VERSION ""

NS_ :

BS_:

BU_: BCM BSM2 CADM2 CVADAS EPS ORC PAM SGW TRSKM

BO_ 2564682031 DIAGNOSTIC_ROE_CADM2: 8 CADM2
 SG_ N_PDU : 7|64@0+ (1,0) [0|0] ""  SGW

BO_ 2564682032 DIAGNOSTIC_ROE_EPS: 8 EPS
 SG_ N_PDU : 7|64@0+ (1,0) [0|0] ""  SGW

BO_ 2564682275 DIAGNOSTIC_ROE_FD_BSM2: 64 BSM2
 SG_ N_PDU : 7|64@0+ (1,0) [0|0] ""  SGW

BO_ 2564682287 DIAGNOSTIC_ROE_FD_CADM2: 64 CADM2
 SG_ N_PDU : 7|64@0+ (1,0) [0|0] ""  SGW

BO_ 2564682288 DIAGNOSTIC_ROE_FD_EPS: 64 EPS
 SG_ N_PDU : 7|64@0+ (1,0) [0|0] ""  SGW

BO_ 2564682432 DIAGNOSTIC_ROE_FD_ORC: 64 ORC
 SG_ N_PDU : 7|64@0+ (1,0) [0|0] ""  SGW

BO_ 2564682400 DIAGNOSTIC_ROE_FD_PAM: 64 PAM
 SG_ N_PDU : 7|64@0+ (1,0) [0|0] ""  SGW

BO_ 2564682476 DIAGNOSTIC_ROE_FD_TRLR_REV: 64 TRSKM
 SG_ N_PDU : 7|64@0+ (1,0) [0|0] ""  SGW

BO_ 2564682176 DIAGNOSTIC_ROE_ORC: 8 ORC
 SG_ N_PDU : 7|64@0+ (1,0) [0|0] ""  SGW

BO_ 2564682144 DIAGNOSTIC_ROE_PAM: 8 PAM
 SG_ N_PDU : 7|64@0+ (1,0) [0|0] ""  SGW

BO_ 2564682220 DIAGNOSTIC_ROE_TRLR_REV: 8 TRSKM
 SG_ N_PDU : 7|64@0+ (1,0) [0|0] ""  SGW

BO_ 517 DRIVETRAIN_FD_1: 32 BCM
 SG_ AWDSysStat : 87|3@0+ (1,0) [0|7] "-"  BSM2,ORC
 SG_ CCMFailSts : 83|1@0+ (1,0) [0|1] "-"  BSM2,ORC
 SG_ CRC_DRIVETRAIN1 : 191|8@0+ (1,0) [0|255] "-"  BSM2
 SG_ Ft_RrCouplingTrq_Actual : 103|8@0+ (12,0) [1|3000] "Nm"  BSM2
 SG_ MessageCounter_DRIVETRAIN1 : 179|4@0+ (1,0) [0|15] "-"  BSM2

BO_ 1068 DRIVETRAIN_FD_3: 32 BCM
 SG_ CRC__DRIVETRAIN3 : 191|8@0+ (1,0) [0|255] "-"  BSM2,CVADAS,EPS
 SG_ MessageCounter_DRIVETRAIN3 : 179|4@0+ (1,0) [0|15] "-"  BSM2,CVADAS,EPS
 SG_ TCASERANGESTATUS : 89|2@0+ (1,0) [0|2] ""  CVADAS,EPS,PAM

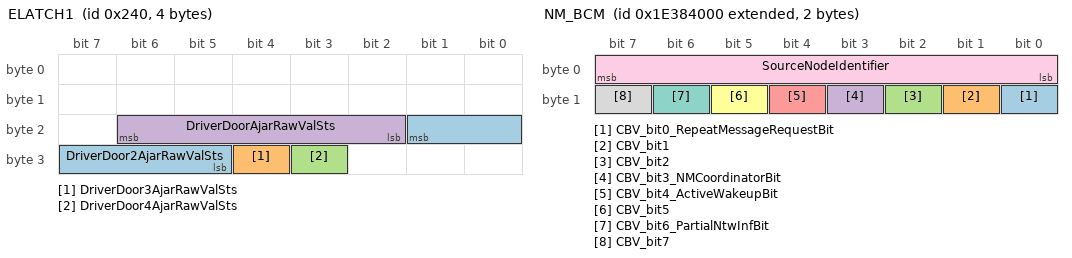
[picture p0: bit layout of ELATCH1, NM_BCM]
BO_ 576 ELATCH1: 4 BCM
 SG_ DriverDoor2AjarRawValSts : 17|5@0+ (1,0) [0|31] ""  ORC
 SG_ DriverDoor3AjarRawValSts : 28|1@0+ (1,0) [0|1] ""  ORC
 SG_ DriverDoor4AjarRawValSts : 27|1@0+ (1,0) [0|1] ""  ORC
 SG_ DriverDoorAjarRawValSts : 22|5@0+ (1,0) [0|31] ""  ORC

BO_ 1054 ENGINE_FD_1: 32 BCM
 SG_ BrkSw1Stat : 4|1@0+ (1,0) [0|1] "-"  ORC
 SG_ BrkSw2Stat : 5|1@0+ (1,0) [0|1] "-"  ORC
 SG_ ESP_TrqRqEnabl : 6|1@0+ (1,0) [0|1] "-"  ORC
 SG_ Lv1CrsCtrlOff : 7|1@0+ (1,0) [0|1] "-"  ORC
 SG_ RawPVS1 : 167|8@0+ (0.019607843,0) [0|4.98] "V"  ORC
 SG_ RawPVS2 : 175|8@0+ (0.019607843,0) [0|4.98] "V"  ORC
 SG_ RawTPS1 : 63|8@0+ (0.019607843,0) [0|4.98] "V"  ORC
 SG_ RawTPS2 : 55|8@0+ (0.019607843,0) [0|4.98] "V"  ORC
 SG_ ThrottlePosition : 87|8@0+ (0.392,0) [0|99.96] "%"  ORC

BO_ 262 ENGINE_FD_2: 64 BCM
 SG_ CRC_ENGINE2 : 447|8@0+ (1,0) [0|255] "-"  CADM2,CVADAS,EPS,PAM
 SG_ EngineSpeed_W : 21|14@0+ (1,0) [0|16382] "1/min"  CADM2,EPS,ORC
 SG_ EngineSpeedFailSts_W : 168|1@0+ (1,0) [0|1] "-"  ORC
 SG_ EngineSts_W : 87|2@0+ (1,0) [0|3] "-"  CVADAS,EPS
 SG_ EngTrq_Enbl_Rq_TCM_W : 178|1@0+ (1,0) [0|1] "-"  ORC
 SG_ ESS_ENG_ST_W : 175|4@0+ (1,0) [0|15] "-"  CADM2,CVADAS,EPS,ORC,PAM
 SG_ ESS_RqShftPark_W : 115|1@0+ (1,0) [0|0] "-"  ORC
 SG_ GasPedalPositionFailSts_W : 169|1@0+ (1,0) [0|1] "-"  ORC
 SG_ MessageCounter_ENGINE2 : 435|4@0+ (1,0) [0|15] "-"  CADM2,CVADAS,EPS,PAM
 SG_ PowertrainPrplsnActv : 181|1@0+ (1,0) [0|1] ""  CADM2,EPS,ORC

BO_ 518 ENGINE_FD_5: 32 BCM
 SG_ CRC_ENGINE5 : 191|8@0+ (1,0) [0|255] "-"  CVADAS,BSM2,CADM2
 SG_ MessageCounter_ENGINE5 : 179|4@0+ (1,0) [0|15] "-"  CVADAS,BSM2,CADM2
 SG_ PdlPosActual : 87|8@0+ (0.4,0) [0|100] "%"  BSM2,CADM2,CVADAS,ORC

BO_ 751 ENGINE_FD_6: 32 BCM
 SG_ TerrainModeStat_ECM : 61|5@0+ (1,0) [0|30] ""  ORC

BO_ 1448 ENGINE_FD_7: 32 BCM
 SG_ CRC_ENGINE7 : 191|8@0+ (1,0) [0|255] "-"  CVADAS
 SG_ ECM_THA_Resp : 73|2@0+ (1,0) [0|2] "-"  CVADAS
 SG_ ECM_TRSC_Resp : 7|2@0+ (1,0) [0|2] "-"  CVADAS
 SG_ EMSFailSts : 82|2@0+ (1,0) [0|3] "-"  ORC
 SG_ ETCFailSts : 115|2@0+ (1,0) [0|3] "-"  ORC
 SG_ MessageCounter_ENGINE7 : 179|4@0+ (1,0) [0|15] "-"  CVADAS
 SG_ SpStDispstat : 53|6@0+ (1,0) [0|63] "-"  ORC
 SG_ SpStSwStat : 55|2@0+ (1,0) [0|3] "-"  ORC

BO_ 1055 ENGINE_FD_8: 32 BCM
 SG_ GF_Charge : 127|16@0+ (0.2,0) [0|13106.8] "mg/cycle/cyl"  ORC
 SG_ MAP_4_BAR : 96|9@0+ (0.8,0) [0|408] "kPa"  ORC

BO_ 264 EPS_FD_1: 32 EPS
 SG_ CRC_EPS1 : 191|8@0+ (1,0) [0|255] "-"  BCM,BSM2,CADM2,CVADAS,ORC,PAM
 SG_ ElectricSteeringFailSts : 37|1@0+ (1,0) [0|1] "-"  BCM,SGW
 SG_ EngineFanRequestActivation : 38|1@0+ (1,0) [0|1] "-"  BCM
 SG_ EPS_AsstStat : 55|3@0+ (1,0) [0|6] "-"  CADM2
 SG_ EPS_Curr : 87|8@0+ (1,-50) [-50|204] "Amp" Vector__XXX
 SG_ EPS_Hands_On_Sts : 67|1@0+ (1,0) [0|1] "-"  CADM2
 SG_ EPS_IMC_Fault : 68|1@0+ (1,0) [0|1] ""  CADM2
 SG_ EPSMotorTorque : 66|11@0+ (0.004882815,-5) [-5|4.99023949] "Nm"  CADM2
 SG_ HAS_LAT_CTRL_ResponseSts_2 : 98|3@0+ (1,0) [0|7] "-"  CADM2
 SG_ LwsAngle : 7|16@0+ (0.1,-720) [-720|720] "°"  BCM,BSM2,CADM2,CVADAS,ORC,PAM,SGW
 SG_ LwsAngleType : 52|2@0+ (1,0) [0|2] "-"  BCM,BSM2,CADM2,CVADAS,ORC,SGW
 SG_ LwsCalibration : 36|1@0+ (1,0) [0|1] "-"  BCM,BSM2,SGW
 SG_ LwsSpeed : 19|12@0+ (1,-2000) [-2000|2094] "°/s"  BCM,CADM2,CVADAS,PAM,SGW
 SG_ MessageCounter_EPS1 : 179|4@0+ (1,0) [0|15] "-"  BCM,BSM2,CADM2,CVADAS,ORC,PAM
 SG_ Steering_Column_Torque : 50|11@0+ (0.0078125,-8) [-8|7.984375] "NM"  CADM2,ORC
 SG_ Steering_OpStat_Sec : 108|3@0+ (1,0) [0|5] ""  CADM2,ORC

BO_ 1056 EPS_FD_2: 32 EPS
 SG_ CRC_EPS2 : 191|8@0+ (1,0) [0|255] "0"  CVADAS
 SG_ EPS_MODE_STAT : 7|3@0+ (1,0) [0|3] ""  ORC,SGW
 SG_ EPS_SteeringTouchStat : 4|1@0+ (1,0) [0|1] ""  CVADAS
 SG_ EPS_SteeringTouq_Resp : 3|2@0+ (1,0) [0|1] ""  CVADAS
 SG_ EPS_THA_DriverTorqueOverride : 1|2@0+ (1,0) [0|1] ""  CVADAS
 SG_ EPS_THA_SteeringTorqueResp : 13|3@0+ (1,0) [0|6] ""  CVADAS
 SG_ EPS_Warn_Disp_Rq : 87|3@0+ (1,0) [0|3] ""  BCM,ORC,SGW
 SG_ MessageCounter_EPS2 : 179|4@0+ (1,0) [0|15] "0"  CVADAS
 SG_ THA_SteeringTouchStat : 15|2@0+ (1,0) [0|1] ""  CVADAS

BO_ 1460 FOTA_MASTER: 32 SGW
 SG_ CADM2_Big_ECU_Package : 2|1@0+ (1,0) [0|1] ""  CADM2
 SG_ FOTA_Purge : 13|1@0+ (1,0) [0|1] ""  CADM2
 SG_ FOTA_Status : 7|4@0+ (1,0) [0|15] ""  CADM2,EPS,ORC
 SG_ Safe_State : 0|1@0+ (1,0) [0|1] ""  CADM2

BO_ 1847 FOTA_RSP_CADM2: 32 CADM2
 SG_ Big_ECU_Ready_CADM2 : 3|2@0+ (1,0) [0|3] ""  SGW
 SG_ Download_Status_CADM2 : 7|2@0+ (1,0) [0|3] ""  SGW
 SG_ Update_Status_CADM2 : 5|2@0+ (1,0) [0|3] ""  SGW

BO_ 525 GLOB_NAV_FD: 64 BCM
 SG_ CRC_GLOB_NAV : 447|8@0+ (1,0) [0|255] "-"  CADM2
 SG_ GNMM_Health : 7|4@0+ (1,0) [0|6] ""  CADM2
 SG_ MessageCounter_GLOB_NAV : 435|4@0+ (1,0) [0|15] "-"  CADM2

BO_ 526 GLOB_NAV_FD_C2: 32 CADM2
 SG_ Altitude_RMSE_C2 : 143|8@0+ (2,0) [0|506] "cm"  CVADAS
 SG_ CRC_GLOB_NAV_C2 : 191|8@0+ (1,0) [0|255] "-"  CVADAS
 SG_ DeltaTimestamp_IMUdata : 175|8@0+ (1,0) [0|253] "ms"  CVADAS
 SG_ Heading_Angle_C2 : 127|16@0+ (0.01,0) [0|360] "deg"  CVADAS
 SG_ LatAcceleration_C2 : 19|12@0+ (0.02,-40.96) [-40.96|40.92] "m/s2"  CVADAS
 SG_ Latitude_RMSE_C2 : 103|8@0+ (2,0) [0|506] "cm"  CVADAS
 SG_ LongAcceleration_C2 : 3|12@0+ (0.02,-40.96) [-40.96|40.92] "m/s2"  CVADAS
 SG_ Longitude_RMSE_C2 : 111|8@0+ (2,0) [0|506] "cm"  CVADAS
 SG_ MessageCounter_GLOB_NAV_C2 : 179|4@0+ (1,0) [0|15] "-"  CVADAS
 SG_ Pitch_RMSE_C2 : 159|8@0+ (2,0) [0|506] "deg"  CVADAS
 SG_ PitchRate_C2 : 83|12@0+ (0.08,-163.84) [-163.84|163.68] "deg/s"  CVADAS
 SG_ Roll_RMSE_C2 : 151|8@0+ (2,0) [0|506] "deg"  CVADAS
 SG_ RollRate_C2 : 67|12@0+ (0.08,-163.84) [-163.84|163.68] "deg/s"  CVADAS
 SG_ VerticalAcceleration_C2 : 35|12@0+ (0.02,-40.96) [-40.96|40.92] "m/s2"  CVADAS
 SG_ YawRate_C2 : 51|12@0+ (0.08,-163.84) [-163.84|163.68] "deg/s"  CVADAS
 SG_ YawRate_RMSE_C2 : 119|8@0+ (2,0) [0|506] "deg"  CVADAS

BO_ 266 HVBATTERY1: 32 BCM
 SG_ HVBatContactorSts : 23|3@0+ (1,0) [0|0] "-"  ORC

BO_ 1049 HYBRID_DISPLAY: 32 BCM
 SG_ HVBatterySOC_Display : 119|8@0+ (0.3922,0) [0|100] "%"  ORC

BO_ 276 HYBRID_POWERTRAIN1: 64 BCM
 SG_ PropulsionSystemActive : 408|1@0+ (1,0) [0|1] "-"  EPS

BO_ 269 HYBRID_POWERTRAIN2: 64 BCM
 SG_ BSGActualTorque : 257|10@0+ (0.32,-163.52) [-163.52|163.2] "Nm"  ORC
 SG_ ReqTorqueOverLayActive : 297|1@0+ (1,0) [0|1] "-"  ORC

BO_ 752 IBS3_DATA_1: 32 BCM
 SG_ CurrBattFailStatus : 103|1@0+ (1,0) [0|1] "" Vector__XXX
 SG_ IBS3_Error_Internal : 101|1@0+ (1,0) [0|1] "" Vector__XXX
 SG_ IBS3_Vbatt : 96|9@0+ (0.025,5) [5|17.75] "V"  ORC
 SG_ RsErrIBS3 : 100|1@0+ (1,0) [0|1] "" Vector__XXX
 SG_ VoltBattFailStatus : 102|1@0+ (1,0) [0|1] "" Vector__XXX

BO_ 754 IBS3_DATA_1_2: 32 BCM
 SG_ CurrBattFailStatus_2 : 103|1@0+ (1,0) [0|1] "" Vector__XXX
 SG_ IBS3_Error_Internal_2 : 101|1@0+ (1,0) [0|1] "" Vector__XXX
 SG_ IBS3_Ibatt_2 : 87|16@0+ (0.02,-1000) [-1000|310.68] "A" Vector__XXX
 SG_ IBS3_Vbatt_2 : 96|9@0+ (0.025,5) [5|17.75] "V" Vector__XXX
 SG_ RsErrIBS3_2 : 100|1@0+ (1,0) [0|1] "" Vector__XXX
 SG_ VoltBattFailStatus_2 : 102|1@0+ (1,0) [0|1] "" Vector__XXX

BO_ 1955 IBS3_DATA_2: 32 BCM
 SG_ IBS3_CRC_IBS_1 : 15|8@0+ (1,0) [0|254] ""  CADM2
 SG_ IBS3_CRC_IBS_2 : 71|8@0+ (1,0) [0|254] ""  CADM2
 SG_ IBS3_FLAG_DISCONNECT_ADAS : 1|2@0+ (1,0) [0|2] "" Vector__XXX
 SG_ IBS3_FLAG_DISCONNECT_ADAS_2 : 17|2@0+ (1,0) [0|2] "" Vector__XXX
 SG_ IBS3_IBS_ADAS_OK : 3|2@0+ (1,0) [0|2] ""  CADM2
 SG_ IBS3_IBS_ADAS_OK_2 : 19|2@0+ (1,0) [0|2] ""  CADM2
 SG_ IBS3_MC_IBS_1 : 7|4@0+ (1,0) [0|15] ""  CADM2
 SG_ IBS3_MC_IBS_2 : 23|4@0+ (1,0) [0|15] ""  CADM2
 SG_ IBS3_SOC : 86|7@0+ (1,0) [0|100] "%"  ORC
 SG_ IBS3_SOC_Accuracy : 87|1@0+ (1,0) [0|1] "" Vector__XXX

BO_ 1957 IBS3_DATA_2_2: 32 BCM
 SG_ IBS3_FLAG_DISCONNECT_2 : 117|1@0+ (1,0) [0|0] "" Vector__XXX
 SG_ IBS3_Q_Received_2 : 159|16@0+ (0.125,0) [0|8191.75] "Ah" Vector__XXX
 SG_ IBS3_Q_Released_2 : 31|16@0+ (0.125,0) [0|8191.75] "Ah" Vector__XXX
 SG_ IBS3_R_Batt_2 : 63|8@0+ (0.1,0) [0|25.4] "mOhm" Vector__XXX
 SG_ IBS3_R_Batt_25_2 : 79|8@0+ (0.1,0) [0|25.4] "mOhm" Vector__XXX
 SG_ IBS3_SOC_2 : 86|7@0+ (1,0) [0|100] "%"  SGW
 SG_ IBS3_SOC_Accuracy_2 : 87|1@0+ (1,0) [0|0] ""  SGW
 SG_ IBS3_SOF_Q_2 : 103|8@0+ (1,0) [0|254] "Ah" Vector__XXX
 SG_ IBS3_SOF_Q_Accuracy_2 : 118|1@0+ (1,0) [0|0] "" Vector__XXX
 SG_ IBS3_SOH_COR_2 : 46|7@0+ (1,0) [0|100] "%" Vector__XXX
 SG_ IBS3_SOH_COR_Accuracy_2 : 47|1@0+ (1,0) [0|0] "" Vector__XXX
 SG_ IBS3_SOH_Q_2 : 110|7@0+ (2,0) [0|252] "Ah" Vector__XXX
 SG_ IBS3_SOH_Q_Accuracy_2 : 119|1@0+ (1,0) [0|0] "" Vector__XXX
 SG_ IBS3_SOH_SUL_2 : 54|7@0+ (1,0) [0|100] "%" Vector__XXX
 SG_ IBS3_SOH_SUL_Accuracy_2 : 55|1@0+ (1,0) [0|0] "" Vector__XXX
 SG_ IBS3_T_BATT_2 : 95|8@0+ (1,-40) [-40|105] "°C"  SGW
 SG_ IBS3_TempFailStatus_2 : 111|1@0+ (1,0) [0|0] ""  SGW
 SG_ IBS3_TmLstResetDays_2 : 139|12@0+ (1,0) [0|4094] "Days" Vector__XXX
 SG_ IBS3_TmLstResetSec_2 : 127|16@0+ (2,0) [0|86398] "sec" Vector__XXX

BO_ 1626 IMPACT_INFO: 32 ORC
 SG_ CRC_IMPACTINFO : 191|8@0+ (1,0) [0|255] "-"  BCM,SGW
 SG_ IMPACT_B : 84|1@0+ (1,0) [0|1] "-"  CADM2,SGW
 SG_ IMPACT_C : 85|1@0+ (1,0) [0|1] "-"  CADM2,SGW
 SG_ IMPACT_F : 88|1@0+ (1,0) [0|1] "-"  CADM2,SGW
 SG_ IMPACT_I : 91|1@0+ (1,0) [0|1] "-"  CADM2,SGW
 SG_ IMPACT_K : 92|1@0+ (1,0) [0|1] "-"  CADM2,SGW
 SG_ IMPACT_M : 94|1@0+ (1,0) [0|1] "-"  CADM2,SGW
 SG_ IMPACTCommand : 80|1@0+ (1,0) [0|1] "-"  BCM,CADM2,SGW
 SG_ IMPACTConfirm : 81|1@0+ (1,0) [0|1] "-"  BCM,CADM2,SGW
 SG_ IMPACTFailSts : 82|1@0+ (1,0) [0|1] "-"  SGW
 SG_ IMPACTThreshold : 103|1@0+ (1,0) [0|1] "-"  BCM
 SG_ MessageCounter_IMPACTINFO : 179|4@0+ (1,0) [0|15] "-"  BCM,SGW

BO_ 1829 IPC_FD_1: 32 BCM
 SG_ CRC_IPC1 : 191|8@0+ (1,0) [0|255] "-"  BSM2,CADM2
 SG_ MessageCounter_IPC1 : 179|4@0+ (1,0) [0|15] "-"  BSM2,CADM2
 SG_ TotalOdometer : 75|20@0+ (1,0) [0|1048575] "km"  BSM2,CADM2,CVADAS,EPS,ORC,PAM,TRSKM

BO_ 600 IPC_FD_4: 32 BCM
 SG_ AirBagLamp_FailSts : 143|2@0+ (1,0) [0|3] "-"  ORC

BO_ 1432 IPC_FD_6: 32 BCM
 SG_ CRC_IPC6 : 191|8@0+ (1,0) [0|255] "-"  CADM2
 SG_ HAS_SoH_IPC : 76|1@0+ (1,0) [0|1] ""  CADM2
 SG_ MessageCounter_IPC6 : 179|4@0+ (1,0) [0|15] "-"  CADM2

BO_ 1443 IPC_VEHICLE_SETUP: 48 BCM
 SG_ Act_Lane_Mgt : 91|2@0+ (1,0) [0|3] "-"  ORC
 SG_ Act_Lane_Mgt_Strength : 123|2@0+ (1,0) [0|3] "-"  ORC
 SG_ Active_Park_Mode : 219|1@0+ (1,0) [0|1] ""  CVADAS
 SG_ Backup_Cam_Delay : 173|1@0+ (1,0) [0|1] "-"  CVADAS
 SG_ DynamicGrid : 100|1@0+ (1,0) [0|1] ""  CVADAS
 SG_ Fwrd_Cam_Guidelines : 189|1@0+ (1,0) [0|1] "-"  CVADAS
 SG_ LanguageSelection : 135|8@0+ (1,0) [0|255] "-"  CVADAS
 SG_ LDW_Intensity : 154|2@0+ (1,0) [0|3] "-"  ORC
 SG_ LDW_Sensibility : 147|2@0+ (1,0) [0|3] "-"  ORC
 SG_ PamChimeVolumeFront : 107|2@0+ (1,0) [0|3] ""  CVADAS,PAM
 SG_ PamChimeVolumeRear : 111|2@0+ (1,0) [0|3] ""  CVADAS,PAM
 SG_ Rear_Brk_Asst : 190|1@0+ (1,0) [0|1] ""  CVADAS,PAM
 SG_ SVC_Guidelines : 193|1@0+ (1,0) [0|1] ""  CVADAS

BO_ 2654486528 NM_BCM: 2 BCM
 SG_ CBV_bit0_RepeatMessageRequestBit : 8|1@0+ (1,0) [0|1] ""  BSM2,CADM2,CVADAS,EPS,ORC,SGW,TRSKM
 SG_ CBV_bit1 : 9|1@0+ (1,0) [0|1] ""  BSM2,CADM2,CVADAS,EPS,ORC,SGW,TRSKM
 SG_ CBV_bit2 : 10|1@0+ (1,0) [0|1] ""  BSM2,CADM2,CVADAS,EPS,ORC,SGW,TRSKM
 SG_ CBV_bit3_NMCoordinatorBit : 11|1@0+ (1,0) [0|1] ""  BSM2,CADM2,CVADAS,EPS,ORC,SGW,TRSKM
 SG_ CBV_bit4_ActiveWakeupBit : 12|1@0+ (1,0) [0|1] ""  BSM2,CADM2,CVADAS,EPS,ORC,SGW,TRSKM
 SG_ CBV_bit5 : 13|1@0+ (1,0) [0|1] ""  BSM2,CADM2,CVADAS,EPS,ORC,SGW,TRSKM
 SG_ CBV_bit6_PartialNtwInfBit : 14|1@0+ (1,0) [0|1] ""  BSM2,CADM2,CVADAS,EPS,ORC,SGW,TRSKM
 SG_ CBV_bit7 : 15|1@0+ (1,0) [0|1] ""  BSM2,CADM2,CVADAS,EPS,ORC,SGW,TRSKM
 SG_ SourceNodeIdentifier : 7|8@0+ (1,0) [0|255] "-"  BSM2,CADM2,CVADAS,EPS,ORC,SGW,TRSKM

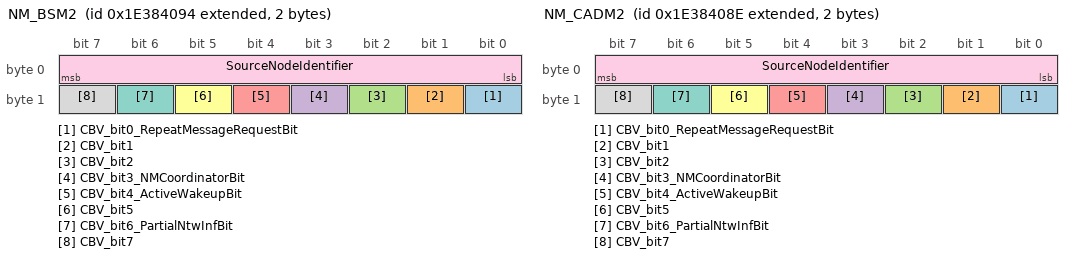
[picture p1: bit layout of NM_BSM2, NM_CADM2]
BO_ 2654486676 NM_BSM2: 2 BSM2
 SG_ CBV_bit0_RepeatMessageRequestBit : 8|1@0+ (1,0) [0|1] ""  BCM,CADM2,CVADAS,EPS,ORC,SGW,TRSKM
 SG_ CBV_bit1 : 9|1@0+ (1,0) [0|1] ""  BCM,CADM2,CVADAS,EPS,ORC,SGW,TRSKM
 SG_ CBV_bit2 : 10|1@0+ (1,0) [0|1] ""  BCM,CADM2,CVADAS,EPS,ORC,SGW,TRSKM
 SG_ CBV_bit3_NMCoordinatorBit : 11|1@0+ (1,0) [0|1] ""  BCM,CADM2,CVADAS,EPS,ORC,SGW,TRSKM
 SG_ CBV_bit4_ActiveWakeupBit : 12|1@0+ (1,0) [0|1] ""  BCM,CADM2,CVADAS,EPS,ORC,SGW,TRSKM
 SG_ CBV_bit5 : 13|1@0+ (1,0) [0|1] ""  BCM,CADM2,CVADAS,EPS,ORC,SGW,TRSKM
 SG_ CBV_bit6_PartialNtwInfBit : 14|1@0+ (1,0) [0|1] ""  BCM,CADM2,CVADAS,EPS,ORC,SGW,TRSKM
 SG_ CBV_bit7 : 15|1@0+ (1,0) [0|1] ""  BCM,CADM2,CVADAS,EPS,ORC,SGW,TRSKM
 SG_ SourceNodeIdentifier : 7|8@0+ (1,0) [0|255] "-"  BCM,CADM2,CVADAS,EPS,ORC,SGW,TRSKM

BO_ 2654486670 NM_CADM2: 2 CADM2
 SG_ CBV_bit0_RepeatMessageRequestBit : 8|1@0+ (1,0) [0|1] ""  BCM,BSM2,CVADAS,EPS,ORC,SGW,TRSKM
 SG_ CBV_bit1 : 9|1@0+ (1,0) [0|1] ""  BCM,BSM2,CVADAS,EPS,ORC,SGW,TRSKM
 SG_ CBV_bit2 : 10|1@0+ (1,0) [0|1] ""  BCM,BSM2,CVADAS,EPS,ORC,SGW,TRSKM
 SG_ CBV_bit3_NMCoordinatorBit : 11|1@0+ (1,0) [0|1] ""  BCM,BSM2,CVADAS,EPS,ORC,SGW,TRSKM
 SG_ CBV_bit4_ActiveWakeupBit : 12|1@0+ (1,0) [0|1] ""  BCM,BSM2,CVADAS,EPS,ORC,SGW,TRSKM
 SG_ CBV_bit5 : 13|1@0+ (1,0) [0|1] ""  BCM,BSM2,CVADAS,EPS,ORC,SGW,TRSKM
 SG_ CBV_bit6_PartialNtwInfBit : 14|1@0+ (1,0) [0|1] ""  BCM,BSM2,CVADAS,EPS,ORC,SGW,TRSKM
 SG_ CBV_bit7 : 15|1@0+ (1,0) [0|1] ""  BCM,BSM2,CVADAS,EPS,ORC,SGW,TRSKM
 SG_ SourceNodeIdentifier : 7|8@0+ (1,0) [0|255] "-"  BCM,BSM2,CVADAS,EPS,ORC,SGW,TRSKM

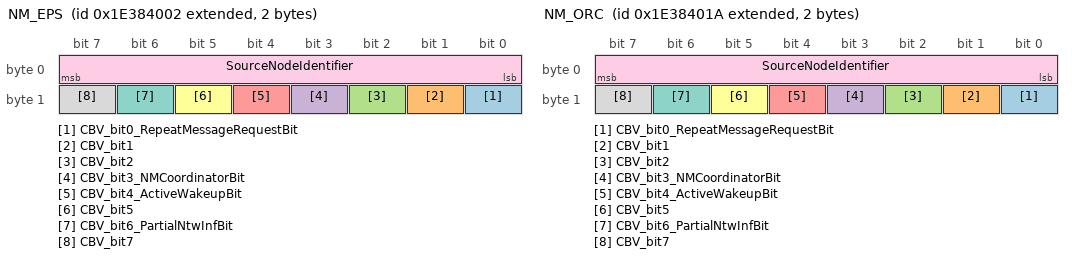
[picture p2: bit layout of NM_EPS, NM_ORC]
BO_ 2654486530 NM_EPS: 2 EPS
 SG_ CBV_bit0_RepeatMessageRequestBit : 8|1@0+ (1,0) [0|1] ""  BCM,BSM2,CADM2,CVADAS,ORC,SGW,TRSKM
 SG_ CBV_bit1 : 9|1@0+ (1,0) [0|1] ""  BCM,BSM2,CADM2,CVADAS,ORC,SGW,TRSKM
 SG_ CBV_bit2 : 10|1@0+ (1,0) [0|1] ""  BCM,BSM2,CADM2,CVADAS,ORC,SGW,TRSKM
 SG_ CBV_bit3_NMCoordinatorBit : 11|1@0+ (1,0) [0|1] ""  BCM,BSM2,CADM2,CVADAS,ORC,SGW,TRSKM
 SG_ CBV_bit4_ActiveWakeupBit : 12|1@0+ (1,0) [0|1] ""  BCM,BSM2,CADM2,CVADAS,ORC,SGW,TRSKM
 SG_ CBV_bit5 : 13|1@0+ (1,0) [0|1] ""  BCM,BSM2,CADM2,CVADAS,ORC,SGW,TRSKM
 SG_ CBV_bit6_PartialNtwInfBit : 14|1@0+ (1,0) [0|1] ""  BCM,BSM2,CADM2,CVADAS,ORC,SGW,TRSKM
 SG_ CBV_bit7 : 15|1@0+ (1,0) [0|1] ""  BCM,BSM2,CADM2,CVADAS,ORC,SGW,TRSKM
 SG_ SourceNodeIdentifier : 7|8@0+ (1,0) [0|255] "-"  BCM,BSM2,CADM2,CVADAS,ORC,SGW,TRSKM

BO_ 2654486554 NM_ORC: 2 ORC
 SG_ CBV_bit0_RepeatMessageRequestBit : 8|1@0+ (1,0) [0|1] ""  BCM,BSM2,CADM2,CVADAS,EPS,SGW,TRSKM
 SG_ CBV_bit1 : 9|1@0+ (1,0) [0|1] ""  BCM,BSM2,CADM2,CVADAS,EPS,SGW,TRSKM
 SG_ CBV_bit2 : 10|1@0+ (1,0) [0|1] ""  BCM,BSM2,CADM2,CVADAS,EPS,SGW,TRSKM
 SG_ CBV_bit3_NMCoordinatorBit : 11|1@0+ (1,0) [0|1] ""  BCM,BSM2,CADM2,CVADAS,EPS,SGW,TRSKM
 SG_ CBV_bit4_ActiveWakeupBit : 12|1@0+ (1,0) [0|1] ""  BCM,BSM2,CADM2,CVADAS,EPS,SGW,TRSKM
 SG_ CBV_bit5 : 13|1@0+ (1,0) [0|1] ""  BCM,BSM2,CADM2,CVADAS,EPS,SGW,TRSKM
 SG_ CBV_bit6_PartialNtwInfBit : 14|1@0+ (1,0) [0|1] ""  BCM,BSM2,CADM2,CVADAS,EPS,SGW,TRSKM
 SG_ CBV_bit7 : 15|1@0+ (1,0) [0|1] ""  BCM,BSM2,CADM2,CVADAS,EPS,SGW,TRSKM
 SG_ SourceNodeIdentifier : 7|8@0+ (1,0) [0|255] "-"  BCM,BSM2,CADM2,CVADAS,EPS,SGW,TRSKM

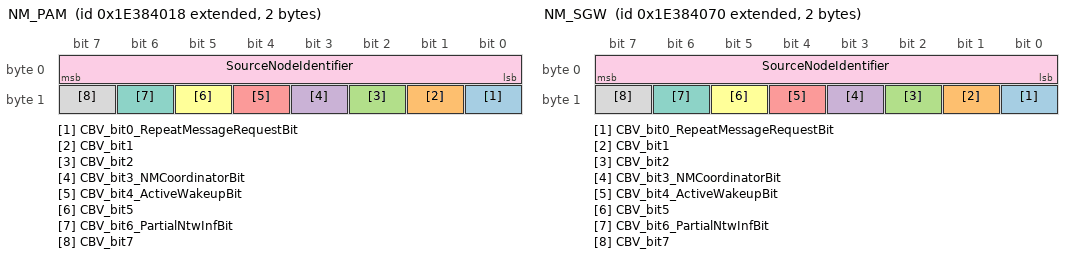
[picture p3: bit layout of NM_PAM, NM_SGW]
BO_ 2654486552 NM_PAM: 2 CVADAS
 SG_ CBV_bit0_RepeatMessageRequestBit : 8|1@0+ (1,0) [0|1] ""  BCM,BSM2,CADM2,EPS,ORC,SGW,TRSKM
 SG_ CBV_bit1 : 9|1@0+ (1,0) [0|1] ""  BCM,BSM2,CADM2,EPS,ORC,SGW,TRSKM
 SG_ CBV_bit2 : 10|1@0+ (1,0) [0|1] ""  BCM,BSM2,CADM2,EPS,ORC,SGW,TRSKM
 SG_ CBV_bit3_NMCoordinatorBit : 11|1@0+ (1,0) [0|1] ""  BCM,BSM2,CADM2,EPS,ORC,SGW,TRSKM
 SG_ CBV_bit4_ActiveWakeupBit : 12|1@0+ (1,0) [0|1] ""  BCM,BSM2,CADM2,EPS,ORC,SGW,TRSKM
 SG_ CBV_bit5 : 13|1@0+ (1,0) [0|1] ""  BCM,BSM2,CADM2,EPS,ORC,SGW,TRSKM
 SG_ CBV_bit6_PartialNtwInfBit : 14|1@0+ (1,0) [0|1] ""  BCM,BSM2,CADM2,EPS,ORC,SGW,TRSKM
 SG_ CBV_bit7 : 15|1@0+ (1,0) [0|1] ""  BCM,BSM2,CADM2,EPS,ORC,SGW,TRSKM
 SG_ SourceNodeIdentifier : 7|8@0+ (1,0) [0|255] "-"  BCM,BSM2,CADM2,EPS,ORC,SGW,TRSKM

BO_ 2654486640 NM_SGW: 2 SGW
 SG_ CBV_bit0_RepeatMessageRequestBit : 8|1@0+ (1,0) [0|1] ""  BCM,BSM2,CADM2,CVADAS,EPS,ORC,TRSKM
 SG_ CBV_bit1 : 9|1@0+ (1,0) [0|1] ""  BCM,BSM2,CADM2,CVADAS,EPS,ORC,TRSKM
 SG_ CBV_bit2 : 10|1@0+ (1,0) [0|1] ""  BCM,BSM2,CADM2,CVADAS,EPS,ORC,TRSKM
 SG_ CBV_bit3_NMCoordinatorBit : 11|1@0+ (1,0) [0|1] ""  BCM,BSM2,CADM2,CVADAS,EPS,ORC,TRSKM
 SG_ CBV_bit4_ActiveWakeupBit : 12|1@0+ (1,0) [0|1] ""  BCM,BSM2,CADM2,CVADAS,EPS,ORC,TRSKM
 SG_ CBV_bit5 : 13|1@0+ (1,0) [0|1] ""  BCM,BSM2,CADM2,CVADAS,EPS,ORC,TRSKM
 SG_ CBV_bit6_PartialNtwInfBit : 14|1@0+ (1,0) [0|1] ""  BCM,BSM2,CADM2,CVADAS,EPS,ORC,TRSKM
 SG_ CBV_bit7 : 15|1@0+ (1,0) [0|1] ""  BCM,BSM2,CADM2,CVADAS,EPS,ORC,TRSKM
 SG_ SourceNodeIdentifier : 7|8@0+ (1,0) [0|255] "-"  BCM,BSM2,CADM2,CVADAS,EPS,ORC,TRSKM

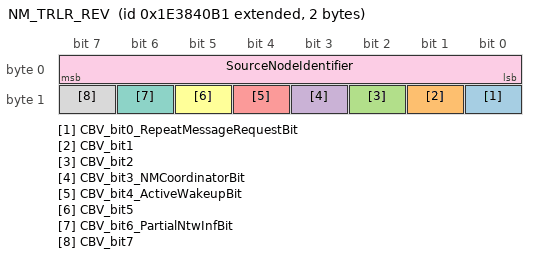
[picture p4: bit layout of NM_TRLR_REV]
BO_ 2654486705 NM_TRLR_REV: 2 TRSKM
 SG_ CBV_bit0_RepeatMessageRequestBit : 8|1@0+ (1,0) [0|1] ""  BCM,BSM2,CADM2,CVADAS,EPS,ORC,SGW
 SG_ CBV_bit1 : 9|1@0+ (1,0) [0|1] ""  BCM,BSM2,CADM2,CVADAS,EPS,ORC,SGW
 SG_ CBV_bit2 : 10|1@0+ (1,0) [0|1] ""  BCM,BSM2,CADM2,CVADAS,EPS,ORC,SGW
 SG_ CBV_bit3_NMCoordinatorBit : 11|1@0+ (1,0) [0|1] ""  BCM,BSM2,CADM2,CVADAS,EPS,ORC,SGW
 SG_ CBV_bit4_ActiveWakeupBit : 12|1@0+ (1,0) [0|1] ""  BCM,BSM2,CADM2,CVADAS,EPS,ORC,SGW
 SG_ CBV_bit5 : 13|1@0+ (1,0) [0|1] ""  BCM,BSM2,CADM2,CVADAS,EPS,ORC,SGW
 SG_ CBV_bit6_PartialNtwInfBit : 14|1@0+ (1,0) [0|1] ""  BCM,BSM2,CADM2,CVADAS,EPS,ORC,SGW
 SG_ CBV_bit7 : 15|1@0+ (1,0) [0|1] ""  BCM,BSM2,CADM2,CVADAS,EPS,ORC,SGW
 SG_ SourceNodeIdentifier : 7|8@0+ (1,0) [0|255] "-"  BCM,BSM2,CADM2,CVADAS,EPS,ORC,SGW

BO_ 611 ORC_FD_1: 32 ORC
 SG_ AirBagFailSts : 137|2@0+ (1,0) [0|3] "-"  BCM,SGW
 SG_ CRC_ORC1 : 191|8@0+ (1,0) [0|255] "-"  CVADAS,BCM
 SG_ MessageCounter_ORC1 : 179|4@0+ (1,0) [0|15] "-"  CVADAS,BCM
 SG_ SBR1RowDriverSeatConfigSts : 92|1@0+ (1,0) [0|1] "-"  BCM
 SG_ SBR1RowDriverSeatSts : 94|2@0+ (1,0) [0|2] "-"  BCM,CVADAS,SGW
 SG_ SBR1RowPsngrSeatConfigSts : 95|1@0+ (1,0) [0|1] "-"  BCM,SGW
 SG_ SBR1RowPsngrSeatSts : 98|3@0+ (1,0) [0|6] "-"  BCM,SGW

BO_TX_BU_ 2564682400 : CVADAS,PAM;
BO_TX_BU_ 2564682144 : CVADAS,PAM;
CM_ SG_ 2564682031 N_PDU "This signal is used for diagnostic purposes";
CM_ SG_ 2564682032 N_PDU "This signal is used for diagnostic purposes";
CM_ SG_ 2564682275 N_PDU "This signal is used for diagnostic purposes";
CM_ SG_ 2564682287 N_PDU "This signal is used for diagnostic purposes";
CM_ SG_ 2564682288 N_PDU "This signal is used for diagnostic purposes";
CM_ SG_ 2564682432 N_PDU "This signal is used for diagnostic purposes";
CM_ SG_ 2564682400 N_PDU "This signal is used for diagnostic purposes";
CM_ SG_ 2564682476 N_PDU "This signal is used for diagnostic purposes";
CM_ SG_ 2564682176 N_PDU "This signal is used for diagnostic purposes";
CM_ SG_ 2564682144 N_PDU "This signal is used for diagnostic purposes";
CM_ SG_ 2564682220 N_PDU "This signal is used for diagnostic purposes";
CM_ SG_ 517 AWDSysStat "-";
CM_ SG_ 517 CCMFailSts "-";
CM_ SG_ 517 CRC_DRIVETRAIN1 "CRC according to SAE J1850 standard at each frame transmission.";
CM_ SG_ 517 Ft_RrCouplingTrq_Actual "-";
CM_ SG_ 517 MessageCounter_DRIVETRAIN1 "This signal is a counter used for safety checks strategies. This counter is incremented of 1 (one) unit at each frame transmission.";
CM_ SG_ 1068 CRC__DRIVETRAIN3 "CRC according to SAE J1850 standard at each frame transmission.";
CM_ SG_ 1068 MessageCounter_DRIVETRAIN3 "This signal is a counter used for safety checks strategies. This counter is incremented of 1 (one) unit at each frame transmission.";
CM_ SG_ 1068 TCASERANGESTATUS "This signal is used for update the Transfer case Range status";
CM_ SG_ 576 DriverDoor2AjarRawValSts "This signal is used to give information about the Driver Door Aux Pawl RAW current data.";
CM_ SG_ 576 DriverDoor3AjarRawValSts "This signal is used to give information about the Driver Door digital Pawl RAW current data.";
CM_ SG_ 576 DriverDoor4AjarRawValSts "This signal is used to give information about the Driver Door digital Open sensor RAW current data.";
CM_ SG_ 576 DriverDoorAjarRawValSts "This signal is used to give information about the Driver Door Ajar RAW current data.";
CM_ SG_ 1054 BrkSw1Stat "EDR ONLY - Brake switch1 status, off = [0]";
CM_ SG_ 1054 BrkSw2Stat "EDR ONLY - Brake switch2 status, off = [0]";
CM_ SG_ 1054 ESP_TrqRqEnabl "EDR ONLY - ESP torque requests are allowed = [1]";
CM_ SG_ 1054 Lv1CrsCtrlOff "EDR ONLY - Level is requested cruise off";
CM_ SG_ 1054 RawPVS1 "EDR ONLY - Raw pedal value sensor #1";
CM_ SG_ 1054 RawPVS2 "EDR ONLY - Raw pedal value sensor #2";
CM_ SG_ 1054 RawTPS1 "EDR ONLY - Raw throttle position sensor #1";
CM_ SG_ 1054 RawTPS2 "EDR ONLY - Raw throttle position sensor #2";
CM_ SG_ 1054 ThrottlePosition "GASOLINE APPLICATION ONLY This signal represents throttle position evaluated on the basis of throttle position sensor.";
CM_ SG_ 262 CRC_ENGINE2 "CRC according to SAE J1850 standard at each frame transmission.";
CM_ SG_ 262 EngineSpeed_W "It gives information on C-CAN network about  engine speed";
CM_ SG_ 262 EngineSpeedFailSts_W "Used to indicate if a Fail is present for the engine speed";
CM_ SG_ 262 EngineSts_W "-";
CM_ SG_ 262 EngTrq_Enbl_Rq_TCM_W "Allow TRANS torque request";
CM_ SG_ 262 ESS_ENG_ST_W "ESS Engine State";
CM_ SG_ 262 ESS_RqShftPark_W "ESS Request shift to Park.  1 = True, 0 = False";
CM_ SG_ 262 GasPedalPositionFailSts_W "-";
CM_ SG_ 262 MessageCounter_ENGINE2 "This signal is a counter used for safety checks strategies. This counter is incremented of 1 (one) unit at each frame transmission.";
CM_ SG_ 262 PowertrainPrplsnActv "Powertrain Propulsion Status.";
CM_ SG_ 518 CRC_ENGINE5 "CRC according to SAE J1850 standard at each frame transmission.";
CM_ SG_ 518 MessageCounter_ENGINE5 "This signal is a counter used for safety checks strategies. This counter is incremented of 1 (one) unit at each frame transmission.";
CM_ SG_ 518 PdlPosActual "Actual pedal position.";
CM_ SG_ 751 TerrainModeStat_ECM "Used to require a vehicle modality";
CM_ SG_ 1448 CRC_ENGINE7 "CRC according to SAE J1850 standard at each frame transmission.";
CM_ SG_ 1448 ECM_THA_Resp "ECM speed limiting availability response for trailer hitch assist";
CM_ SG_ 1448 ECM_TRSC_Resp "Engine break activation response";
CM_ SG_ 1448 EMSFailSts "This signal is used  to switch on and off the engine control system warning lamp (called MI for EOBD applications)";
CM_ SG_ 1448 ETCFailSts "This signal is used  to switch on and off  ETC lamp to give informations about faults not EOBD relevant.";
CM_ SG_ 1448 MessageCounter_ENGINE7 "This signal is a counter used for safety checks strategies. This counter is incremented of 1 (one) unit at each frame transmission.";
CM_ SG_ 1448 SpStDispstat "Stop start display status";
CM_ SG_ 1448 SpStSwStat "Stop start switch status";
CM_ SG_ 1055 GF_Charge "EDR ONLY - Port flow per cylinder per stroke";
CM_ SG_ 1055 MAP_4_BAR "Engine manifold pressure (4 bar range)";
CM_ SG_ 264 CRC_EPS1 "CRC according to SAE J1850 standard at each frame transmission.";
CM_ SG_ 264 ElectricSteeringFailSts "It indicates if system EPS has an internal fault.";
CM_ SG_ 264 EngineFanRequestActivation "This signal is used to activate the cooling fun by the electric power steering.";
CM_ SG_ 264 EPS_AsstStat "Electric Power Steering Assistance Status";
CM_ SG_ 264 EPS_Curr "Electric power steering current";
CM_ SG_ 264 EPS_Hands_On_Sts "EPS Hands on steering wheel status; Hands on steering wheel detected = [1]";
CM_ SG_ 264 EPS_IMC_Fault "Status of the EPS Intra-Module Communciation channel as reported by the secondary EPS unit";
CM_ SG_ 264 EPSMotorTorque "It represents the torque on the EPS motor output shaft at all times";
CM_ SG_ 264 HAS_LAT_CTRL_ResponseSts_2 "HAS LAT CTRL Response Sts on secondary EPS";
CM_ SG_ 264 LwsAngle "This signal indicates the steering angle value, counterclockwise positive.";
CM_ SG_ 264 LwsAngleType "This signal indicates whether the angle sensor is absolute (all the possible turns/degrees) or not absolute (relative, torque only, etc.).";
CM_ SG_ 264 LwsCalibration "This signal indicates if the sensor has been calibrated and therefore the steering angle value is exported over Can.";
CM_ SG_ 264 LwsSpeed "This signal indicates the steering speed value, counterclockwise positive.";
CM_ SG_ 264 MessageCounter_EPS1 "This signal is a counter used for safety checks strategies. This counter is incremented of 1 (one) unit at each frame transmission.";
CM_ SG_ 264 Steering_Column_Torque "Steering Column Torque";
CM_ SG_ 264 Steering_OpStat_Sec "Capability of the Steering system to steer the vehicle as reported by secondary actuator";
CM_ SG_ 1056 CRC_EPS2 "CRC according to SAE J1850 standard at each frame transmission.";
CM_ SG_ 1056 EPS_MODE_STAT "EPS mode personalization status";
CM_ SG_ 1056 EPS_SteeringTouchStat "EPS Driver interference during the TRSC event; True = [1] , False= [0]";
CM_ SG_ 1056 EPS_SteeringTouq_Resp "EPS steering torque overlay activation response";
CM_ SG_ 1056 EPS_THA_DriverTorqueOverride "Determines if EPS driver torque on hand wheel is large enough to  override THA";
CM_ SG_ 1056 EPS_THA_SteeringTorqueResp "EPS steering torque overlay availability response for trailer hitch assist";
CM_ SG_ 1056 EPS_Warn_Disp_Rq "Electric Power Steering Warning Display Request";
CM_ SG_ 1056 MessageCounter_EPS2 "This signal is a counter used for safety checks strategies. This counter is incremented of 1 (one) unit at each frame transmission.";
CM_ SG_ 1056 THA_SteeringTouchStat "EPS hands on status for trailer hitch assist";
CM_ SG_ 1460 CADM2_Big_ECU_Package "CADM2_Big_ECU_Package";
CM_ SG_ 1460 FOTA_Purge "Target ECUs to Purge Downloaded FOTA Images";
CM_ SG_ 1460 FOTA_Status "FOTA_Status";
CM_ SG_ 1460 Safe_State "Safe_State";
CM_ SG_ 1847 Big_ECU_Ready_CADM2 "Big_ECU_Ready_CADM2";
CM_ SG_ 1847 Download_Status_CADM2 "Download_Status_CADM2";
CM_ SG_ 1847 Update_Status_CADM2 "Update_Status_CADM2";
CM_ SG_ 525 CRC_GLOB_NAV "CRC according to SAE J1850 standard at each frame transmission.";
CM_ SG_ 525 GNMM_Health "Reported capability of GNMM to provide positioning and acceleration data";
CM_ SG_ 525 MessageCounter_GLOB_NAV "This signal is a counter used for safety checks strategies. This counter is incremented of 1 (one) unit at each frame transmission.";
CM_ SG_ 526 Altitude_RMSE_C2 "Altitude_RMSE";
CM_ SG_ 526 CRC_GLOB_NAV_C2 "CRC according to SAE J1850 standard at each frame transmission.";
CM_ SG_ 526 DeltaTimestamp_IMUdata "DeltaTimestamp_IMUdata";
CM_ SG_ 526 Heading_Angle_C2 "Heading Angle";
CM_ SG_ 526 LatAcceleration_C2 "Lateral Acceleration Value from the GNMM";
CM_ SG_ 526 Latitude_RMSE_C2 "RMS error for Latitude";
CM_ SG_ 526 LongAcceleration_C2 "Longitudinal Acceleration Value from the GNMM";
CM_ SG_ 526 Longitude_RMSE_C2 "RMS error for Longitude";
CM_ SG_ 526 MessageCounter_GLOB_NAV_C2 "This signal is a counter used for safety checks strategies. This counter is incremented of 1 (one) unit at each frame transmission.";
CM_ SG_ 526 Pitch_RMSE_C2 "Pitch_RMSE";
CM_ SG_ 526 PitchRate_C2 "Pitch Rate Value from the GNMM";
CM_ SG_ 526 Roll_RMSE_C2 "Roll_RMSE";
CM_ SG_ 526 RollRate_C2 "Roll Rate Value from the GNMM";
CM_ SG_ 526 VerticalAcceleration_C2 "Vertical Acceleration Value from the GNMM";
CM_ SG_ 526 YawRate_C2 "Yaw Rate Value from the GNMM";
CM_ SG_ 526 YawRate_RMSE_C2 "RMS error for YawRate";
CM_ SG_ 266 HVBatContactorSts "HV Battery pack contactor state";
CM_ SG_ 1049 HVBatterySOC_Display "High voltage battery state of charge";
CM_ SG_ 276 PropulsionSystemActive "Propulsion system active, [1] = active";
CM_ SG_ 269 BSGActualTorque "BSG Actual Torque";
CM_ SG_ 269 ReqTorqueOverLayActive "Regeneration Shift Schedule Request (1 = Active)";
CM_ SG_ 752 CurrBattFailStatus "Failure Status of Current meas. (internal defect)";
CM_ SG_ 752 IBS3_Error_Internal "Error in IBS calibration data; No Error = [0], Error = [1]";
CM_ SG_ 752 IBS3_Vbatt "Battery voltage measured at the terminals";
CM_ SG_ 752 RsErrIBS3 "Response Error IBS; Error=[1]";
CM_ SG_ 752 VoltBattFailStatus "Failure Status of Voltage meas. (internal defect)";
CM_ SG_ 754 CurrBattFailStatus_2 "Failure Status of Current meas. (internal defect)";
CM_ SG_ 754 IBS3_Error_Internal_2 "Error in IBS calibration data; No Error = [0], Error = [1]";
CM_ SG_ 754 IBS3_Ibatt_2 "Battery current";
CM_ SG_ 754 IBS3_Vbatt_2 "Battery voltage measured at the terminals";
CM_ SG_ 754 RsErrIBS3_2 "Response Error IBS; Error=[1]";
CM_ SG_ 754 VoltBattFailStatus_2 "Failure Status of Voltage meas. (internal defect)";
CM_ SG_ 1955 IBS3_CRC_IBS_1 "CRC";
CM_ SG_ 1955 IBS3_CRC_IBS_2 "CRC";
CM_ SG_ 1955 IBS3_FLAG_DISCONNECT_ADAS "IBS indicates that the reason for unknown values is a recent battery disconnection";
CM_ SG_ 1955 IBS3_FLAG_DISCONNECT_ADAS_2 "IBS indicates that the reason for unknown values is a recent battery disconnection";
CM_ SG_ 1955 IBS3_IBS_ADAS_OK "IBS indicates that battery is able to support ADAS operation";
CM_ SG_ 1955 IBS3_IBS_ADAS_OK_2 "IBS indicates that battery is able to support ADAS operation";
CM_ SG_ 1955 IBS3_MC_IBS_1 "Message Counter";
CM_ SG_ 1955 IBS3_MC_IBS_2 "Message Counter";
CM_ SG_ 1955 IBS3_SOC "State of charge";
CM_ SG_ 1955 IBS3_SOC_Accuracy "SOC accuracy status";
CM_ SG_ 1957 IBS3_FLAG_DISCONNECT_2 "Battery disconnection flag";
CM_ SG_ 1957 IBS3_Q_Received_2 "LifeTime charge received";
CM_ SG_ 1957 IBS3_Q_Released_2 "Lifetime charge released";
CM_ SG_ 1957 IBS3_R_Batt_2 "Calculated battery resistance";
CM_ SG_ 1957 IBS3_R_Batt_25_2 "Batt resistance at 100% SOC and 25 degC";
CM_ SG_ 1957 IBS3_SOC_2 "State of charge";
CM_ SG_ 1957 IBS3_SOC_Accuracy_2 "SOC accuracy status";
CM_ SG_ 1957 IBS3_SOF_Q_2 "Residual battery charge in Ah";
CM_ SG_ 1957 IBS3_SOF_Q_Accuracy_2 "SOF_Q accuracy status";
CM_ SG_ 1957 IBS3_SOH_COR_2 "Ageing related to voltage drop predicted for -18°C cold crank due to corrosion";
CM_ SG_ 1957 IBS3_SOH_COR_Accuracy_2 "SOH_COR accuracy status ( Inaccurate = 0 / Accurate = 1)";
CM_ SG_ 1957 IBS3_SOH_Q_2 "State of health related to capacity (energy)";
CM_ SG_ 1957 IBS3_SOH_Q_Accuracy_2 "SOH_Q accuracy status";
CM_ SG_ 1957 IBS3_SOH_SUL_2 "Maximum SOC available due to the fact that the battery could be sulphated";
CM_ SG_ 1957 IBS3_SOH_SUL_Accuracy_2 "SOH_SUL accuracy status ( Inaccurate = 0 / Accurate = 1)";
CM_ SG_ 1957 IBS3_T_BATT_2 "Battery temperature";
CM_ SG_ 1957 IBS3_TempFailStatus_2 "Failure of ASIC Temperature meas. (internal defect)";
CM_ SG_ 1957 IBS3_TmLstResetDays_2 "Accumulated time since last reset in days";
CM_ SG_ 1957 IBS3_TmLstResetSec_2 "Accumulated time since last reset in seconds";
CM_ SG_ 1626 CRC_IMPACTINFO "CRC according to SAE J1850 standard at each frame transmission.";
CM_ SG_ 1626 IMPACT_B "EARS Rear Event";
CM_ SG_ 1626 IMPACT_C "EARS Higher Severity Front Event";
CM_ SG_ 1626 IMPACT_F "EARS Lower Severity Front Event";
CM_ SG_ 1626 IMPACT_I "EARS RolloverEvent";
CM_ SG_ 1626 IMPACT_K "EARS Driver/Left Side Event";
CM_ SG_ 1626 IMPACT_M "EARS Passenger/Right Side Event";
CM_ SG_ 1626 IMPACTCommand "This signal is used to indicate that a crash happened";
CM_ SG_ 1626 IMPACTConfirm "This signal is used to confirm that a crash happened";
CM_ SG_ 1626 IMPACTFailSts "This signal is used to inform that an internal fault is present in the ORC";
CM_ SG_ 1626 IMPACTThreshold "Upon a crash, the ORC Calibration Threshold was either \"Met\" or \"Not_Met\".";
CM_ SG_ 1626 MessageCounter_IMPACTINFO "This signal is a counter used for safety checks strategies. This counter is incremented of 1 (one) unit at each frame transmission.";
CM_ SG_ 1829 CRC_IPC1 "CRC according to SAE J1850 standard at each frame transmission.";
CM_ SG_ 1829 MessageCounter_IPC1 "This signal is a counter used for safety checks strategies. This counter is incremented of 1 (one) unit at each frame transmission.";
CM_ SG_ 1829 TotalOdometer "Used to give information about the total odometer value in km.";
CM_ SG_ 600 AirBagLamp_FailSts "This signal is used to inform about the airbag warning light status";
CM_ SG_ 1432 CRC_IPC6 "CRC according to SAE J1850 standard at each frame transmission.";
CM_ SG_ 1432 HAS_SoH_IPC "HAS SoH IPC";
CM_ SG_ 1432 MessageCounter_IPC6 "This signal is a counter used for safety checks strategies. This counter is incremented of 1 (one) unit at each frame transmission.";
CM_ SG_ 1443 Act_Lane_Mgt "Act Lane Mgt setting";
CM_ SG_ 1443 Act_Lane_Mgt_Strength "Act Lane Mgt Strength setting";
CM_ SG_ 1443 Active_Park_Mode "Active Parksense Mode setting";
CM_ SG_ 1443 Backup_Cam_Delay "Backup Camera Delay setting";
CM_ SG_ 1443 DynamicGrid "Rear View Camera Dynamic Gridlines request";
CM_ SG_ 1443 Fwrd_Cam_Guidelines "Forward Facing Camera Guidelines setting";
CM_ SG_ 1443 LanguageSelection "This signal is used to give information about the Language selected";
CM_ SG_ 1443 LDW_Intensity "This signal is used to give information about the LDW Intensity selected";
CM_ SG_ 1443 LDW_Sensibility "This signal is used to give information about the LDW Sensibility selected";
CM_ SG_ 1443 PamChimeVolumeFront "This signal is used to give information about the PAM  Chime Volume selected";
CM_ SG_ 1443 PamChimeVolumeRear "This signal is used to give information about the PAM 8Ch Chime Volume selected";
CM_ SG_ 1443 Rear_Brk_Asst "Rear Braking Assist setting";
CM_ SG_ 1443 SVC_Guidelines "Surround View Camera Guidelines setting";
CM_ SG_ 2654486528 CBV_bit0_RepeatMessageRequestBit "Repeat Message Request Bit";
CM_ SG_ 2654486528 CBV_bit3_NMCoordinatorBit "NM Coordinator Sleep Bit";
CM_ SG_ 2654486528 CBV_bit4_ActiveWakeupBit "Active Wakeup Bit";
CM_ SG_ 2654486528 CBV_bit6_PartialNtwInfBit "Partial Network Information Bit (PNI)";
CM_ SG_ 2654486528 SourceNodeIdentifier "Source Node Identifier";
CM_ SG_ 2654486676 CBV_bit0_RepeatMessageRequestBit "Repeat Message Request Bit";
CM_ SG_ 2654486676 CBV_bit3_NMCoordinatorBit "NM Coordinator Sleep Bit";
CM_ SG_ 2654486676 CBV_bit4_ActiveWakeupBit "Active Wakeup Bit";
CM_ SG_ 2654486676 CBV_bit6_PartialNtwInfBit "Partial Network Information Bit (PNI)";
CM_ SG_ 2654486676 SourceNodeIdentifier "Source Node Identifier";
CM_ SG_ 2654486670 CBV_bit0_RepeatMessageRequestBit "Repeat Message Request Bit";
CM_ SG_ 2654486670 CBV_bit3_NMCoordinatorBit "NM Coordinator Sleep Bit";
CM_ SG_ 2654486670 CBV_bit4_ActiveWakeupBit "Active Wakeup Bit";
CM_ SG_ 2654486670 CBV_bit6_PartialNtwInfBit "Partial Network Information Bit (PNI)";
CM_ SG_ 2654486670 SourceNodeIdentifier "Source Node Identifier";
CM_ SG_ 2654486530 CBV_bit0_RepeatMessageRequestBit "Repeat Message Request Bit";
CM_ SG_ 2654486530 CBV_bit3_NMCoordinatorBit "NM Coordinator Sleep Bit";
CM_ SG_ 2654486530 CBV_bit4_ActiveWakeupBit "Active Wakeup Bit";
CM_ SG_ 2654486530 CBV_bit6_PartialNtwInfBit "Partial Network Information Bit (PNI)";
CM_ SG_ 2654486530 SourceNodeIdentifier "Source Node Identifier";
CM_ SG_ 2654486554 CBV_bit0_RepeatMessageRequestBit "Repeat Message Request Bit";
CM_ SG_ 2654486554 CBV_bit3_NMCoordinatorBit "NM Coordinator Sleep Bit";
CM_ SG_ 2654486554 CBV_bit4_ActiveWakeupBit "Active Wakeup Bit";
CM_ SG_ 2654486554 CBV_bit6_PartialNtwInfBit "Partial Network Information Bit (PNI)";
CM_ SG_ 2654486554 SourceNodeIdentifier "Source Node Identifier";
CM_ SG_ 2654486552 CBV_bit0_RepeatMessageRequestBit "Repeat Message Request Bit";
CM_ SG_ 2654486552 CBV_bit3_NMCoordinatorBit "NM Coordinator Sleep Bit";
CM_ SG_ 2654486552 CBV_bit4_ActiveWakeupBit "Active Wakeup Bit";
CM_ SG_ 2654486552 CBV_bit6_PartialNtwInfBit "Partial Network Information Bit (PNI)";
CM_ SG_ 2654486552 SourceNodeIdentifier "Source Node Identifier";
CM_ SG_ 2654486640 CBV_bit0_RepeatMessageRequestBit "Repeat Message Request Bit";
CM_ SG_ 2654486640 CBV_bit3_NMCoordinatorBit "NM Coordinator Sleep Bit";
CM_ SG_ 2654486640 CBV_bit4_ActiveWakeupBit "Active Wakeup Bit";
CM_ SG_ 2654486640 CBV_bit6_PartialNtwInfBit "Partial Network Information Bit (PNI)";
CM_ SG_ 2654486640 SourceNodeIdentifier "Source Node Identifier";
CM_ SG_ 2654486705 CBV_bit0_RepeatMessageRequestBit "Repeat Message Request Bit";
CM_ SG_ 2654486705 CBV_bit3_NMCoordinatorBit "NM Coordinator Sleep Bit";
CM_ SG_ 2654486705 CBV_bit4_ActiveWakeupBit "Active Wakeup Bit";
CM_ SG_ 2654486705 CBV_bit6_PartialNtwInfBit "Partial Network Information Bit (PNI)";
CM_ SG_ 2654486705 SourceNodeIdentifier "Source Node Identifier";
CM_ SG_ 611 AirBagFailSts "This signal is used to require the activation/deactivation of airbag warning light";
CM_ SG_ 611 CRC_ORC1 "CRC according to SAE J1850 standard at each frame transmission.";
CM_ SG_ 611 MessageCounter_ORC1 "This signal is a counter used for safety checks strategies. This counter is incremented of 1 (one) unit at each frame transmission.";
CM_ SG_ 611 SBR1RowDriverSeatConfigSts "Signal used to show if the first row driver seatbelt is under check";
CM_ SG_ 611 SBR1RowDriverSeatSts "First row driver seatbelt switch status";
CM_ SG_ 611 SBR1RowPsngrSeatConfigSts "Signal used to show if the first row passenger seatbelt is under check";
CM_ SG_ 611 SBR1RowPsngrSeatSts "First row passenger seat status";
BA_DEF_ SG_  "GenSigStartValue" INT 0 2147483647;
BA_DEF_ SG_  "GenSigInactiveValue" INT 0 2147483647;
BA_DEF_ SG_  "GenSigSendType" ENUM  "NotUsed","OnWrite","OnWriteWithRepetition","OnChange","OnChangeWithRepetition","IfActive","IfActiveWithRepetition","NoSigSendType";
BA_DEF_ SG_  "GenSigTimeoutTime_BCM" INT 0 65535;
BA_DEF_ SG_  "GenSigTimeoutTime_BSM2" INT 0 65535;
BA_DEF_ SG_  "GenSigTimeoutTime_CADM2" INT 0 65535;
BA_DEF_ SG_  "GenSigTimeoutTime_CVADAS" INT 0 65535;
BA_DEF_ SG_  "GenSigTimeoutTime_EPS" INT 0 65535;
BA_DEF_ SG_  "GenSigTimeoutTime_ORC" INT 0 65535;
BA_DEF_ SG_  "GenSigTimeoutTime_PAM" INT 0 65535;
BA_DEF_ SG_  "GenSigTimeoutTime_SGW" INT 0 65535;
BA_DEF_ SG_  "GenSigTimeoutTime_TRSKM" INT 0 65535;
BA_DEF_ BO_  "DiagRequest" ENUM  "No","Yes";
BA_DEF_ BO_  "Type" ENUM  "P","C","PE","COC","PE_Cntrl","E","E_Cntrl","OC","S","BAF","DC","EM","MM","ISO-TP","-";
BA_DEF_ BO_  "DiagResponse" ENUM  "No","Yes";
BA_DEF_ BO_  "NmMessage" ENUM  "No","Yes";
BA_DEF_ BO_  "GenMsgSendType" ENUM  "Cyclic","NotUsed","NotUsed","NotUsed","NotUsed","NotUsed","NotUsed","NotUsed","NoMsgSendType";
BA_DEF_ BO_  "GenMsgNrOfRepetition" INT 0 255;
BA_DEF_ BO_  "GenMsgILSupport" ENUM  "No","Yes";
BA_DEF_ BO_  "GenMsgStartDelayTime" INT 0 65535;
BA_DEF_ BO_  "GenMsgCycleTimeFast" INT 0 65535;
BA_DEF_ BO_  "GenMsgCycleTime" INT 0 65535;
BA_DEF_ BO_  "GenMsgDelayTime" INT 0 65535;
BA_DEF_ BO_  "NmAsrMessage" ENUM  "No","Yes";
BA_DEF_ BO_  "DiagState" ENUM  "No","Yes";
BA_DEF_ BO_  "DiagConnection" HEX 0 65535;
BA_DEF_ BO_  "VFrameFormat" ENUM  "StandardCAN","ExtendedCAN","reserved","reserved","reserved","reserved","reserved","reserved","reserved","reserved","reserved","reserved","reserved","reserved","StandardCAN_FD","ExtendedCAN_FD";
BA_DEF_ BO_  "CANFD_BRS" INT 0 1;
BA_DEF_DEF_  "GenSigStartValue" 0;
BA_DEF_DEF_  "GenSigInactiveValue" 0;
BA_DEF_DEF_  "GenSigSendType" "NoSigSendType";
BA_DEF_DEF_  "GenSigTimeoutTime_BCM" 2500;
BA_DEF_DEF_  "GenSigTimeoutTime_BSM2" 2500;
BA_DEF_DEF_  "GenSigTimeoutTime_CADM2" 2500;
BA_DEF_DEF_  "GenSigTimeoutTime_CVADAS" 2500;
BA_DEF_DEF_  "GenSigTimeoutTime_EPS" 2500;
BA_DEF_DEF_  "GenSigTimeoutTime_ORC" 2500;
BA_DEF_DEF_  "GenSigTimeoutTime_PAM" 2500;
BA_DEF_DEF_  "GenSigTimeoutTime_SGW" 2500;
BA_DEF_DEF_  "GenSigTimeoutTime_TRSKM" 2500;
BA_DEF_DEF_  "DiagRequest" "No";
BA_DEF_DEF_  "Type" "-";
BA_DEF_DEF_  "DiagResponse" "No";
BA_DEF_DEF_  "NmMessage" "No";
BA_DEF_DEF_  "GenMsgSendType" "NoMsgSendType";
BA_DEF_DEF_  "GenMsgNrOfRepetition" 0;
BA_DEF_DEF_  "GenMsgILSupport" "No";
BA_DEF_DEF_  "GenMsgStartDelayTime" 0;
BA_DEF_DEF_  "GenMsgCycleTimeFast" 0;
BA_DEF_DEF_  "GenMsgCycleTime" 0;
BA_DEF_DEF_  "GenMsgDelayTime" 0;
BA_DEF_DEF_  "NmAsrMessage" "No";
BA_DEF_DEF_  "DiagState" "No";
BA_DEF_DEF_  "DiagConnection" 0;
BA_DEF_DEF_  "VFrameFormat" "StandardCAN_FD";
BA_DEF_DEF_  "CANFD_BRS" 0;
BA_ "Type" BO_ 2564682031 8;
BA_ "DiagResponse" BO_ 2564682031 1;
BA_ "DiagConnection" BO_ 2564682031 61743;
BA_ "VFrameFormat" BO_ 2564682031 1;
BA_ "Type" BO_ 2564682032 8;
BA_ "DiagResponse" BO_ 2564682032 1;
BA_ "DiagConnection" BO_ 2564682032 61744;
BA_ "VFrameFormat" BO_ 2564682032 1;
BA_ "Type" BO_ 2564682275 8;
BA_ "DiagResponse" BO_ 2564682275 1;
BA_ "DiagConnection" BO_ 2564682275 61987;
BA_ "CANFD_BRS" BO_ 2564682275 1;
BA_ "VFrameFormat" BO_ 2564682275 15;
BA_ "Type" BO_ 2564682287 8;
BA_ "DiagResponse" BO_ 2564682287 1;
BA_ "DiagConnection" BO_ 2564682287 61999;
BA_ "CANFD_BRS" BO_ 2564682287 1;
BA_ "VFrameFormat" BO_ 2564682287 15;
BA_ "Type" BO_ 2564682288 8;
BA_ "DiagResponse" BO_ 2564682288 1;
BA_ "DiagConnection" BO_ 2564682288 62000;
BA_ "CANFD_BRS" BO_ 2564682288 1;
BA_ "VFrameFormat" BO_ 2564682288 15;
BA_ "Type" BO_ 2564682432 8;
BA_ "DiagResponse" BO_ 2564682432 1;
BA_ "DiagConnection" BO_ 2564682432 62144;
BA_ "CANFD_BRS" BO_ 2564682432 1;
BA_ "VFrameFormat" BO_ 2564682432 15;
BA_ "Type" BO_ 2564682400 8;
BA_ "GenMsgILSupport" BO_ 2564682400 1;
BA_ "DiagConnection" BO_ 2564682400 62112;
BA_ "CANFD_BRS" BO_ 2564682400 1;
BA_ "VFrameFormat" BO_ 2564682400 15;
BA_ "Type" BO_ 2564682476 8;
BA_ "DiagResponse" BO_ 2564682476 1;
BA_ "DiagConnection" BO_ 2564682476 62188;
BA_ "CANFD_BRS" BO_ 2564682476 1;
BA_ "VFrameFormat" BO_ 2564682476 15;
BA_ "Type" BO_ 2564682176 8;
BA_ "DiagResponse" BO_ 2564682176 1;
BA_ "DiagConnection" BO_ 2564682176 61888;
BA_ "VFrameFormat" BO_ 2564682176 1;
BA_ "Type" BO_ 2564682144 8;
BA_ "GenMsgILSupport" BO_ 2564682144 1;
BA_ "DiagConnection" BO_ 2564682144 61856;
BA_ "VFrameFormat" BO_ 2564682144 1;
BA_ "Type" BO_ 2564682220 8;
BA_ "DiagResponse" BO_ 2564682220 1;
BA_ "DiagConnection" BO_ 2564682220 61932;
BA_ "VFrameFormat" BO_ 2564682220 1;
BA_ "Type" BO_ 517 1;
BA_ "GenMsgSendType" BO_ 517 0;
BA_ "GenMsgILSupport" BO_ 517 1;
BA_ "GenMsgStartDelayTime" BO_ 517 10;
BA_ "GenMsgCycleTime" BO_ 517 20;
BA_ "CANFD_BRS" BO_ 517 1;
BA_ "Type" BO_ 1068 3;
BA_ "GenMsgSendType" BO_ 1068 0;
BA_ "GenMsgNrOfRepetition" BO_ 1068 2;
BA_ "GenMsgILSupport" BO_ 1068 1;
BA_ "GenMsgStartDelayTime" BO_ 1068 10;
BA_ "GenMsgCycleTimeFast" BO_ 1068 20;
BA_ "GenMsgCycleTime" BO_ 1068 100;
BA_ "GenMsgDelayTime" BO_ 1068 20;
BA_ "CANFD_BRS" BO_ 1068 1;
BA_ "Type" BO_ 576 3;
BA_ "GenMsgSendType" BO_ 576 0;
BA_ "GenMsgNrOfRepetition" BO_ 576 3;
BA_ "GenMsgILSupport" BO_ 576 1;
BA_ "GenMsgCycleTimeFast" BO_ 576 20;
BA_ "GenMsgCycleTime" BO_ 576 500;
BA_ "GenMsgDelayTime" BO_ 576 20;
BA_ "CANFD_BRS" BO_ 576 1;
BA_ "Type" BO_ 1054 1;
BA_ "GenMsgSendType" BO_ 1054 0;
BA_ "GenMsgILSupport" BO_ 1054 1;
BA_ "GenMsgStartDelayTime" BO_ 1054 15;
BA_ "GenMsgCycleTime" BO_ 1054 100;
BA_ "CANFD_BRS" BO_ 1054 1;
BA_ "Type" BO_ 262 1;
BA_ "GenMsgSendType" BO_ 262 0;
BA_ "GenMsgILSupport" BO_ 262 1;
BA_ "GenMsgCycleTime" BO_ 262 10;
BA_ "CANFD_BRS" BO_ 262 1;
BA_ "Type" BO_ 518 1;
BA_ "GenMsgSendType" BO_ 518 0;
BA_ "GenMsgILSupport" BO_ 518 1;
BA_ "GenMsgStartDelayTime" BO_ 518 10;
BA_ "GenMsgCycleTime" BO_ 518 20;
BA_ "CANFD_BRS" BO_ 518 1;
BA_ "Type" BO_ 751 1;
BA_ "GenMsgSendType" BO_ 751 0;
BA_ "GenMsgILSupport" BO_ 751 1;
BA_ "GenMsgStartDelayTime" BO_ 751 20;
BA_ "GenMsgCycleTime" BO_ 751 50;
BA_ "CANFD_BRS" BO_ 751 1;
BA_ "Type" BO_ 1448 3;
BA_ "GenMsgSendType" BO_ 1448 0;
BA_ "GenMsgNrOfRepetition" BO_ 1448 2;
BA_ "GenMsgILSupport" BO_ 1448 1;
BA_ "GenMsgStartDelayTime" BO_ 1448 205;
BA_ "GenMsgCycleTimeFast" BO_ 1448 20;
BA_ "GenMsgCycleTime" BO_ 1448 1000;
BA_ "GenMsgDelayTime" BO_ 1448 20;
BA_ "CANFD_BRS" BO_ 1448 1;
BA_ "Type" BO_ 1055 1;
BA_ "GenMsgSendType" BO_ 1055 0;
BA_ "GenMsgILSupport" BO_ 1055 1;
BA_ "GenMsgStartDelayTime" BO_ 1055 25;
BA_ "GenMsgCycleTime" BO_ 1055 100;
BA_ "CANFD_BRS" BO_ 1055 1;
BA_ "Type" BO_ 264 1;
BA_ "GenMsgSendType" BO_ 264 0;
BA_ "GenMsgILSupport" BO_ 264 1;
BA_ "GenMsgCycleTime" BO_ 264 10;
BA_ "CANFD_BRS" BO_ 264 1;
BA_ "Type" BO_ 1056 1;
BA_ "GenMsgSendType" BO_ 1056 0;
BA_ "GenMsgILSupport" BO_ 1056 1;
BA_ "GenMsgCycleTime" BO_ 1056 100;
BA_ "CANFD_BRS" BO_ 1056 1;
BA_ "Type" BO_ 1460 3;
BA_ "GenMsgSendType" BO_ 1460 0;
BA_ "GenMsgILSupport" BO_ 1460 1;
BA_ "GenMsgCycleTime" BO_ 1460 1000;
BA_ "GenMsgDelayTime" BO_ 1460 20;
BA_ "CANFD_BRS" BO_ 1460 1;
BA_ "Type" BO_ 1847 1;
BA_ "GenMsgSendType" BO_ 1847 0;
BA_ "GenMsgNrOfRepetition" BO_ 1847 2;
BA_ "GenMsgILSupport" BO_ 1847 1;
BA_ "GenMsgCycleTimeFast" BO_ 1847 20;
BA_ "GenMsgCycleTime" BO_ 1847 1000;
BA_ "GenMsgDelayTime" BO_ 1847 20;
BA_ "CANFD_BRS" BO_ 1847 1;
BA_ "Type" BO_ 525 1;
BA_ "GenMsgSendType" BO_ 525 0;
BA_ "GenMsgNrOfRepetition" BO_ 525 2;
BA_ "GenMsgILSupport" BO_ 525 1;
BA_ "GenMsgStartDelayTime" BO_ 525 15;
BA_ "GenMsgCycleTimeFast" BO_ 525 20;
BA_ "GenMsgCycleTime" BO_ 525 20;
BA_ "GenMsgDelayTime" BO_ 525 20;
BA_ "CANFD_BRS" BO_ 525 1;
BA_ "Type" BO_ 526 1;
BA_ "GenMsgSendType" BO_ 526 0;
BA_ "GenMsgNrOfRepetition" BO_ 526 2;
BA_ "GenMsgILSupport" BO_ 526 1;
BA_ "GenMsgCycleTimeFast" BO_ 526 20;
BA_ "GenMsgCycleTime" BO_ 526 20;
BA_ "CANFD_BRS" BO_ 526 1;
BA_ "Type" BO_ 266 1;
BA_ "GenMsgSendType" BO_ 266 0;
BA_ "GenMsgILSupport" BO_ 266 1;
BA_ "GenMsgStartDelayTime" BO_ 266 5;
BA_ "GenMsgCycleTime" BO_ 266 10;
BA_ "CANFD_BRS" BO_ 266 1;
BA_ "Type" BO_ 1049 1;
BA_ "GenMsgSendType" BO_ 1049 0;
BA_ "GenMsgILSupport" BO_ 1049 1;
BA_ "GenMsgCycleTime" BO_ 1049 100;
BA_ "CANFD_BRS" BO_ 1049 1;
BA_ "Type" BO_ 276 1;
BA_ "GenMsgSendType" BO_ 276 0;
BA_ "GenMsgILSupport" BO_ 276 1;
BA_ "GenMsgCycleTime" BO_ 276 10;
BA_ "CANFD_BRS" BO_ 276 1;
BA_ "Type" BO_ 269 1;
BA_ "GenMsgSendType" BO_ 269 0;
BA_ "GenMsgILSupport" BO_ 269 1;
BA_ "GenMsgStartDelayTime" BO_ 269 5;
BA_ "GenMsgCycleTime" BO_ 269 10;
BA_ "CANFD_BRS" BO_ 269 1;
BA_ "Type" BO_ 752 1;
BA_ "GenMsgSendType" BO_ 752 0;
BA_ "GenMsgILSupport" BO_ 752 1;
BA_ "GenMsgStartDelayTime" BO_ 752 25;
BA_ "GenMsgCycleTime" BO_ 752 50;
BA_ "CANFD_BRS" BO_ 752 1;
BA_ "Type" BO_ 754 1;
BA_ "GenMsgSendType" BO_ 754 0;
BA_ "GenMsgILSupport" BO_ 754 1;
BA_ "GenMsgStartDelayTime" BO_ 754 30;
BA_ "GenMsgCycleTime" BO_ 754 50;
BA_ "CANFD_BRS" BO_ 754 1;
BA_ "Type" BO_ 1955 1;
BA_ "GenMsgSendType" BO_ 1955 0;
BA_ "GenMsgILSupport" BO_ 1955 1;
BA_ "GenMsgStartDelayTime" BO_ 1955 210;
BA_ "GenMsgCycleTime" BO_ 1955 1000;
BA_ "CANFD_BRS" BO_ 1955 1;
BA_ "Type" BO_ 1957 1;
BA_ "GenMsgSendType" BO_ 1957 0;
BA_ "GenMsgILSupport" BO_ 1957 1;
BA_ "GenMsgStartDelayTime" BO_ 1957 215;
BA_ "GenMsgCycleTime" BO_ 1957 1000;
BA_ "CANFD_BRS" BO_ 1957 1;
BA_ "Type" BO_ 1626 10;
BA_ "GenMsgSendType" BO_ 1626 0;
BA_ "GenMsgILSupport" BO_ 1626 1;
BA_ "GenMsgCycleTimeFast" BO_ 1626 10;
BA_ "GenMsgCycleTime" BO_ 1626 500;
BA_ "CANFD_BRS" BO_ 1626 1;
BA_ "Type" BO_ 1829 1;
BA_ "GenMsgSendType" BO_ 1829 0;
BA_ "GenMsgILSupport" BO_ 1829 1;
BA_ "GenMsgStartDelayTime" BO_ 1829 220;
BA_ "GenMsgCycleTime" BO_ 1829 1000;
BA_ "CANFD_BRS" BO_ 1829 1;
BA_ "Type" BO_ 600 3;
BA_ "GenMsgSendType" BO_ 600 0;
BA_ "GenMsgNrOfRepetition" BO_ 600 2;
BA_ "GenMsgILSupport" BO_ 600 1;
BA_ "GenMsgStartDelayTime" BO_ 600 35;
BA_ "GenMsgCycleTimeFast" BO_ 600 20;
BA_ "GenMsgCycleTime" BO_ 600 100;
BA_ "GenMsgDelayTime" BO_ 600 20;
BA_ "CANFD_BRS" BO_ 600 1;
BA_ "Type" BO_ 1432 3;
BA_ "GenMsgSendType" BO_ 1432 0;
BA_ "GenMsgNrOfRepetition" BO_ 1432 2;
BA_ "GenMsgILSupport" BO_ 1432 1;
BA_ "GenMsgStartDelayTime" BO_ 1432 225;
BA_ "GenMsgCycleTimeFast" BO_ 1432 20;
BA_ "GenMsgCycleTime" BO_ 1432 1000;
BA_ "GenMsgDelayTime" BO_ 1432 20;
BA_ "CANFD_BRS" BO_ 1432 1;
BA_ "Type" BO_ 1443 3;
BA_ "GenMsgSendType" BO_ 1443 0;
BA_ "GenMsgNrOfRepetition" BO_ 1443 2;
BA_ "GenMsgILSupport" BO_ 1443 1;
BA_ "GenMsgStartDelayTime" BO_ 1443 230;
BA_ "GenMsgCycleTimeFast" BO_ 1443 20;
BA_ "GenMsgCycleTime" BO_ 1443 1000;
BA_ "GenMsgDelayTime" BO_ 1443 20;
BA_ "CANFD_BRS" BO_ 1443 1;
BA_ "Type" BO_ 2654486528 8;
BA_ "NmMessage" BO_ 2654486528 1;
BA_ "NmAsrMessage" BO_ 2654486528 1;
BA_ "CANFD_BRS" BO_ 2654486528 1;
BA_ "VFrameFormat" BO_ 2654486528 15;
BA_ "Type" BO_ 2654486676 8;
BA_ "NmMessage" BO_ 2654486676 1;
BA_ "NmAsrMessage" BO_ 2654486676 1;
BA_ "CANFD_BRS" BO_ 2654486676 1;
BA_ "VFrameFormat" BO_ 2654486676 15;
BA_ "Type" BO_ 2654486670 8;
BA_ "NmMessage" BO_ 2654486670 1;
BA_ "NmAsrMessage" BO_ 2654486670 1;
BA_ "CANFD_BRS" BO_ 2654486670 1;
BA_ "VFrameFormat" BO_ 2654486670 15;
BA_ "Type" BO_ 2654486530 8;
BA_ "NmMessage" BO_ 2654486530 1;
BA_ "NmAsrMessage" BO_ 2654486530 1;
BA_ "CANFD_BRS" BO_ 2654486530 1;
BA_ "VFrameFormat" BO_ 2654486530 15;
BA_ "Type" BO_ 2654486554 8;
BA_ "NmMessage" BO_ 2654486554 1;
BA_ "NmAsrMessage" BO_ 2654486554 1;
BA_ "CANFD_BRS" BO_ 2654486554 1;
BA_ "VFrameFormat" BO_ 2654486554 15;
BA_ "Type" BO_ 2654486552 8;
BA_ "NmMessage" BO_ 2654486552 1;
BA_ "NmAsrMessage" BO_ 2654486552 1;
BA_ "CANFD_BRS" BO_ 2654486552 1;
BA_ "VFrameFormat" BO_ 2654486552 15;
BA_ "Type" BO_ 2654486640 8;
BA_ "NmMessage" BO_ 2654486640 1;
BA_ "NmAsrMessage" BO_ 2654486640 1;
BA_ "CANFD_BRS" BO_ 2654486640 1;
BA_ "VFrameFormat" BO_ 2654486640 15;
BA_ "Type" BO_ 2654486705 8;
BA_ "NmMessage" BO_ 2654486705 1;
BA_ "NmAsrMessage" BO_ 2654486705 1;
BA_ "CANFD_BRS" BO_ 2654486705 1;
BA_ "VFrameFormat" BO_ 2654486705 15;
BA_ "Type" BO_ 611 3;
BA_ "GenMsgSendType" BO_ 611 0;
BA_ "GenMsgILSupport" BO_ 611 1;
BA_ "GenMsgCycleTime" BO_ 611 100;
BA_ "GenMsgDelayTime" BO_ 611 20;
BA_ "CANFD_BRS" BO_ 611 1;
BA_ "GenSigTimeoutTime_BCM" SG_ 2564682031 N_PDU 0;
BA_ "GenSigTimeoutTime_BSM2" SG_ 2564682031 N_PDU 0;
BA_ "GenSigTimeoutTime_CADM2" SG_ 2564682031 N_PDU 0;
BA_ "GenSigTimeoutTime_CVADAS" SG_ 2564682031 N_PDU 0;
BA_ "GenSigTimeoutTime_EPS" SG_ 2564682031 N_PDU 0;
BA_ "GenSigTimeoutTime_ORC" SG_ 2564682031 N_PDU 0;
BA_ "GenSigTimeoutTime_PAM" SG_ 2564682031 N_PDU 0;
BA_ "GenSigTimeoutTime_SGW" SG_ 2564682031 N_PDU 0;
BA_ "GenSigTimeoutTime_TRSKM" SG_ 2564682031 N_PDU 0;
BA_ "GenSigTimeoutTime_BCM" SG_ 2564682032 N_PDU 0;
BA_ "GenSigTimeoutTime_BSM2" SG_ 2564682032 N_PDU 0;
BA_ "GenSigTimeoutTime_CADM2" SG_ 2564682032 N_PDU 0;
BA_ "GenSigTimeoutTime_CVADAS" SG_ 2564682032 N_PDU 0;
BA_ "GenSigTimeoutTime_EPS" SG_ 2564682032 N_PDU 0;
BA_ "GenSigTimeoutTime_ORC" SG_ 2564682032 N_PDU 0;
BA_ "GenSigTimeoutTime_PAM" SG_ 2564682032 N_PDU 0;
BA_ "GenSigTimeoutTime_SGW" SG_ 2564682032 N_PDU 0;
BA_ "GenSigTimeoutTime_TRSKM" SG_ 2564682032 N_PDU 0;
BA_ "GenSigTimeoutTime_BCM" SG_ 2564682275 N_PDU 0;
BA_ "GenSigTimeoutTime_BSM2" SG_ 2564682275 N_PDU 0;
BA_ "GenSigTimeoutTime_CADM2" SG_ 2564682275 N_PDU 0;
BA_ "GenSigTimeoutTime_CVADAS" SG_ 2564682275 N_PDU 0;
BA_ "GenSigTimeoutTime_EPS" SG_ 2564682275 N_PDU 0;
BA_ "GenSigTimeoutTime_ORC" SG_ 2564682275 N_PDU 0;
BA_ "GenSigTimeoutTime_PAM" SG_ 2564682275 N_PDU 0;
BA_ "GenSigTimeoutTime_SGW" SG_ 2564682275 N_PDU 0;
BA_ "GenSigTimeoutTime_TRSKM" SG_ 2564682275 N_PDU 0;
BA_ "GenSigTimeoutTime_BCM" SG_ 2564682287 N_PDU 0;
BA_ "GenSigTimeoutTime_BSM2" SG_ 2564682287 N_PDU 0;
BA_ "GenSigTimeoutTime_CADM2" SG_ 2564682287 N_PDU 0;
BA_ "GenSigTimeoutTime_CVADAS" SG_ 2564682287 N_PDU 0;
BA_ "GenSigTimeoutTime_EPS" SG_ 2564682287 N_PDU 0;
BA_ "GenSigTimeoutTime_ORC" SG_ 2564682287 N_PDU 0;
BA_ "GenSigTimeoutTime_PAM" SG_ 2564682287 N_PDU 0;
BA_ "GenSigTimeoutTime_SGW" SG_ 2564682287 N_PDU 0;
BA_ "GenSigTimeoutTime_TRSKM" SG_ 2564682287 N_PDU 0;
BA_ "GenSigTimeoutTime_BCM" SG_ 2564682288 N_PDU 0;
BA_ "GenSigTimeoutTime_BSM2" SG_ 2564682288 N_PDU 0;
BA_ "GenSigTimeoutTime_CADM2" SG_ 2564682288 N_PDU 0;
BA_ "GenSigTimeoutTime_CVADAS" SG_ 2564682288 N_PDU 0;
BA_ "GenSigTimeoutTime_EPS" SG_ 2564682288 N_PDU 0;
BA_ "GenSigTimeoutTime_ORC" SG_ 2564682288 N_PDU 0;
BA_ "GenSigTimeoutTime_PAM" SG_ 2564682288 N_PDU 0;
BA_ "GenSigTimeoutTime_SGW" SG_ 2564682288 N_PDU 0;
BA_ "GenSigTimeoutTime_TRSKM" SG_ 2564682288 N_PDU 0;
BA_ "GenSigTimeoutTime_BCM" SG_ 2564682432 N_PDU 0;
BA_ "GenSigTimeoutTime_BSM2" SG_ 2564682432 N_PDU 0;
BA_ "GenSigTimeoutTime_CADM2" SG_ 2564682432 N_PDU 0;
BA_ "GenSigTimeoutTime_CVADAS" SG_ 2564682432 N_PDU 0;
BA_ "GenSigTimeoutTime_EPS" SG_ 2564682432 N_PDU 0;
BA_ "GenSigTimeoutTime_ORC" SG_ 2564682432 N_PDU 0;
BA_ "GenSigTimeoutTime_PAM" SG_ 2564682432 N_PDU 0;
BA_ "GenSigTimeoutTime_SGW" SG_ 2564682432 N_PDU 0;
BA_ "GenSigTimeoutTime_TRSKM" SG_ 2564682432 N_PDU 0;
BA_ "GenSigTimeoutTime_BCM" SG_ 2564682400 N_PDU 0;
BA_ "GenSigTimeoutTime_BSM2" SG_ 2564682400 N_PDU 0;
BA_ "GenSigTimeoutTime_CADM2" SG_ 2564682400 N_PDU 0;
BA_ "GenSigTimeoutTime_CVADAS" SG_ 2564682400 N_PDU 0;
BA_ "GenSigTimeoutTime_EPS" SG_ 2564682400 N_PDU 0;
BA_ "GenSigTimeoutTime_ORC" SG_ 2564682400 N_PDU 0;
BA_ "GenSigTimeoutTime_PAM" SG_ 2564682400 N_PDU 0;
BA_ "GenSigTimeoutTime_SGW" SG_ 2564682400 N_PDU 0;
BA_ "GenSigTimeoutTime_TRSKM" SG_ 2564682400 N_PDU 0;
BA_ "GenSigTimeoutTime_BCM" SG_ 2564682476 N_PDU 0;
BA_ "GenSigTimeoutTime_BSM2" SG_ 2564682476 N_PDU 0;
BA_ "GenSigTimeoutTime_CADM2" SG_ 2564682476 N_PDU 0;
BA_ "GenSigTimeoutTime_CVADAS" SG_ 2564682476 N_PDU 0;
BA_ "GenSigTimeoutTime_EPS" SG_ 2564682476 N_PDU 0;
BA_ "GenSigTimeoutTime_ORC" SG_ 2564682476 N_PDU 0;
BA_ "GenSigTimeoutTime_PAM" SG_ 2564682476 N_PDU 0;
BA_ "GenSigTimeoutTime_SGW" SG_ 2564682476 N_PDU 0;
BA_ "GenSigTimeoutTime_TRSKM" SG_ 2564682476 N_PDU 0;
BA_ "GenSigTimeoutTime_BCM" SG_ 2564682176 N_PDU 0;
BA_ "GenSigTimeoutTime_BSM2" SG_ 2564682176 N_PDU 0;
BA_ "GenSigTimeoutTime_CADM2" SG_ 2564682176 N_PDU 0;
BA_ "GenSigTimeoutTime_CVADAS" SG_ 2564682176 N_PDU 0;
BA_ "GenSigTimeoutTime_EPS" SG_ 2564682176 N_PDU 0;
BA_ "GenSigTimeoutTime_ORC" SG_ 2564682176 N_PDU 0;
BA_ "GenSigTimeoutTime_PAM" SG_ 2564682176 N_PDU 0;
BA_ "GenSigTimeoutTime_SGW" SG_ 2564682176 N_PDU 0;
BA_ "GenSigTimeoutTime_TRSKM" SG_ 2564682176 N_PDU 0;
BA_ "GenSigTimeoutTime_BCM" SG_ 2564682144 N_PDU 0;
BA_ "GenSigTimeoutTime_BSM2" SG_ 2564682144 N_PDU 0;
BA_ "GenSigTimeoutTime_CADM2" SG_ 2564682144 N_PDU 0;
BA_ "GenSigTimeoutTime_CVADAS" SG_ 2564682144 N_PDU 0;
BA_ "GenSigTimeoutTime_EPS" SG_ 2564682144 N_PDU 0;
BA_ "GenSigTimeoutTime_ORC" SG_ 2564682144 N_PDU 0;
BA_ "GenSigTimeoutTime_PAM" SG_ 2564682144 N_PDU 0;
BA_ "GenSigTimeoutTime_SGW" SG_ 2564682144 N_PDU 0;
BA_ "GenSigTimeoutTime_TRSKM" SG_ 2564682144 N_PDU 0;
BA_ "GenSigTimeoutTime_BCM" SG_ 2564682220 N_PDU 0;
BA_ "GenSigTimeoutTime_BSM2" SG_ 2564682220 N_PDU 0;
BA_ "GenSigTimeoutTime_CADM2" SG_ 2564682220 N_PDU 0;
BA_ "GenSigTimeoutTime_CVADAS" SG_ 2564682220 N_PDU 0;
BA_ "GenSigTimeoutTime_EPS" SG_ 2564682220 N_PDU 0;
BA_ "GenSigTimeoutTime_ORC" SG_ 2564682220 N_PDU 0;
BA_ "GenSigTimeoutTime_PAM" SG_ 2564682220 N_PDU 0;
BA_ "GenSigTimeoutTime_SGW" SG_ 2564682220 N_PDU 0;
BA_ "GenSigTimeoutTime_TRSKM" SG_ 2564682220 N_PDU 0;
BA_ "GenSigStartValue" SG_ 517 AWDSysStat 7;
BA_ "GenSigTimeoutTime_BCM" SG_ 517 AWDSysStat 0;
BA_ "GenSigTimeoutTime_CADM2" SG_ 517 AWDSysStat 0;
BA_ "GenSigTimeoutTime_CVADAS" SG_ 517 AWDSysStat 0;
BA_ "GenSigTimeoutTime_EPS" SG_ 517 AWDSysStat 0;
BA_ "GenSigTimeoutTime_PAM" SG_ 517 AWDSysStat 0;
BA_ "GenSigTimeoutTime_SGW" SG_ 517 AWDSysStat 0;
BA_ "GenSigTimeoutTime_TRSKM" SG_ 517 AWDSysStat 0;
BA_ "GenSigTimeoutTime_BCM" SG_ 517 CCMFailSts 0;
BA_ "GenSigTimeoutTime_CADM2" SG_ 517 CCMFailSts 0;
BA_ "GenSigTimeoutTime_CVADAS" SG_ 517 CCMFailSts 0;
BA_ "GenSigTimeoutTime_EPS" SG_ 517 CCMFailSts 0;
BA_ "GenSigTimeoutTime_PAM" SG_ 517 CCMFailSts 0;
BA_ "GenSigTimeoutTime_SGW" SG_ 517 CCMFailSts 0;
BA_ "GenSigTimeoutTime_TRSKM" SG_ 517 CCMFailSts 0;
BA_ "GenSigTimeoutTime_BCM" SG_ 517 CRC_DRIVETRAIN1 0;
BA_ "GenSigTimeoutTime_CADM2" SG_ 517 CRC_DRIVETRAIN1 0;
BA_ "GenSigTimeoutTime_CVADAS" SG_ 517 CRC_DRIVETRAIN1 0;
BA_ "GenSigTimeoutTime_EPS" SG_ 517 CRC_DRIVETRAIN1 0;
BA_ "GenSigTimeoutTime_ORC" SG_ 517 CRC_DRIVETRAIN1 0;
BA_ "GenSigTimeoutTime_PAM" SG_ 517 CRC_DRIVETRAIN1 0;
BA_ "GenSigTimeoutTime_SGW" SG_ 517 CRC_DRIVETRAIN1 0;
BA_ "GenSigTimeoutTime_TRSKM" SG_ 517 CRC_DRIVETRAIN1 0;
BA_ "GenSigStartValue" SG_ 517 Ft_RrCouplingTrq_Actual 255;
BA_ "GenSigTimeoutTime_BCM" SG_ 517 Ft_RrCouplingTrq_Actual 0;
BA_ "GenSigTimeoutTime_CADM2" SG_ 517 Ft_RrCouplingTrq_Actual 0;
BA_ "GenSigTimeoutTime_CVADAS" SG_ 517 Ft_RrCouplingTrq_Actual 0;
BA_ "GenSigTimeoutTime_EPS" SG_ 517 Ft_RrCouplingTrq_Actual 0;
BA_ "GenSigTimeoutTime_ORC" SG_ 517 Ft_RrCouplingTrq_Actual 0;
BA_ "GenSigTimeoutTime_PAM" SG_ 517 Ft_RrCouplingTrq_Actual 0;
BA_ "GenSigTimeoutTime_SGW" SG_ 517 Ft_RrCouplingTrq_Actual 0;
BA_ "GenSigTimeoutTime_TRSKM" SG_ 517 Ft_RrCouplingTrq_Actual 0;
BA_ "GenSigTimeoutTime_BCM" SG_ 517 MessageCounter_DRIVETRAIN1 0;
BA_ "GenSigTimeoutTime_CADM2" SG_ 517 MessageCounter_DRIVETRAIN1 0;
BA_ "GenSigTimeoutTime_CVADAS" SG_ 517 MessageCounter_DRIVETRAIN1 0;
BA_ "GenSigTimeoutTime_EPS" SG_ 517 MessageCounter_DRIVETRAIN1 0;
BA_ "GenSigTimeoutTime_ORC" SG_ 517 MessageCounter_DRIVETRAIN1 0;
BA_ "GenSigTimeoutTime_PAM" SG_ 517 MessageCounter_DRIVETRAIN1 0;
BA_ "GenSigTimeoutTime_SGW" SG_ 517 MessageCounter_DRIVETRAIN1 0;
BA_ "GenSigTimeoutTime_TRSKM" SG_ 517 MessageCounter_DRIVETRAIN1 0;
BA_ "GenSigTimeoutTime_BCM" SG_ 1068 CRC__DRIVETRAIN3 0;
BA_ "GenSigTimeoutTime_CADM2" SG_ 1068 CRC__DRIVETRAIN3 0;
BA_ "GenSigTimeoutTime_ORC" SG_ 1068 CRC__DRIVETRAIN3 0;
BA_ "GenSigTimeoutTime_PAM" SG_ 1068 CRC__DRIVETRAIN3 0;
BA_ "GenSigTimeoutTime_SGW" SG_ 1068 CRC__DRIVETRAIN3 0;
BA_ "GenSigTimeoutTime_TRSKM" SG_ 1068 CRC__DRIVETRAIN3 0;
BA_ "GenSigTimeoutTime_BCM" SG_ 1068 MessageCounter_DRIVETRAIN3 0;
BA_ "GenSigTimeoutTime_CADM2" SG_ 1068 MessageCounter_DRIVETRAIN3 0;
BA_ "GenSigTimeoutTime_ORC" SG_ 1068 MessageCounter_DRIVETRAIN3 0;
BA_ "GenSigTimeoutTime_PAM" SG_ 1068 MessageCounter_DRIVETRAIN3 0;
BA_ "GenSigTimeoutTime_SGW" SG_ 1068 MessageCounter_DRIVETRAIN3 0;
BA_ "GenSigTimeoutTime_TRSKM" SG_ 1068 MessageCounter_DRIVETRAIN3 0;
BA_ "GenSigSendType" SG_ 1068 TCASERANGESTATUS 3;
BA_ "GenSigTimeoutTime_BCM" SG_ 1068 TCASERANGESTATUS 0;
BA_ "GenSigTimeoutTime_BSM2" SG_ 1068 TCASERANGESTATUS 0;
BA_ "GenSigTimeoutTime_CADM2" SG_ 1068 TCASERANGESTATUS 0;
BA_ "GenSigTimeoutTime_ORC" SG_ 1068 TCASERANGESTATUS 0;
BA_ "GenSigTimeoutTime_SGW" SG_ 1068 TCASERANGESTATUS 0;
BA_ "GenSigTimeoutTime_TRSKM" SG_ 1068 TCASERANGESTATUS 0;
BA_ "GenSigTimeoutTime_BCM" SG_ 576 DriverDoor2AjarRawValSts 0;
BA_ "GenSigTimeoutTime_BSM2" SG_ 576 DriverDoor2AjarRawValSts 0;
BA_ "GenSigTimeoutTime_CADM2" SG_ 576 DriverDoor2AjarRawValSts 0;
BA_ "GenSigTimeoutTime_CVADAS" SG_ 576 DriverDoor2AjarRawValSts 0;
BA_ "GenSigTimeoutTime_EPS" SG_ 576 DriverDoor2AjarRawValSts 0;
BA_ "GenSigTimeoutTime_PAM" SG_ 576 DriverDoor2AjarRawValSts 0;
BA_ "GenSigTimeoutTime_SGW" SG_ 576 DriverDoor2AjarRawValSts 0;
BA_ "GenSigTimeoutTime_TRSKM" SG_ 576 DriverDoor2AjarRawValSts 0;
BA_ "GenSigSendType" SG_ 576 DriverDoor3AjarRawValSts 3;
BA_ "GenSigTimeoutTime_BCM" SG_ 576 DriverDoor3AjarRawValSts 0;
BA_ "GenSigTimeoutTime_BSM2" SG_ 576 DriverDoor3AjarRawValSts 0;
BA_ "GenSigTimeoutTime_CADM2" SG_ 576 DriverDoor3AjarRawValSts 0;
BA_ "GenSigTimeoutTime_CVADAS" SG_ 576 DriverDoor3AjarRawValSts 0;
BA_ "GenSigTimeoutTime_EPS" SG_ 576 DriverDoor3AjarRawValSts 0;
BA_ "GenSigTimeoutTime_PAM" SG_ 576 DriverDoor3AjarRawValSts 0;
BA_ "GenSigTimeoutTime_SGW" SG_ 576 DriverDoor3AjarRawValSts 0;
BA_ "GenSigTimeoutTime_TRSKM" SG_ 576 DriverDoor3AjarRawValSts 0;
BA_ "GenSigSendType" SG_ 576 DriverDoor4AjarRawValSts 3;
BA_ "GenSigTimeoutTime_BCM" SG_ 576 DriverDoor4AjarRawValSts 0;
BA_ "GenSigTimeoutTime_BSM2" SG_ 576 DriverDoor4AjarRawValSts 0;
BA_ "GenSigTimeoutTime_CADM2" SG_ 576 DriverDoor4AjarRawValSts 0;
BA_ "GenSigTimeoutTime_CVADAS" SG_ 576 DriverDoor4AjarRawValSts 0;
BA_ "GenSigTimeoutTime_EPS" SG_ 576 DriverDoor4AjarRawValSts 0;
BA_ "GenSigTimeoutTime_PAM" SG_ 576 DriverDoor4AjarRawValSts 0;
BA_ "GenSigTimeoutTime_SGW" SG_ 576 DriverDoor4AjarRawValSts 0;
BA_ "GenSigTimeoutTime_TRSKM" SG_ 576 DriverDoor4AjarRawValSts 0;
BA_ "GenSigTimeoutTime_BCM" SG_ 576 DriverDoorAjarRawValSts 0;
BA_ "GenSigTimeoutTime_BSM2" SG_ 576 DriverDoorAjarRawValSts 0;
BA_ "GenSigTimeoutTime_CADM2" SG_ 576 DriverDoorAjarRawValSts 0;
BA_ "GenSigTimeoutTime_CVADAS" SG_ 576 DriverDoorAjarRawValSts 0;
BA_ "GenSigTimeoutTime_EPS" SG_ 576 DriverDoorAjarRawValSts 0;
BA_ "GenSigTimeoutTime_PAM" SG_ 576 DriverDoorAjarRawValSts 0;
BA_ "GenSigTimeoutTime_SGW" SG_ 576 DriverDoorAjarRawValSts 0;
BA_ "GenSigTimeoutTime_TRSKM" SG_ 576 DriverDoorAjarRawValSts 0;
BA_ "GenSigTimeoutTime_BCM" SG_ 1054 BrkSw1Stat 0;
BA_ "GenSigTimeoutTime_BSM2" SG_ 1054 BrkSw1Stat 0;
BA_ "GenSigTimeoutTime_CADM2" SG_ 1054 BrkSw1Stat 0;
BA_ "GenSigTimeoutTime_CVADAS" SG_ 1054 BrkSw1Stat 0;
BA_ "GenSigTimeoutTime_EPS" SG_ 1054 BrkSw1Stat 0;
BA_ "GenSigTimeoutTime_PAM" SG_ 1054 BrkSw1Stat 0;
BA_ "GenSigTimeoutTime_SGW" SG_ 1054 BrkSw1Stat 0;
BA_ "GenSigTimeoutTime_TRSKM" SG_ 1054 BrkSw1Stat 0;
BA_ "GenSigTimeoutTime_BCM" SG_ 1054 BrkSw2Stat 0;
BA_ "GenSigTimeoutTime_BSM2" SG_ 1054 BrkSw2Stat 0;
BA_ "GenSigTimeoutTime_CADM2" SG_ 1054 BrkSw2Stat 0;
BA_ "GenSigTimeoutTime_CVADAS" SG_ 1054 BrkSw2Stat 0;
BA_ "GenSigTimeoutTime_EPS" SG_ 1054 BrkSw2Stat 0;
BA_ "GenSigTimeoutTime_PAM" SG_ 1054 BrkSw2Stat 0;
BA_ "GenSigTimeoutTime_SGW" SG_ 1054 BrkSw2Stat 0;
BA_ "GenSigTimeoutTime_TRSKM" SG_ 1054 BrkSw2Stat 0;
BA_ "GenSigTimeoutTime_BCM" SG_ 1054 ESP_TrqRqEnabl 0;
BA_ "GenSigTimeoutTime_BSM2" SG_ 1054 ESP_TrqRqEnabl 0;
BA_ "GenSigTimeoutTime_CADM2" SG_ 1054 ESP_TrqRqEnabl 0;
BA_ "GenSigTimeoutTime_CVADAS" SG_ 1054 ESP_TrqRqEnabl 0;
BA_ "GenSigTimeoutTime_EPS" SG_ 1054 ESP_TrqRqEnabl 0;
BA_ "GenSigTimeoutTime_PAM" SG_ 1054 ESP_TrqRqEnabl 0;
BA_ "GenSigTimeoutTime_SGW" SG_ 1054 ESP_TrqRqEnabl 0;
BA_ "GenSigTimeoutTime_TRSKM" SG_ 1054 ESP_TrqRqEnabl 0;
BA_ "GenSigTimeoutTime_BCM" SG_ 1054 Lv1CrsCtrlOff 0;
BA_ "GenSigTimeoutTime_BSM2" SG_ 1054 Lv1CrsCtrlOff 0;
BA_ "GenSigTimeoutTime_CADM2" SG_ 1054 Lv1CrsCtrlOff 0;
BA_ "GenSigTimeoutTime_CVADAS" SG_ 1054 Lv1CrsCtrlOff 0;
BA_ "GenSigTimeoutTime_EPS" SG_ 1054 Lv1CrsCtrlOff 0;
BA_ "GenSigTimeoutTime_PAM" SG_ 1054 Lv1CrsCtrlOff 0;
BA_ "GenSigTimeoutTime_SGW" SG_ 1054 Lv1CrsCtrlOff 0;
BA_ "GenSigTimeoutTime_TRSKM" SG_ 1054 Lv1CrsCtrlOff 0;
BA_ "GenSigStartValue" SG_ 1054 RawPVS1 255;
BA_ "GenSigTimeoutTime_BCM" SG_ 1054 RawPVS1 0;
BA_ "GenSigTimeoutTime_BSM2" SG_ 1054 RawPVS1 0;
BA_ "GenSigTimeoutTime_CADM2" SG_ 1054 RawPVS1 0;
BA_ "GenSigTimeoutTime_CVADAS" SG_ 1054 RawPVS1 0;
BA_ "GenSigTimeoutTime_EPS" SG_ 1054 RawPVS1 0;
BA_ "GenSigTimeoutTime_PAM" SG_ 1054 RawPVS1 0;
BA_ "GenSigTimeoutTime_SGW" SG_ 1054 RawPVS1 0;
BA_ "GenSigTimeoutTime_TRSKM" SG_ 1054 RawPVS1 0;
BA_ "GenSigStartValue" SG_ 1054 RawPVS2 255;
BA_ "GenSigTimeoutTime_BCM" SG_ 1054 RawPVS2 0;
BA_ "GenSigTimeoutTime_BSM2" SG_ 1054 RawPVS2 0;
BA_ "GenSigTimeoutTime_CADM2" SG_ 1054 RawPVS2 0;
BA_ "GenSigTimeoutTime_CVADAS" SG_ 1054 RawPVS2 0;
BA_ "GenSigTimeoutTime_EPS" SG_ 1054 RawPVS2 0;
BA_ "GenSigTimeoutTime_PAM" SG_ 1054 RawPVS2 0;
BA_ "GenSigTimeoutTime_SGW" SG_ 1054 RawPVS2 0;
BA_ "GenSigTimeoutTime_TRSKM" SG_ 1054 RawPVS2 0;
BA_ "GenSigStartValue" SG_ 1054 RawTPS1 255;
BA_ "GenSigTimeoutTime_BCM" SG_ 1054 RawTPS1 0;
BA_ "GenSigTimeoutTime_BSM2" SG_ 1054 RawTPS1 0;
BA_ "GenSigTimeoutTime_CADM2" SG_ 1054 RawTPS1 0;
BA_ "GenSigTimeoutTime_CVADAS" SG_ 1054 RawTPS1 0;
BA_ "GenSigTimeoutTime_EPS" SG_ 1054 RawTPS1 0;
BA_ "GenSigTimeoutTime_PAM" SG_ 1054 RawTPS1 0;
BA_ "GenSigTimeoutTime_SGW" SG_ 1054 RawTPS1 0;
BA_ "GenSigTimeoutTime_TRSKM" SG_ 1054 RawTPS1 0;
BA_ "GenSigStartValue" SG_ 1054 RawTPS2 255;
BA_ "GenSigTimeoutTime_BCM" SG_ 1054 RawTPS2 0;
BA_ "GenSigTimeoutTime_BSM2" SG_ 1054 RawTPS2 0;
BA_ "GenSigTimeoutTime_CADM2" SG_ 1054 RawTPS2 0;
BA_ "GenSigTimeoutTime_CVADAS" SG_ 1054 RawTPS2 0;
BA_ "GenSigTimeoutTime_EPS" SG_ 1054 RawTPS2 0;
BA_ "GenSigTimeoutTime_PAM" SG_ 1054 RawTPS2 0;
BA_ "GenSigTimeoutTime_SGW" SG_ 1054 RawTPS2 0;
BA_ "GenSigTimeoutTime_TRSKM" SG_ 1054 RawTPS2 0;
BA_ "GenSigTimeoutTime_BCM" SG_ 1054 ThrottlePosition 0;
BA_ "GenSigTimeoutTime_BSM2" SG_ 1054 ThrottlePosition 0;
BA_ "GenSigTimeoutTime_CADM2" SG_ 1054 ThrottlePosition 0;
BA_ "GenSigTimeoutTime_CVADAS" SG_ 1054 ThrottlePosition 0;
BA_ "GenSigTimeoutTime_EPS" SG_ 1054 ThrottlePosition 0;
BA_ "GenSigTimeoutTime_PAM" SG_ 1054 ThrottlePosition 0;
BA_ "GenSigTimeoutTime_SGW" SG_ 1054 ThrottlePosition 0;
BA_ "GenSigTimeoutTime_TRSKM" SG_ 1054 ThrottlePosition 0;
BA_ "GenSigTimeoutTime_BCM" SG_ 262 CRC_ENGINE2 0;
BA_ "GenSigTimeoutTime_BSM2" SG_ 262 CRC_ENGINE2 0;
BA_ "GenSigTimeoutTime_ORC" SG_ 262 CRC_ENGINE2 0;
BA_ "GenSigTimeoutTime_SGW" SG_ 262 CRC_ENGINE2 0;
BA_ "GenSigTimeoutTime_TRSKM" SG_ 262 CRC_ENGINE2 0;
BA_ "GenSigTimeoutTime_BCM" SG_ 262 EngineSpeed_W 0;
BA_ "GenSigTimeoutTime_BSM2" SG_ 262 EngineSpeed_W 0;
BA_ "GenSigTimeoutTime_CVADAS" SG_ 262 EngineSpeed_W 0;
BA_ "GenSigTimeoutTime_PAM" SG_ 262 EngineSpeed_W 0;
BA_ "GenSigTimeoutTime_SGW" SG_ 262 EngineSpeed_W 0;
BA_ "GenSigTimeoutTime_TRSKM" SG_ 262 EngineSpeed_W 0;
BA_ "GenSigTimeoutTime_BCM" SG_ 262 EngineSpeedFailSts_W 0;
BA_ "GenSigTimeoutTime_BSM2" SG_ 262 EngineSpeedFailSts_W 0;
BA_ "GenSigTimeoutTime_CADM2" SG_ 262 EngineSpeedFailSts_W 0;
BA_ "GenSigTimeoutTime_CVADAS" SG_ 262 EngineSpeedFailSts_W 0;
BA_ "GenSigTimeoutTime_EPS" SG_ 262 EngineSpeedFailSts_W 0;
BA_ "GenSigTimeoutTime_PAM" SG_ 262 EngineSpeedFailSts_W 0;
BA_ "GenSigTimeoutTime_SGW" SG_ 262 EngineSpeedFailSts_W 0;
BA_ "GenSigTimeoutTime_TRSKM" SG_ 262 EngineSpeedFailSts_W 0;
BA_ "GenSigStartValue" SG_ 262 EngineSts_W 3;
BA_ "GenSigTimeoutTime_BCM" SG_ 262 EngineSts_W 0;
BA_ "GenSigTimeoutTime_BSM2" SG_ 262 EngineSts_W 0;
BA_ "GenSigTimeoutTime_CADM2" SG_ 262 EngineSts_W 0;
BA_ "GenSigTimeoutTime_ORC" SG_ 262 EngineSts_W 0;
BA_ "GenSigTimeoutTime_PAM" SG_ 262 EngineSts_W 0;
BA_ "GenSigTimeoutTime_SGW" SG_ 262 EngineSts_W 0;
BA_ "GenSigTimeoutTime_TRSKM" SG_ 262 EngineSts_W 0;
BA_ "GenSigTimeoutTime_BCM" SG_ 262 EngTrq_Enbl_Rq_TCM_W 0;
BA_ "GenSigTimeoutTime_BSM2" SG_ 262 EngTrq_Enbl_Rq_TCM_W 0;
BA_ "GenSigTimeoutTime_CADM2" SG_ 262 EngTrq_Enbl_Rq_TCM_W 0;
BA_ "GenSigTimeoutTime_CVADAS" SG_ 262 EngTrq_Enbl_Rq_TCM_W 0;
BA_ "GenSigTimeoutTime_EPS" SG_ 262 EngTrq_Enbl_Rq_TCM_W 0;
BA_ "GenSigTimeoutTime_PAM" SG_ 262 EngTrq_Enbl_Rq_TCM_W 0;
BA_ "GenSigTimeoutTime_SGW" SG_ 262 EngTrq_Enbl_Rq_TCM_W 0;
BA_ "GenSigTimeoutTime_TRSKM" SG_ 262 EngTrq_Enbl_Rq_TCM_W 0;
BA_ "GenSigStartValue" SG_ 262 ESS_ENG_ST_W 15;
BA_ "GenSigSendType" SG_ 262 ESS_ENG_ST_W 3;
BA_ "GenSigTimeoutTime_BCM" SG_ 262 ESS_ENG_ST_W 0;
BA_ "GenSigTimeoutTime_BSM2" SG_ 262 ESS_ENG_ST_W 0;
BA_ "GenSigTimeoutTime_SGW" SG_ 262 ESS_ENG_ST_W 0;
BA_ "GenSigTimeoutTime_TRSKM" SG_ 262 ESS_ENG_ST_W 0;
BA_ "GenSigTimeoutTime_BCM" SG_ 262 ESS_RqShftPark_W 0;
BA_ "GenSigTimeoutTime_BSM2" SG_ 262 ESS_RqShftPark_W 0;
BA_ "GenSigTimeoutTime_CADM2" SG_ 262 ESS_RqShftPark_W 0;
BA_ "GenSigTimeoutTime_CVADAS" SG_ 262 ESS_RqShftPark_W 0;
BA_ "GenSigTimeoutTime_EPS" SG_ 262 ESS_RqShftPark_W 0;
BA_ "GenSigTimeoutTime_PAM" SG_ 262 ESS_RqShftPark_W 0;
BA_ "GenSigTimeoutTime_SGW" SG_ 262 ESS_RqShftPark_W 0;
BA_ "GenSigTimeoutTime_TRSKM" SG_ 262 ESS_RqShftPark_W 0;
BA_ "GenSigTimeoutTime_BCM" SG_ 262 GasPedalPositionFailSts_W 0;
BA_ "GenSigTimeoutTime_BSM2" SG_ 262 GasPedalPositionFailSts_W 0;
BA_ "GenSigTimeoutTime_CADM2" SG_ 262 GasPedalPositionFailSts_W 0;
BA_ "GenSigTimeoutTime_CVADAS" SG_ 262 GasPedalPositionFailSts_W 0;
BA_ "GenSigTimeoutTime_EPS" SG_ 262 GasPedalPositionFailSts_W 0;
BA_ "GenSigTimeoutTime_PAM" SG_ 262 GasPedalPositionFailSts_W 0;
BA_ "GenSigTimeoutTime_SGW" SG_ 262 GasPedalPositionFailSts_W 0;
BA_ "GenSigTimeoutTime_TRSKM" SG_ 262 GasPedalPositionFailSts_W 0;
BA_ "GenSigTimeoutTime_BCM" SG_ 262 MessageCounter_ENGINE2 0;
BA_ "GenSigTimeoutTime_BSM2" SG_ 262 MessageCounter_ENGINE2 0;
BA_ "GenSigTimeoutTime_ORC" SG_ 262 MessageCounter_ENGINE2 0;
BA_ "GenSigTimeoutTime_SGW" SG_ 262 MessageCounter_ENGINE2 0;
BA_ "GenSigTimeoutTime_TRSKM" SG_ 262 MessageCounter_ENGINE2 0;
BA_ "GenSigTimeoutTime_BCM" SG_ 262 PowertrainPrplsnActv 0;
BA_ "GenSigTimeoutTime_BSM2" SG_ 262 PowertrainPrplsnActv 0;
BA_ "GenSigTimeoutTime_CVADAS" SG_ 262 PowertrainPrplsnActv 0;
BA_ "GenSigTimeoutTime_PAM" SG_ 262 PowertrainPrplsnActv 0;
BA_ "GenSigTimeoutTime_SGW" SG_ 262 PowertrainPrplsnActv 0;
BA_ "GenSigTimeoutTime_TRSKM" SG_ 262 PowertrainPrplsnActv 0;
BA_ "GenSigTimeoutTime_BCM" SG_ 518 CRC_ENGINE5 0;
BA_ "GenSigTimeoutTime_CVADAS" SG_ 518 CRC_ENGINE5 0;
BA_ "GenSigTimeoutTime_EPS" SG_ 518 CRC_ENGINE5 0;
BA_ "GenSigTimeoutTime_ORC" SG_ 518 CRC_ENGINE5 0;
BA_ "GenSigTimeoutTime_PAM" SG_ 518 CRC_ENGINE5 0;
BA_ "GenSigTimeoutTime_SGW" SG_ 518 CRC_ENGINE5 0;
BA_ "GenSigTimeoutTime_TRSKM" SG_ 518 CRC_ENGINE5 0;
BA_ "GenSigTimeoutTime_BCM" SG_ 518 MessageCounter_ENGINE5 0;
BA_ "GenSigTimeoutTime_CVADAS" SG_ 518 MessageCounter_ENGINE5 0;
BA_ "GenSigTimeoutTime_EPS" SG_ 518 MessageCounter_ENGINE5 0;
BA_ "GenSigTimeoutTime_ORC" SG_ 518 MessageCounter_ENGINE5 0;
BA_ "GenSigTimeoutTime_PAM" SG_ 518 MessageCounter_ENGINE5 0;
BA_ "GenSigTimeoutTime_SGW" SG_ 518 MessageCounter_ENGINE5 0;
BA_ "GenSigTimeoutTime_TRSKM" SG_ 518 MessageCounter_ENGINE5 0;
BA_ "GenSigStartValue" SG_ 518 PdlPosActual 1;
BA_ "GenSigTimeoutTime_BCM" SG_ 518 PdlPosActual 0;
BA_ "GenSigTimeoutTime_EPS" SG_ 518 PdlPosActual 0;
BA_ "GenSigTimeoutTime_PAM" SG_ 518 PdlPosActual 0;
BA_ "GenSigTimeoutTime_SGW" SG_ 518 PdlPosActual 0;
BA_ "GenSigTimeoutTime_TRSKM" SG_ 518 PdlPosActual 0;
BA_ "GenSigStartValue" SG_ 751 TerrainModeStat_ECM 31;
BA_ "GenSigTimeoutTime_BCM" SG_ 751 TerrainModeStat_ECM 0;
BA_ "GenSigTimeoutTime_BSM2" SG_ 751 TerrainModeStat_ECM 0;
BA_ "GenSigTimeoutTime_CADM2" SG_ 751 TerrainModeStat_ECM 0;
BA_ "GenSigTimeoutTime_CVADAS" SG_ 751 TerrainModeStat_ECM 0;
BA_ "GenSigTimeoutTime_EPS" SG_ 751 TerrainModeStat_ECM 0;
BA_ "GenSigTimeoutTime_PAM" SG_ 751 TerrainModeStat_ECM 0;
BA_ "GenSigTimeoutTime_SGW" SG_ 751 TerrainModeStat_ECM 0;
BA_ "GenSigTimeoutTime_TRSKM" SG_ 751 TerrainModeStat_ECM 0;
BA_ "GenSigTimeoutTime_BCM" SG_ 1448 CRC_ENGINE7 0;
BA_ "GenSigTimeoutTime_BSM2" SG_ 1448 CRC_ENGINE7 0;
BA_ "GenSigTimeoutTime_CADM2" SG_ 1448 CRC_ENGINE7 0;
BA_ "GenSigTimeoutTime_EPS" SG_ 1448 CRC_ENGINE7 0;
BA_ "GenSigTimeoutTime_ORC" SG_ 1448 CRC_ENGINE7 0;
BA_ "GenSigTimeoutTime_PAM" SG_ 1448 CRC_ENGINE7 0;
BA_ "GenSigTimeoutTime_SGW" SG_ 1448 CRC_ENGINE7 0;
BA_ "GenSigTimeoutTime_TRSKM" SG_ 1448 CRC_ENGINE7 0;
BA_ "GenSigSendType" SG_ 1448 ECM_THA_Resp 4;
BA_ "GenSigTimeoutTime_BCM" SG_ 1448 ECM_THA_Resp 0;
BA_ "GenSigTimeoutTime_BSM2" SG_ 1448 ECM_THA_Resp 0;
BA_ "GenSigTimeoutTime_CADM2" SG_ 1448 ECM_THA_Resp 0;
BA_ "GenSigTimeoutTime_EPS" SG_ 1448 ECM_THA_Resp 0;
BA_ "GenSigTimeoutTime_ORC" SG_ 1448 ECM_THA_Resp 0;
BA_ "GenSigTimeoutTime_PAM" SG_ 1448 ECM_THA_Resp 0;
BA_ "GenSigTimeoutTime_SGW" SG_ 1448 ECM_THA_Resp 0;
BA_ "GenSigTimeoutTime_TRSKM" SG_ 1448 ECM_THA_Resp 0;
BA_ "GenSigSendType" SG_ 1448 ECM_TRSC_Resp 3;
BA_ "GenSigTimeoutTime_BCM" SG_ 1448 ECM_TRSC_Resp 0;
BA_ "GenSigTimeoutTime_BSM2" SG_ 1448 ECM_TRSC_Resp 0;
BA_ "GenSigTimeoutTime_CADM2" SG_ 1448 ECM_TRSC_Resp 0;
BA_ "GenSigTimeoutTime_EPS" SG_ 1448 ECM_TRSC_Resp 0;
BA_ "GenSigTimeoutTime_ORC" SG_ 1448 ECM_TRSC_Resp 0;
BA_ "GenSigTimeoutTime_PAM" SG_ 1448 ECM_TRSC_Resp 0;
BA_ "GenSigTimeoutTime_SGW" SG_ 1448 ECM_TRSC_Resp 0;
BA_ "GenSigTimeoutTime_TRSKM" SG_ 1448 ECM_TRSC_Resp 0;
BA_ "GenSigStartValue" SG_ 1448 EMSFailSts 2;
BA_ "GenSigSendType" SG_ 1448 EMSFailSts 3;
BA_ "GenSigTimeoutTime_BCM" SG_ 1448 EMSFailSts 0;
BA_ "GenSigTimeoutTime_BSM2" SG_ 1448 EMSFailSts 0;
BA_ "GenSigTimeoutTime_CADM2" SG_ 1448 EMSFailSts 0;
BA_ "GenSigTimeoutTime_CVADAS" SG_ 1448 EMSFailSts 0;
BA_ "GenSigTimeoutTime_EPS" SG_ 1448 EMSFailSts 0;
BA_ "GenSigTimeoutTime_PAM" SG_ 1448 EMSFailSts 0;
BA_ "GenSigTimeoutTime_SGW" SG_ 1448 EMSFailSts 0;
BA_ "GenSigTimeoutTime_TRSKM" SG_ 1448 EMSFailSts 0;
BA_ "GenSigSendType" SG_ 1448 ETCFailSts 3;
BA_ "GenSigTimeoutTime_BCM" SG_ 1448 ETCFailSts 0;
BA_ "GenSigTimeoutTime_BSM2" SG_ 1448 ETCFailSts 0;
BA_ "GenSigTimeoutTime_CADM2" SG_ 1448 ETCFailSts 0;
BA_ "GenSigTimeoutTime_CVADAS" SG_ 1448 ETCFailSts 0;
BA_ "GenSigTimeoutTime_EPS" SG_ 1448 ETCFailSts 0;
BA_ "GenSigTimeoutTime_PAM" SG_ 1448 ETCFailSts 0;
BA_ "GenSigTimeoutTime_SGW" SG_ 1448 ETCFailSts 0;
BA_ "GenSigTimeoutTime_TRSKM" SG_ 1448 ETCFailSts 0;
BA_ "GenSigTimeoutTime_BCM" SG_ 1448 MessageCounter_ENGINE7 0;
BA_ "GenSigTimeoutTime_BSM2" SG_ 1448 MessageCounter_ENGINE7 0;
BA_ "GenSigTimeoutTime_CADM2" SG_ 1448 MessageCounter_ENGINE7 0;
BA_ "GenSigTimeoutTime_EPS" SG_ 1448 MessageCounter_ENGINE7 0;
BA_ "GenSigTimeoutTime_ORC" SG_ 1448 MessageCounter_ENGINE7 0;
BA_ "GenSigTimeoutTime_PAM" SG_ 1448 MessageCounter_ENGINE7 0;
BA_ "GenSigTimeoutTime_SGW" SG_ 1448 MessageCounter_ENGINE7 0;
BA_ "GenSigTimeoutTime_TRSKM" SG_ 1448 MessageCounter_ENGINE7 0;
BA_ "GenSigSendType" SG_ 1448 SpStDispstat 3;
BA_ "GenSigTimeoutTime_BCM" SG_ 1448 SpStDispstat 0;
BA_ "GenSigTimeoutTime_BSM2" SG_ 1448 SpStDispstat 0;
BA_ "GenSigTimeoutTime_CADM2" SG_ 1448 SpStDispstat 0;
BA_ "GenSigTimeoutTime_CVADAS" SG_ 1448 SpStDispstat 0;
BA_ "GenSigTimeoutTime_EPS" SG_ 1448 SpStDispstat 0;
BA_ "GenSigTimeoutTime_PAM" SG_ 1448 SpStDispstat 0;
BA_ "GenSigTimeoutTime_SGW" SG_ 1448 SpStDispstat 0;
BA_ "GenSigTimeoutTime_TRSKM" SG_ 1448 SpStDispstat 0;
BA_ "GenSigSendType" SG_ 1448 SpStSwStat 3;
BA_ "GenSigTimeoutTime_BCM" SG_ 1448 SpStSwStat 0;
BA_ "GenSigTimeoutTime_BSM2" SG_ 1448 SpStSwStat 0;
BA_ "GenSigTimeoutTime_CADM2" SG_ 1448 SpStSwStat 0;
BA_ "GenSigTimeoutTime_CVADAS" SG_ 1448 SpStSwStat 0;
BA_ "GenSigTimeoutTime_EPS" SG_ 1448 SpStSwStat 0;
BA_ "GenSigTimeoutTime_PAM" SG_ 1448 SpStSwStat 0;
BA_ "GenSigTimeoutTime_SGW" SG_ 1448 SpStSwStat 0;
BA_ "GenSigTimeoutTime_TRSKM" SG_ 1448 SpStSwStat 0;
BA_ "GenSigTimeoutTime_BCM" SG_ 1055 GF_Charge 0;
BA_ "GenSigTimeoutTime_BSM2" SG_ 1055 GF_Charge 0;
BA_ "GenSigTimeoutTime_CADM2" SG_ 1055 GF_Charge 0;
BA_ "GenSigTimeoutTime_CVADAS" SG_ 1055 GF_Charge 0;
BA_ "GenSigTimeoutTime_EPS" SG_ 1055 GF_Charge 0;
BA_ "GenSigTimeoutTime_PAM" SG_ 1055 GF_Charge 0;
BA_ "GenSigTimeoutTime_SGW" SG_ 1055 GF_Charge 0;
BA_ "GenSigTimeoutTime_TRSKM" SG_ 1055 GF_Charge 0;
BA_ "GenSigStartValue" SG_ 1055 MAP_4_BAR 511;
BA_ "GenSigTimeoutTime_BCM" SG_ 1055 MAP_4_BAR 0;
BA_ "GenSigTimeoutTime_BSM2" SG_ 1055 MAP_4_BAR 0;
BA_ "GenSigTimeoutTime_CADM2" SG_ 1055 MAP_4_BAR 0;
BA_ "GenSigTimeoutTime_CVADAS" SG_ 1055 MAP_4_BAR 0;
BA_ "GenSigTimeoutTime_EPS" SG_ 1055 MAP_4_BAR 0;
BA_ "GenSigTimeoutTime_PAM" SG_ 1055 MAP_4_BAR 0;
BA_ "GenSigTimeoutTime_SGW" SG_ 1055 MAP_4_BAR 0;
BA_ "GenSigTimeoutTime_TRSKM" SG_ 1055 MAP_4_BAR 0;
BA_ "GenSigTimeoutTime_EPS" SG_ 264 CRC_EPS1 0;
BA_ "GenSigTimeoutTime_SGW" SG_ 264 CRC_EPS1 0;
BA_ "GenSigTimeoutTime_TRSKM" SG_ 264 CRC_EPS1 0;
BA_ "GenSigTimeoutTime_BSM2" SG_ 264 ElectricSteeringFailSts 0;
BA_ "GenSigTimeoutTime_CADM2" SG_ 264 ElectricSteeringFailSts 0;
BA_ "GenSigTimeoutTime_CVADAS" SG_ 264 ElectricSteeringFailSts 0;
BA_ "GenSigTimeoutTime_EPS" SG_ 264 ElectricSteeringFailSts 0;
BA_ "GenSigTimeoutTime_ORC" SG_ 264 ElectricSteeringFailSts 0;
BA_ "GenSigTimeoutTime_PAM" SG_ 264 ElectricSteeringFailSts 0;
BA_ "GenSigTimeoutTime_TRSKM" SG_ 264 ElectricSteeringFailSts 0;
BA_ "GenSigTimeoutTime_BSM2" SG_ 264 EngineFanRequestActivation 0;
BA_ "GenSigTimeoutTime_CADM2" SG_ 264 EngineFanRequestActivation 0;
BA_ "GenSigTimeoutTime_CVADAS" SG_ 264 EngineFanRequestActivation 0;
BA_ "GenSigTimeoutTime_EPS" SG_ 264 EngineFanRequestActivation 0;
BA_ "GenSigTimeoutTime_ORC" SG_ 264 EngineFanRequestActivation 0;
BA_ "GenSigTimeoutTime_PAM" SG_ 264 EngineFanRequestActivation 0;
BA_ "GenSigTimeoutTime_SGW" SG_ 264 EngineFanRequestActivation 0;
BA_ "GenSigTimeoutTime_TRSKM" SG_ 264 EngineFanRequestActivation 0;
BA_ "GenSigStartValue" SG_ 264 EPS_AsstStat 1;
BA_ "GenSigTimeoutTime_BCM" SG_ 264 EPS_AsstStat 0;
BA_ "GenSigTimeoutTime_BSM2" SG_ 264 EPS_AsstStat 0;
BA_ "GenSigTimeoutTime_CVADAS" SG_ 264 EPS_AsstStat 0;
BA_ "GenSigTimeoutTime_EPS" SG_ 264 EPS_AsstStat 0;
BA_ "GenSigTimeoutTime_ORC" SG_ 264 EPS_AsstStat 0;
BA_ "GenSigTimeoutTime_PAM" SG_ 264 EPS_AsstStat 0;
BA_ "GenSigTimeoutTime_SGW" SG_ 264 EPS_AsstStat 0;
BA_ "GenSigTimeoutTime_TRSKM" SG_ 264 EPS_AsstStat 0;
BA_ "GenSigStartValue" SG_ 264 EPS_Curr 255;
BA_ "GenSigTimeoutTime_BCM" SG_ 264 EPS_Curr 0;
BA_ "GenSigTimeoutTime_BSM2" SG_ 264 EPS_Curr 0;
BA_ "GenSigTimeoutTime_CADM2" SG_ 264 EPS_Curr 0;
BA_ "GenSigTimeoutTime_CVADAS" SG_ 264 EPS_Curr 0;
BA_ "GenSigTimeoutTime_EPS" SG_ 264 EPS_Curr 0;
BA_ "GenSigTimeoutTime_ORC" SG_ 264 EPS_Curr 0;
BA_ "GenSigTimeoutTime_PAM" SG_ 264 EPS_Curr 0;
BA_ "GenSigTimeoutTime_SGW" SG_ 264 EPS_Curr 0;
BA_ "GenSigTimeoutTime_TRSKM" SG_ 264 EPS_Curr 0;
BA_ "GenSigTimeoutTime_BCM" SG_ 264 EPS_Hands_On_Sts 0;
BA_ "GenSigTimeoutTime_BSM2" SG_ 264 EPS_Hands_On_Sts 0;
BA_ "GenSigTimeoutTime_CVADAS" SG_ 264 EPS_Hands_On_Sts 0;
BA_ "GenSigTimeoutTime_EPS" SG_ 264 EPS_Hands_On_Sts 0;
BA_ "GenSigTimeoutTime_ORC" SG_ 264 EPS_Hands_On_Sts 0;
BA_ "GenSigTimeoutTime_PAM" SG_ 264 EPS_Hands_On_Sts 0;
BA_ "GenSigTimeoutTime_SGW" SG_ 264 EPS_Hands_On_Sts 0;
BA_ "GenSigTimeoutTime_TRSKM" SG_ 264 EPS_Hands_On_Sts 0;
BA_ "GenSigTimeoutTime_BCM" SG_ 264 EPS_IMC_Fault 0;
BA_ "GenSigTimeoutTime_BSM2" SG_ 264 EPS_IMC_Fault 0;
BA_ "GenSigTimeoutTime_CVADAS" SG_ 264 EPS_IMC_Fault 0;
BA_ "GenSigTimeoutTime_EPS" SG_ 264 EPS_IMC_Fault 0;
BA_ "GenSigTimeoutTime_ORC" SG_ 264 EPS_IMC_Fault 0;
BA_ "GenSigTimeoutTime_PAM" SG_ 264 EPS_IMC_Fault 0;
BA_ "GenSigTimeoutTime_SGW" SG_ 264 EPS_IMC_Fault 0;
BA_ "GenSigTimeoutTime_TRSKM" SG_ 264 EPS_IMC_Fault 0;
BA_ "GenSigStartValue" SG_ 264 EPSMotorTorque 1024;
BA_ "GenSigTimeoutTime_BCM" SG_ 264 EPSMotorTorque 0;
BA_ "GenSigTimeoutTime_BSM2" SG_ 264 EPSMotorTorque 0;
BA_ "GenSigTimeoutTime_CVADAS" SG_ 264 EPSMotorTorque 0;
BA_ "GenSigTimeoutTime_EPS" SG_ 264 EPSMotorTorque 0;
BA_ "GenSigTimeoutTime_ORC" SG_ 264 EPSMotorTorque 0;
BA_ "GenSigTimeoutTime_PAM" SG_ 264 EPSMotorTorque 0;
BA_ "GenSigTimeoutTime_SGW" SG_ 264 EPSMotorTorque 0;
BA_ "GenSigTimeoutTime_TRSKM" SG_ 264 EPSMotorTorque 0;
BA_ "GenSigTimeoutTime_BCM" SG_ 264 HAS_LAT_CTRL_ResponseSts_2 0;
BA_ "GenSigTimeoutTime_BSM2" SG_ 264 HAS_LAT_CTRL_ResponseSts_2 0;
BA_ "GenSigTimeoutTime_CVADAS" SG_ 264 HAS_LAT_CTRL_ResponseSts_2 0;
BA_ "GenSigTimeoutTime_EPS" SG_ 264 HAS_LAT_CTRL_ResponseSts_2 0;
BA_ "GenSigTimeoutTime_ORC" SG_ 264 HAS_LAT_CTRL_ResponseSts_2 0;
BA_ "GenSigTimeoutTime_PAM" SG_ 264 HAS_LAT_CTRL_ResponseSts_2 0;
BA_ "GenSigTimeoutTime_SGW" SG_ 264 HAS_LAT_CTRL_ResponseSts_2 0;
BA_ "GenSigTimeoutTime_TRSKM" SG_ 264 HAS_LAT_CTRL_ResponseSts_2 0;
BA_ "GenSigTimeoutTime_EPS" SG_ 264 LwsAngle 0;
BA_ "GenSigTimeoutTime_TRSKM" SG_ 264 LwsAngle 0;
BA_ "GenSigTimeoutTime_EPS" SG_ 264 LwsAngleType 0;
BA_ "GenSigTimeoutTime_PAM" SG_ 264 LwsAngleType 0;
BA_ "GenSigTimeoutTime_TRSKM" SG_ 264 LwsAngleType 0;
BA_ "GenSigTimeoutTime_CADM2" SG_ 264 LwsCalibration 0;
BA_ "GenSigTimeoutTime_CVADAS" SG_ 264 LwsCalibration 0;
BA_ "GenSigTimeoutTime_EPS" SG_ 264 LwsCalibration 0;
BA_ "GenSigTimeoutTime_ORC" SG_ 264 LwsCalibration 0;
BA_ "GenSigTimeoutTime_PAM" SG_ 264 LwsCalibration 0;
BA_ "GenSigTimeoutTime_TRSKM" SG_ 264 LwsCalibration 0;
BA_ "GenSigTimeoutTime_BSM2" SG_ 264 LwsSpeed 0;
BA_ "GenSigTimeoutTime_EPS" SG_ 264 LwsSpeed 0;
BA_ "GenSigTimeoutTime_ORC" SG_ 264 LwsSpeed 0;
BA_ "GenSigTimeoutTime_TRSKM" SG_ 264 LwsSpeed 0;
BA_ "GenSigTimeoutTime_EPS" SG_ 264 MessageCounter_EPS1 0;
BA_ "GenSigTimeoutTime_SGW" SG_ 264 MessageCounter_EPS1 0;
BA_ "GenSigTimeoutTime_TRSKM" SG_ 264 MessageCounter_EPS1 0;
BA_ "GenSigTimeoutTime_BCM" SG_ 264 Steering_Column_Torque 0;
BA_ "GenSigTimeoutTime_BSM2" SG_ 264 Steering_Column_Torque 0;
BA_ "GenSigTimeoutTime_CVADAS" SG_ 264 Steering_Column_Torque 0;
BA_ "GenSigTimeoutTime_EPS" SG_ 264 Steering_Column_Torque 0;
BA_ "GenSigTimeoutTime_PAM" SG_ 264 Steering_Column_Torque 0;
BA_ "GenSigTimeoutTime_SGW" SG_ 264 Steering_Column_Torque 0;
BA_ "GenSigTimeoutTime_TRSKM" SG_ 264 Steering_Column_Torque 0;
BA_ "GenSigTimeoutTime_BCM" SG_ 264 Steering_OpStat_Sec 0;
BA_ "GenSigTimeoutTime_BSM2" SG_ 264 Steering_OpStat_Sec 0;
BA_ "GenSigTimeoutTime_CVADAS" SG_ 264 Steering_OpStat_Sec 0;
BA_ "GenSigTimeoutTime_EPS" SG_ 264 Steering_OpStat_Sec 0;
BA_ "GenSigTimeoutTime_PAM" SG_ 264 Steering_OpStat_Sec 0;
BA_ "GenSigTimeoutTime_SGW" SG_ 264 Steering_OpStat_Sec 0;
BA_ "GenSigTimeoutTime_TRSKM" SG_ 264 Steering_OpStat_Sec 0;
BA_ "GenSigTimeoutTime_BCM" SG_ 1056 CRC_EPS2 0;
BA_ "GenSigTimeoutTime_BSM2" SG_ 1056 CRC_EPS2 0;
BA_ "GenSigTimeoutTime_CADM2" SG_ 1056 CRC_EPS2 0;
BA_ "GenSigTimeoutTime_EPS" SG_ 1056 CRC_EPS2 0;
BA_ "GenSigTimeoutTime_ORC" SG_ 1056 CRC_EPS2 0;
BA_ "GenSigTimeoutTime_PAM" SG_ 1056 CRC_EPS2 0;
BA_ "GenSigTimeoutTime_SGW" SG_ 1056 CRC_EPS2 0;
BA_ "GenSigTimeoutTime_TRSKM" SG_ 1056 CRC_EPS2 0;
BA_ "GenSigTimeoutTime_BCM" SG_ 1056 EPS_MODE_STAT 0;
BA_ "GenSigTimeoutTime_BSM2" SG_ 1056 EPS_MODE_STAT 0;
BA_ "GenSigTimeoutTime_CADM2" SG_ 1056 EPS_MODE_STAT 0;
BA_ "GenSigTimeoutTime_CVADAS" SG_ 1056 EPS_MODE_STAT 0;
BA_ "GenSigTimeoutTime_EPS" SG_ 1056 EPS_MODE_STAT 0;
BA_ "GenSigTimeoutTime_PAM" SG_ 1056 EPS_MODE_STAT 0;
BA_ "GenSigTimeoutTime_TRSKM" SG_ 1056 EPS_MODE_STAT 0;
BA_ "GenSigTimeoutTime_BCM" SG_ 1056 EPS_SteeringTouchStat 0;
BA_ "GenSigTimeoutTime_BSM2" SG_ 1056 EPS_SteeringTouchStat 0;
BA_ "GenSigTimeoutTime_CADM2" SG_ 1056 EPS_SteeringTouchStat 0;
BA_ "GenSigTimeoutTime_EPS" SG_ 1056 EPS_SteeringTouchStat 0;
BA_ "GenSigTimeoutTime_ORC" SG_ 1056 EPS_SteeringTouchStat 0;
BA_ "GenSigTimeoutTime_PAM" SG_ 1056 EPS_SteeringTouchStat 0;
BA_ "GenSigTimeoutTime_SGW" SG_ 1056 EPS_SteeringTouchStat 0;
BA_ "GenSigTimeoutTime_TRSKM" SG_ 1056 EPS_SteeringTouchStat 0;
BA_ "GenSigTimeoutTime_BCM" SG_ 1056 EPS_SteeringTouq_Resp 0;
BA_ "GenSigTimeoutTime_BSM2" SG_ 1056 EPS_SteeringTouq_Resp 0;
BA_ "GenSigTimeoutTime_CADM2" SG_ 1056 EPS_SteeringTouq_Resp 0;
BA_ "GenSigTimeoutTime_EPS" SG_ 1056 EPS_SteeringTouq_Resp 0;
BA_ "GenSigTimeoutTime_ORC" SG_ 1056 EPS_SteeringTouq_Resp 0;
BA_ "GenSigTimeoutTime_PAM" SG_ 1056 EPS_SteeringTouq_Resp 0;
BA_ "GenSigTimeoutTime_SGW" SG_ 1056 EPS_SteeringTouq_Resp 0;
BA_ "GenSigTimeoutTime_TRSKM" SG_ 1056 EPS_SteeringTouq_Resp 0;
BA_ "GenSigTimeoutTime_BCM" SG_ 1056 EPS_THA_DriverTorqueOverride 0;
BA_ "GenSigTimeoutTime_BSM2" SG_ 1056 EPS_THA_DriverTorqueOverride 0;
BA_ "GenSigTimeoutTime_CADM2" SG_ 1056 EPS_THA_DriverTorqueOverride 0;
BA_ "GenSigTimeoutTime_EPS" SG_ 1056 EPS_THA_DriverTorqueOverride 0;
BA_ "GenSigTimeoutTime_ORC" SG_ 1056 EPS_THA_DriverTorqueOverride 0;
BA_ "GenSigTimeoutTime_PAM" SG_ 1056 EPS_THA_DriverTorqueOverride 0;
BA_ "GenSigTimeoutTime_SGW" SG_ 1056 EPS_THA_DriverTorqueOverride 0;
BA_ "GenSigTimeoutTime_TRSKM" SG_ 1056 EPS_THA_DriverTorqueOverride 0;
BA_ "GenSigTimeoutTime_BCM" SG_ 1056 EPS_THA_SteeringTorqueResp 0;
BA_ "GenSigTimeoutTime_BSM2" SG_ 1056 EPS_THA_SteeringTorqueResp 0;
BA_ "GenSigTimeoutTime_CADM2" SG_ 1056 EPS_THA_SteeringTorqueResp 0;
BA_ "GenSigTimeoutTime_EPS" SG_ 1056 EPS_THA_SteeringTorqueResp 0;
BA_ "GenSigTimeoutTime_ORC" SG_ 1056 EPS_THA_SteeringTorqueResp 0;
BA_ "GenSigTimeoutTime_PAM" SG_ 1056 EPS_THA_SteeringTorqueResp 0;
BA_ "GenSigTimeoutTime_SGW" SG_ 1056 EPS_THA_SteeringTorqueResp 0;
BA_ "GenSigTimeoutTime_TRSKM" SG_ 1056 EPS_THA_SteeringTorqueResp 0;
BA_ "GenSigTimeoutTime_BSM2" SG_ 1056 EPS_Warn_Disp_Rq 0;
BA_ "GenSigTimeoutTime_CADM2" SG_ 1056 EPS_Warn_Disp_Rq 0;
BA_ "GenSigTimeoutTime_CVADAS" SG_ 1056 EPS_Warn_Disp_Rq 0;
BA_ "GenSigTimeoutTime_EPS" SG_ 1056 EPS_Warn_Disp_Rq 0;
BA_ "GenSigTimeoutTime_PAM" SG_ 1056 EPS_Warn_Disp_Rq 0;
BA_ "GenSigTimeoutTime_TRSKM" SG_ 1056 EPS_Warn_Disp_Rq 0;
BA_ "GenSigTimeoutTime_BCM" SG_ 1056 MessageCounter_EPS2 0;
BA_ "GenSigTimeoutTime_BSM2" SG_ 1056 MessageCounter_EPS2 0;
BA_ "GenSigTimeoutTime_CADM2" SG_ 1056 MessageCounter_EPS2 0;
BA_ "GenSigTimeoutTime_EPS" SG_ 1056 MessageCounter_EPS2 0;
BA_ "GenSigTimeoutTime_ORC" SG_ 1056 MessageCounter_EPS2 0;
BA_ "GenSigTimeoutTime_PAM" SG_ 1056 MessageCounter_EPS2 0;
BA_ "GenSigTimeoutTime_SGW" SG_ 1056 MessageCounter_EPS2 0;
BA_ "GenSigTimeoutTime_TRSKM" SG_ 1056 MessageCounter_EPS2 0;
BA_ "GenSigTimeoutTime_BCM" SG_ 1056 THA_SteeringTouchStat 0;
BA_ "GenSigTimeoutTime_BSM2" SG_ 1056 THA_SteeringTouchStat 0;
BA_ "GenSigTimeoutTime_CADM2" SG_ 1056 THA_SteeringTouchStat 0;
BA_ "GenSigTimeoutTime_EPS" SG_ 1056 THA_SteeringTouchStat 0;
BA_ "GenSigTimeoutTime_ORC" SG_ 1056 THA_SteeringTouchStat 0;
BA_ "GenSigTimeoutTime_PAM" SG_ 1056 THA_SteeringTouchStat 0;
BA_ "GenSigTimeoutTime_SGW" SG_ 1056 THA_SteeringTouchStat 0;
BA_ "GenSigTimeoutTime_TRSKM" SG_ 1056 THA_SteeringTouchStat 0;
BA_ "GenSigSendType" SG_ 1460 CADM2_Big_ECU_Package 3;
BA_ "GenSigTimeoutTime_BCM" SG_ 1460 CADM2_Big_ECU_Package 0;
BA_ "GenSigTimeoutTime_BSM2" SG_ 1460 CADM2_Big_ECU_Package 0;
BA_ "GenSigTimeoutTime_CVADAS" SG_ 1460 CADM2_Big_ECU_Package 0;
BA_ "GenSigTimeoutTime_EPS" SG_ 1460 CADM2_Big_ECU_Package 0;
BA_ "GenSigTimeoutTime_ORC" SG_ 1460 CADM2_Big_ECU_Package 0;
BA_ "GenSigTimeoutTime_PAM" SG_ 1460 CADM2_Big_ECU_Package 0;
BA_ "GenSigTimeoutTime_SGW" SG_ 1460 CADM2_Big_ECU_Package 0;
BA_ "GenSigTimeoutTime_TRSKM" SG_ 1460 CADM2_Big_ECU_Package 0;
BA_ "GenSigStartValue" SG_ 1460 FOTA_Purge 1;
BA_ "GenSigSendType" SG_ 1460 FOTA_Purge 3;
BA_ "GenSigTimeoutTime_BCM" SG_ 1460 FOTA_Purge 0;
BA_ "GenSigTimeoutTime_BSM2" SG_ 1460 FOTA_Purge 0;
BA_ "GenSigTimeoutTime_CVADAS" SG_ 1460 FOTA_Purge 0;
BA_ "GenSigTimeoutTime_EPS" SG_ 1460 FOTA_Purge 0;
BA_ "GenSigTimeoutTime_ORC" SG_ 1460 FOTA_Purge 0;
BA_ "GenSigTimeoutTime_PAM" SG_ 1460 FOTA_Purge 0;
BA_ "GenSigTimeoutTime_SGW" SG_ 1460 FOTA_Purge 0;
BA_ "GenSigTimeoutTime_TRSKM" SG_ 1460 FOTA_Purge 0;
BA_ "GenSigSendType" SG_ 1460 FOTA_Status 3;
BA_ "GenSigTimeoutTime_BCM" SG_ 1460 FOTA_Status 0;
BA_ "GenSigTimeoutTime_BSM2" SG_ 1460 FOTA_Status 0;
BA_ "GenSigTimeoutTime_CVADAS" SG_ 1460 FOTA_Status 0;
BA_ "GenSigTimeoutTime_PAM" SG_ 1460 FOTA_Status 0;
BA_ "GenSigTimeoutTime_SGW" SG_ 1460 FOTA_Status 0;
BA_ "GenSigTimeoutTime_TRSKM" SG_ 1460 FOTA_Status 0;
BA_ "GenSigSendType" SG_ 1460 Safe_State 3;
BA_ "GenSigTimeoutTime_BCM" SG_ 1460 Safe_State 0;
BA_ "GenSigTimeoutTime_BSM2" SG_ 1460 Safe_State 0;
BA_ "GenSigTimeoutTime_CVADAS" SG_ 1460 Safe_State 0;
BA_ "GenSigTimeoutTime_EPS" SG_ 1460 Safe_State 0;
BA_ "GenSigTimeoutTime_ORC" SG_ 1460 Safe_State 0;
BA_ "GenSigTimeoutTime_PAM" SG_ 1460 Safe_State 0;
BA_ "GenSigTimeoutTime_SGW" SG_ 1460 Safe_State 0;
BA_ "GenSigTimeoutTime_TRSKM" SG_ 1460 Safe_State 0;
BA_ "GenSigTimeoutTime_BCM" SG_ 1847 Big_ECU_Ready_CADM2 0;
BA_ "GenSigTimeoutTime_BSM2" SG_ 1847 Big_ECU_Ready_CADM2 0;
BA_ "GenSigTimeoutTime_CADM2" SG_ 1847 Big_ECU_Ready_CADM2 0;
BA_ "GenSigTimeoutTime_CVADAS" SG_ 1847 Big_ECU_Ready_CADM2 0;
BA_ "GenSigTimeoutTime_EPS" SG_ 1847 Big_ECU_Ready_CADM2 0;
BA_ "GenSigTimeoutTime_ORC" SG_ 1847 Big_ECU_Ready_CADM2 0;
BA_ "GenSigTimeoutTime_PAM" SG_ 1847 Big_ECU_Ready_CADM2 0;
BA_ "GenSigTimeoutTime_TRSKM" SG_ 1847 Big_ECU_Ready_CADM2 0;
BA_ "GenSigTimeoutTime_BCM" SG_ 1847 Download_Status_CADM2 0;
BA_ "GenSigTimeoutTime_BSM2" SG_ 1847 Download_Status_CADM2 0;
BA_ "GenSigTimeoutTime_CADM2" SG_ 1847 Download_Status_CADM2 0;
BA_ "GenSigTimeoutTime_CVADAS" SG_ 1847 Download_Status_CADM2 0;
BA_ "GenSigTimeoutTime_EPS" SG_ 1847 Download_Status_CADM2 0;
BA_ "GenSigTimeoutTime_ORC" SG_ 1847 Download_Status_CADM2 0;
BA_ "GenSigTimeoutTime_PAM" SG_ 1847 Download_Status_CADM2 0;
BA_ "GenSigTimeoutTime_TRSKM" SG_ 1847 Download_Status_CADM2 0;
BA_ "GenSigTimeoutTime_BCM" SG_ 1847 Update_Status_CADM2 0;
BA_ "GenSigTimeoutTime_BSM2" SG_ 1847 Update_Status_CADM2 0;
BA_ "GenSigTimeoutTime_CADM2" SG_ 1847 Update_Status_CADM2 0;
BA_ "GenSigTimeoutTime_CVADAS" SG_ 1847 Update_Status_CADM2 0;
BA_ "GenSigTimeoutTime_EPS" SG_ 1847 Update_Status_CADM2 0;
BA_ "GenSigTimeoutTime_ORC" SG_ 1847 Update_Status_CADM2 0;
BA_ "GenSigTimeoutTime_PAM" SG_ 1847 Update_Status_CADM2 0;
BA_ "GenSigTimeoutTime_TRSKM" SG_ 1847 Update_Status_CADM2 0;
BA_ "GenSigTimeoutTime_BCM" SG_ 525 CRC_GLOB_NAV 0;
BA_ "GenSigTimeoutTime_BSM2" SG_ 525 CRC_GLOB_NAV 0;
BA_ "GenSigTimeoutTime_CVADAS" SG_ 525 CRC_GLOB_NAV 0;
BA_ "GenSigTimeoutTime_EPS" SG_ 525 CRC_GLOB_NAV 0;
BA_ "GenSigTimeoutTime_ORC" SG_ 525 CRC_GLOB_NAV 0;
BA_ "GenSigTimeoutTime_PAM" SG_ 525 CRC_GLOB_NAV 0;
BA_ "GenSigTimeoutTime_SGW" SG_ 525 CRC_GLOB_NAV 0;
BA_ "GenSigTimeoutTime_TRSKM" SG_ 525 CRC_GLOB_NAV 0;
BA_ "GenSigTimeoutTime_BCM" SG_ 525 GNMM_Health 0;
BA_ "GenSigTimeoutTime_BSM2" SG_ 525 GNMM_Health 0;
BA_ "GenSigTimeoutTime_CVADAS" SG_ 525 GNMM_Health 0;
BA_ "GenSigTimeoutTime_EPS" SG_ 525 GNMM_Health 0;
BA_ "GenSigTimeoutTime_ORC" SG_ 525 GNMM_Health 0;
BA_ "GenSigTimeoutTime_PAM" SG_ 525 GNMM_Health 0;
BA_ "GenSigTimeoutTime_SGW" SG_ 525 GNMM_Health 0;
BA_ "GenSigTimeoutTime_TRSKM" SG_ 525 GNMM_Health 0;
BA_ "GenSigTimeoutTime_BCM" SG_ 525 MessageCounter_GLOB_NAV 0;
BA_ "GenSigTimeoutTime_BSM2" SG_ 525 MessageCounter_GLOB_NAV 0;
BA_ "GenSigTimeoutTime_CVADAS" SG_ 525 MessageCounter_GLOB_NAV 0;
BA_ "GenSigTimeoutTime_EPS" SG_ 525 MessageCounter_GLOB_NAV 0;
BA_ "GenSigTimeoutTime_ORC" SG_ 525 MessageCounter_GLOB_NAV 0;
BA_ "GenSigTimeoutTime_PAM" SG_ 525 MessageCounter_GLOB_NAV 0;
BA_ "GenSigTimeoutTime_SGW" SG_ 525 MessageCounter_GLOB_NAV 0;
BA_ "GenSigTimeoutTime_TRSKM" SG_ 525 MessageCounter_GLOB_NAV 0;
BA_ "GenSigStartValue" SG_ 526 Altitude_RMSE_C2 255;
BA_ "GenSigTimeoutTime_BCM" SG_ 526 Altitude_RMSE_C2 0;
BA_ "GenSigTimeoutTime_BSM2" SG_ 526 Altitude_RMSE_C2 0;
BA_ "GenSigTimeoutTime_CADM2" SG_ 526 Altitude_RMSE_C2 0;
BA_ "GenSigTimeoutTime_EPS" SG_ 526 Altitude_RMSE_C2 0;
BA_ "GenSigTimeoutTime_ORC" SG_ 526 Altitude_RMSE_C2 0;
BA_ "GenSigTimeoutTime_PAM" SG_ 526 Altitude_RMSE_C2 0;
BA_ "GenSigTimeoutTime_SGW" SG_ 526 Altitude_RMSE_C2 0;
BA_ "GenSigTimeoutTime_TRSKM" SG_ 526 Altitude_RMSE_C2 0;
BA_ "GenSigTimeoutTime_BCM" SG_ 526 CRC_GLOB_NAV_C2 0;
BA_ "GenSigTimeoutTime_BSM2" SG_ 526 CRC_GLOB_NAV_C2 0;
BA_ "GenSigTimeoutTime_CADM2" SG_ 526 CRC_GLOB_NAV_C2 0;
BA_ "GenSigTimeoutTime_EPS" SG_ 526 CRC_GLOB_NAV_C2 0;
BA_ "GenSigTimeoutTime_ORC" SG_ 526 CRC_GLOB_NAV_C2 0;
BA_ "GenSigTimeoutTime_PAM" SG_ 526 CRC_GLOB_NAV_C2 0;
BA_ "GenSigTimeoutTime_SGW" SG_ 526 CRC_GLOB_NAV_C2 0;
BA_ "GenSigTimeoutTime_TRSKM" SG_ 526 CRC_GLOB_NAV_C2 0;
BA_ "GenSigStartValue" SG_ 526 DeltaTimestamp_IMUdata 255;
BA_ "GenSigTimeoutTime_BCM" SG_ 526 DeltaTimestamp_IMUdata 0;
BA_ "GenSigTimeoutTime_BSM2" SG_ 526 DeltaTimestamp_IMUdata 0;
BA_ "GenSigTimeoutTime_CADM2" SG_ 526 DeltaTimestamp_IMUdata 0;
BA_ "GenSigTimeoutTime_EPS" SG_ 526 DeltaTimestamp_IMUdata 0;
BA_ "GenSigTimeoutTime_ORC" SG_ 526 DeltaTimestamp_IMUdata 0;
BA_ "GenSigTimeoutTime_PAM" SG_ 526 DeltaTimestamp_IMUdata 0;
BA_ "GenSigTimeoutTime_SGW" SG_ 526 DeltaTimestamp_IMUdata 0;
BA_ "GenSigTimeoutTime_TRSKM" SG_ 526 DeltaTimestamp_IMUdata 0;
BA_ "GenSigStartValue" SG_ 526 Heading_Angle_C2 65535;
BA_ "GenSigTimeoutTime_BCM" SG_ 526 Heading_Angle_C2 0;
BA_ "GenSigTimeoutTime_BSM2" SG_ 526 Heading_Angle_C2 0;
BA_ "GenSigTimeoutTime_CADM2" SG_ 526 Heading_Angle_C2 0;
BA_ "GenSigTimeoutTime_EPS" SG_ 526 Heading_Angle_C2 0;
BA_ "GenSigTimeoutTime_ORC" SG_ 526 Heading_Angle_C2 0;
BA_ "GenSigTimeoutTime_PAM" SG_ 526 Heading_Angle_C2 0;
BA_ "GenSigTimeoutTime_SGW" SG_ 526 Heading_Angle_C2 0;
BA_ "GenSigTimeoutTime_TRSKM" SG_ 526 Heading_Angle_C2 0;
BA_ "GenSigStartValue" SG_ 526 LatAcceleration_C2 4095;
BA_ "GenSigTimeoutTime_BCM" SG_ 526 LatAcceleration_C2 0;
BA_ "GenSigTimeoutTime_BSM2" SG_ 526 LatAcceleration_C2 0;
BA_ "GenSigTimeoutTime_CADM2" SG_ 526 LatAcceleration_C2 0;
BA_ "GenSigTimeoutTime_EPS" SG_ 526 LatAcceleration_C2 0;
BA_ "GenSigTimeoutTime_ORC" SG_ 526 LatAcceleration_C2 0;
BA_ "GenSigTimeoutTime_PAM" SG_ 526 LatAcceleration_C2 0;
BA_ "GenSigTimeoutTime_SGW" SG_ 526 LatAcceleration_C2 0;
BA_ "GenSigTimeoutTime_TRSKM" SG_ 526 LatAcceleration_C2 0;
BA_ "GenSigStartValue" SG_ 526 Latitude_RMSE_C2 255;
BA_ "GenSigTimeoutTime_BCM" SG_ 526 Latitude_RMSE_C2 0;
BA_ "GenSigTimeoutTime_BSM2" SG_ 526 Latitude_RMSE_C2 0;
BA_ "GenSigTimeoutTime_CADM2" SG_ 526 Latitude_RMSE_C2 0;
BA_ "GenSigTimeoutTime_EPS" SG_ 526 Latitude_RMSE_C2 0;
BA_ "GenSigTimeoutTime_ORC" SG_ 526 Latitude_RMSE_C2 0;
BA_ "GenSigTimeoutTime_PAM" SG_ 526 Latitude_RMSE_C2 0;
BA_ "GenSigTimeoutTime_SGW" SG_ 526 Latitude_RMSE_C2 0;
BA_ "GenSigTimeoutTime_TRSKM" SG_ 526 Latitude_RMSE_C2 0;
BA_ "GenSigStartValue" SG_ 526 LongAcceleration_C2 4095;
BA_ "GenSigTimeoutTime_BCM" SG_ 526 LongAcceleration_C2 0;
BA_ "GenSigTimeoutTime_BSM2" SG_ 526 LongAcceleration_C2 0;
BA_ "GenSigTimeoutTime_CADM2" SG_ 526 LongAcceleration_C2 0;
BA_ "GenSigTimeoutTime_EPS" SG_ 526 LongAcceleration_C2 0;
BA_ "GenSigTimeoutTime_ORC" SG_ 526 LongAcceleration_C2 0;
BA_ "GenSigTimeoutTime_PAM" SG_ 526 LongAcceleration_C2 0;
BA_ "GenSigTimeoutTime_SGW" SG_ 526 LongAcceleration_C2 0;
BA_ "GenSigTimeoutTime_TRSKM" SG_ 526 LongAcceleration_C2 0;
BA_ "GenSigStartValue" SG_ 526 Longitude_RMSE_C2 255;
BA_ "GenSigTimeoutTime_BCM" SG_ 526 Longitude_RMSE_C2 0;
BA_ "GenSigTimeoutTime_BSM2" SG_ 526 Longitude_RMSE_C2 0;
BA_ "GenSigTimeoutTime_CADM2" SG_ 526 Longitude_RMSE_C2 0;
BA_ "GenSigTimeoutTime_EPS" SG_ 526 Longitude_RMSE_C2 0;
BA_ "GenSigTimeoutTime_ORC" SG_ 526 Longitude_RMSE_C2 0;
BA_ "GenSigTimeoutTime_PAM" SG_ 526 Longitude_RMSE_C2 0;
BA_ "GenSigTimeoutTime_SGW" SG_ 526 Longitude_RMSE_C2 0;
BA_ "GenSigTimeoutTime_TRSKM" SG_ 526 Longitude_RMSE_C2 0;
BA_ "GenSigTimeoutTime_BCM" SG_ 526 MessageCounter_GLOB_NAV_C2 0;
BA_ "GenSigTimeoutTime_BSM2" SG_ 526 MessageCounter_GLOB_NAV_C2 0;
BA_ "GenSigTimeoutTime_CADM2" SG_ 526 MessageCounter_GLOB_NAV_C2 0;
BA_ "GenSigTimeoutTime_EPS" SG_ 526 MessageCounter_GLOB_NAV_C2 0;
BA_ "GenSigTimeoutTime_ORC" SG_ 526 MessageCounter_GLOB_NAV_C2 0;
BA_ "GenSigTimeoutTime_PAM" SG_ 526 MessageCounter_GLOB_NAV_C2 0;
BA_ "GenSigTimeoutTime_SGW" SG_ 526 MessageCounter_GLOB_NAV_C2 0;
BA_ "GenSigTimeoutTime_TRSKM" SG_ 526 MessageCounter_GLOB_NAV_C2 0;
BA_ "GenSigStartValue" SG_ 526 Pitch_RMSE_C2 255;
BA_ "GenSigTimeoutTime_BCM" SG_ 526 Pitch_RMSE_C2 0;
BA_ "GenSigTimeoutTime_BSM2" SG_ 526 Pitch_RMSE_C2 0;
BA_ "GenSigTimeoutTime_CADM2" SG_ 526 Pitch_RMSE_C2 0;
BA_ "GenSigTimeoutTime_EPS" SG_ 526 Pitch_RMSE_C2 0;
BA_ "GenSigTimeoutTime_ORC" SG_ 526 Pitch_RMSE_C2 0;
BA_ "GenSigTimeoutTime_PAM" SG_ 526 Pitch_RMSE_C2 0;
BA_ "GenSigTimeoutTime_SGW" SG_ 526 Pitch_RMSE_C2 0;
BA_ "GenSigTimeoutTime_TRSKM" SG_ 526 Pitch_RMSE_C2 0;
BA_ "GenSigStartValue" SG_ 526 PitchRate_C2 4095;
BA_ "GenSigTimeoutTime_BCM" SG_ 526 PitchRate_C2 0;
BA_ "GenSigTimeoutTime_BSM2" SG_ 526 PitchRate_C2 0;
BA_ "GenSigTimeoutTime_CADM2" SG_ 526 PitchRate_C2 0;
BA_ "GenSigTimeoutTime_EPS" SG_ 526 PitchRate_C2 0;
BA_ "GenSigTimeoutTime_ORC" SG_ 526 PitchRate_C2 0;
BA_ "GenSigTimeoutTime_PAM" SG_ 526 PitchRate_C2 0;
BA_ "GenSigTimeoutTime_SGW" SG_ 526 PitchRate_C2 0;
BA_ "GenSigTimeoutTime_TRSKM" SG_ 526 PitchRate_C2 0;
BA_ "GenSigStartValue" SG_ 526 Roll_RMSE_C2 255;
BA_ "GenSigTimeoutTime_BCM" SG_ 526 Roll_RMSE_C2 0;
BA_ "GenSigTimeoutTime_BSM2" SG_ 526 Roll_RMSE_C2 0;
BA_ "GenSigTimeoutTime_CADM2" SG_ 526 Roll_RMSE_C2 0;
BA_ "GenSigTimeoutTime_EPS" SG_ 526 Roll_RMSE_C2 0;
BA_ "GenSigTimeoutTime_ORC" SG_ 526 Roll_RMSE_C2 0;
BA_ "GenSigTimeoutTime_PAM" SG_ 526 Roll_RMSE_C2 0;
BA_ "GenSigTimeoutTime_SGW" SG_ 526 Roll_RMSE_C2 0;
BA_ "GenSigTimeoutTime_TRSKM" SG_ 526 Roll_RMSE_C2 0;
BA_ "GenSigStartValue" SG_ 526 RollRate_C2 4095;
BA_ "GenSigTimeoutTime_BCM" SG_ 526 RollRate_C2 0;
BA_ "GenSigTimeoutTime_BSM2" SG_ 526 RollRate_C2 0;
BA_ "GenSigTimeoutTime_CADM2" SG_ 526 RollRate_C2 0;
BA_ "GenSigTimeoutTime_EPS" SG_ 526 RollRate_C2 0;
BA_ "GenSigTimeoutTime_ORC" SG_ 526 RollRate_C2 0;
BA_ "GenSigTimeoutTime_PAM" SG_ 526 RollRate_C2 0;
BA_ "GenSigTimeoutTime_SGW" SG_ 526 RollRate_C2 0;
BA_ "GenSigTimeoutTime_TRSKM" SG_ 526 RollRate_C2 0;
BA_ "GenSigStartValue" SG_ 526 VerticalAcceleration_C2 4095;
BA_ "GenSigTimeoutTime_BCM" SG_ 526 VerticalAcceleration_C2 0;
BA_ "GenSigTimeoutTime_BSM2" SG_ 526 VerticalAcceleration_C2 0;
BA_ "GenSigTimeoutTime_CADM2" SG_ 526 VerticalAcceleration_C2 0;
BA_ "GenSigTimeoutTime_EPS" SG_ 526 VerticalAcceleration_C2 0;
BA_ "GenSigTimeoutTime_ORC" SG_ 526 VerticalAcceleration_C2 0;
BA_ "GenSigTimeoutTime_PAM" SG_ 526 VerticalAcceleration_C2 0;
BA_ "GenSigTimeoutTime_SGW" SG_ 526 VerticalAcceleration_C2 0;
BA_ "GenSigTimeoutTime_TRSKM" SG_ 526 VerticalAcceleration_C2 0;
BA_ "GenSigStartValue" SG_ 526 YawRate_C2 4095;
BA_ "GenSigTimeoutTime_BCM" SG_ 526 YawRate_C2 0;
BA_ "GenSigTimeoutTime_BSM2" SG_ 526 YawRate_C2 0;
BA_ "GenSigTimeoutTime_CADM2" SG_ 526 YawRate_C2 0;
BA_ "GenSigTimeoutTime_EPS" SG_ 526 YawRate_C2 0;
BA_ "GenSigTimeoutTime_ORC" SG_ 526 YawRate_C2 0;
BA_ "GenSigTimeoutTime_PAM" SG_ 526 YawRate_C2 0;
BA_ "GenSigTimeoutTime_SGW" SG_ 526 YawRate_C2 0;
BA_ "GenSigTimeoutTime_TRSKM" SG_ 526 YawRate_C2 0;
BA_ "GenSigStartValue" SG_ 526 YawRate_RMSE_C2 255;
BA_ "GenSigTimeoutTime_BCM" SG_ 526 YawRate_RMSE_C2 0;
BA_ "GenSigTimeoutTime_BSM2" SG_ 526 YawRate_RMSE_C2 0;
BA_ "GenSigTimeoutTime_CADM2" SG_ 526 YawRate_RMSE_C2 0;
BA_ "GenSigTimeoutTime_EPS" SG_ 526 YawRate_RMSE_C2 0;
BA_ "GenSigTimeoutTime_ORC" SG_ 526 YawRate_RMSE_C2 0;
BA_ "GenSigTimeoutTime_PAM" SG_ 526 YawRate_RMSE_C2 0;
BA_ "GenSigTimeoutTime_SGW" SG_ 526 YawRate_RMSE_C2 0;
BA_ "GenSigTimeoutTime_TRSKM" SG_ 526 YawRate_RMSE_C2 0;
BA_ "GenSigTimeoutTime_BCM" SG_ 266 HVBatContactorSts 0;
BA_ "GenSigTimeoutTime_BSM2" SG_ 266 HVBatContactorSts 0;
BA_ "GenSigTimeoutTime_CADM2" SG_ 266 HVBatContactorSts 0;
BA_ "GenSigTimeoutTime_CVADAS" SG_ 266 HVBatContactorSts 0;
BA_ "GenSigTimeoutTime_EPS" SG_ 266 HVBatContactorSts 0;
BA_ "GenSigTimeoutTime_PAM" SG_ 266 HVBatContactorSts 0;
BA_ "GenSigTimeoutTime_SGW" SG_ 266 HVBatContactorSts 0;
BA_ "GenSigTimeoutTime_TRSKM" SG_ 266 HVBatContactorSts 0;
BA_ "GenSigTimeoutTime_BCM" SG_ 1049 HVBatterySOC_Display 0;
BA_ "GenSigTimeoutTime_BSM2" SG_ 1049 HVBatterySOC_Display 0;
BA_ "GenSigTimeoutTime_CADM2" SG_ 1049 HVBatterySOC_Display 0;
BA_ "GenSigTimeoutTime_CVADAS" SG_ 1049 HVBatterySOC_Display 0;
BA_ "GenSigTimeoutTime_EPS" SG_ 1049 HVBatterySOC_Display 0;
BA_ "GenSigTimeoutTime_PAM" SG_ 1049 HVBatterySOC_Display 0;
BA_ "GenSigTimeoutTime_SGW" SG_ 1049 HVBatterySOC_Display 0;
BA_ "GenSigTimeoutTime_TRSKM" SG_ 1049 HVBatterySOC_Display 0;
BA_ "GenSigTimeoutTime_BCM" SG_ 276 PropulsionSystemActive 0;
BA_ "GenSigTimeoutTime_BSM2" SG_ 276 PropulsionSystemActive 0;
BA_ "GenSigTimeoutTime_CADM2" SG_ 276 PropulsionSystemActive 0;
BA_ "GenSigTimeoutTime_CVADAS" SG_ 276 PropulsionSystemActive 0;
BA_ "GenSigTimeoutTime_ORC" SG_ 276 PropulsionSystemActive 0;
BA_ "GenSigTimeoutTime_PAM" SG_ 276 PropulsionSystemActive 0;
BA_ "GenSigTimeoutTime_SGW" SG_ 276 PropulsionSystemActive 0;
BA_ "GenSigTimeoutTime_TRSKM" SG_ 276 PropulsionSystemActive 0;
BA_ "GenSigTimeoutTime_BCM" SG_ 269 BSGActualTorque 0;
BA_ "GenSigTimeoutTime_BSM2" SG_ 269 BSGActualTorque 0;
BA_ "GenSigTimeoutTime_CADM2" SG_ 269 BSGActualTorque 0;
BA_ "GenSigTimeoutTime_CVADAS" SG_ 269 BSGActualTorque 0;
BA_ "GenSigTimeoutTime_EPS" SG_ 269 BSGActualTorque 0;
BA_ "GenSigTimeoutTime_PAM" SG_ 269 BSGActualTorque 0;
BA_ "GenSigTimeoutTime_SGW" SG_ 269 BSGActualTorque 0;
BA_ "GenSigTimeoutTime_TRSKM" SG_ 269 BSGActualTorque 0;
BA_ "GenSigTimeoutTime_BCM" SG_ 269 ReqTorqueOverLayActive 0;
BA_ "GenSigTimeoutTime_BSM2" SG_ 269 ReqTorqueOverLayActive 0;
BA_ "GenSigTimeoutTime_CADM2" SG_ 269 ReqTorqueOverLayActive 0;
BA_ "GenSigTimeoutTime_CVADAS" SG_ 269 ReqTorqueOverLayActive 0;
BA_ "GenSigTimeoutTime_EPS" SG_ 269 ReqTorqueOverLayActive 0;
BA_ "GenSigTimeoutTime_PAM" SG_ 269 ReqTorqueOverLayActive 0;
BA_ "GenSigTimeoutTime_SGW" SG_ 269 ReqTorqueOverLayActive 0;
BA_ "GenSigTimeoutTime_TRSKM" SG_ 269 ReqTorqueOverLayActive 0;
BA_ "GenSigTimeoutTime_BCM" SG_ 752 CurrBattFailStatus 0;
BA_ "GenSigTimeoutTime_BSM2" SG_ 752 CurrBattFailStatus 0;
BA_ "GenSigTimeoutTime_CADM2" SG_ 752 CurrBattFailStatus 0;
BA_ "GenSigTimeoutTime_CVADAS" SG_ 752 CurrBattFailStatus 0;
BA_ "GenSigTimeoutTime_EPS" SG_ 752 CurrBattFailStatus 0;
BA_ "GenSigTimeoutTime_ORC" SG_ 752 CurrBattFailStatus 0;
BA_ "GenSigTimeoutTime_PAM" SG_ 752 CurrBattFailStatus 0;
BA_ "GenSigTimeoutTime_SGW" SG_ 752 CurrBattFailStatus 0;
BA_ "GenSigTimeoutTime_TRSKM" SG_ 752 CurrBattFailStatus 0;
BA_ "GenSigTimeoutTime_BCM" SG_ 752 IBS3_Error_Internal 0;
BA_ "GenSigTimeoutTime_BSM2" SG_ 752 IBS3_Error_Internal 0;
BA_ "GenSigTimeoutTime_CADM2" SG_ 752 IBS3_Error_Internal 0;
BA_ "GenSigTimeoutTime_CVADAS" SG_ 752 IBS3_Error_Internal 0;
BA_ "GenSigTimeoutTime_EPS" SG_ 752 IBS3_Error_Internal 0;
BA_ "GenSigTimeoutTime_ORC" SG_ 752 IBS3_Error_Internal 0;
BA_ "GenSigTimeoutTime_PAM" SG_ 752 IBS3_Error_Internal 0;
BA_ "GenSigTimeoutTime_SGW" SG_ 752 IBS3_Error_Internal 0;
BA_ "GenSigTimeoutTime_TRSKM" SG_ 752 IBS3_Error_Internal 0;
BA_ "GenSigStartValue" SG_ 752 IBS3_Vbatt 511;
BA_ "GenSigTimeoutTime_BCM" SG_ 752 IBS3_Vbatt 0;
BA_ "GenSigTimeoutTime_BSM2" SG_ 752 IBS3_Vbatt 0;
BA_ "GenSigTimeoutTime_CADM2" SG_ 752 IBS3_Vbatt 0;
BA_ "GenSigTimeoutTime_CVADAS" SG_ 752 IBS3_Vbatt 0;
BA_ "GenSigTimeoutTime_EPS" SG_ 752 IBS3_Vbatt 0;
BA_ "GenSigTimeoutTime_PAM" SG_ 752 IBS3_Vbatt 0;
BA_ "GenSigTimeoutTime_SGW" SG_ 752 IBS3_Vbatt 0;
BA_ "GenSigTimeoutTime_TRSKM" SG_ 752 IBS3_Vbatt 0;
BA_ "GenSigTimeoutTime_BCM" SG_ 752 RsErrIBS3 0;
BA_ "GenSigTimeoutTime_BSM2" SG_ 752 RsErrIBS3 0;
BA_ "GenSigTimeoutTime_CADM2" SG_ 752 RsErrIBS3 0;
BA_ "GenSigTimeoutTime_CVADAS" SG_ 752 RsErrIBS3 0;
BA_ "GenSigTimeoutTime_EPS" SG_ 752 RsErrIBS3 0;
BA_ "GenSigTimeoutTime_ORC" SG_ 752 RsErrIBS3 0;
BA_ "GenSigTimeoutTime_PAM" SG_ 752 RsErrIBS3 0;
BA_ "GenSigTimeoutTime_SGW" SG_ 752 RsErrIBS3 0;
BA_ "GenSigTimeoutTime_TRSKM" SG_ 752 RsErrIBS3 0;
BA_ "GenSigTimeoutTime_BCM" SG_ 752 VoltBattFailStatus 0;
BA_ "GenSigTimeoutTime_BSM2" SG_ 752 VoltBattFailStatus 0;
BA_ "GenSigTimeoutTime_CADM2" SG_ 752 VoltBattFailStatus 0;
BA_ "GenSigTimeoutTime_CVADAS" SG_ 752 VoltBattFailStatus 0;
BA_ "GenSigTimeoutTime_EPS" SG_ 752 VoltBattFailStatus 0;
BA_ "GenSigTimeoutTime_ORC" SG_ 752 VoltBattFailStatus 0;
BA_ "GenSigTimeoutTime_PAM" SG_ 752 VoltBattFailStatus 0;
BA_ "GenSigTimeoutTime_SGW" SG_ 752 VoltBattFailStatus 0;
BA_ "GenSigTimeoutTime_TRSKM" SG_ 752 VoltBattFailStatus 0;
BA_ "GenSigTimeoutTime_BCM" SG_ 754 CurrBattFailStatus_2 0;
BA_ "GenSigTimeoutTime_BSM2" SG_ 754 CurrBattFailStatus_2 0;
BA_ "GenSigTimeoutTime_CADM2" SG_ 754 CurrBattFailStatus_2 0;
BA_ "GenSigTimeoutTime_CVADAS" SG_ 754 CurrBattFailStatus_2 0;
BA_ "GenSigTimeoutTime_EPS" SG_ 754 CurrBattFailStatus_2 0;
BA_ "GenSigTimeoutTime_ORC" SG_ 754 CurrBattFailStatus_2 0;
BA_ "GenSigTimeoutTime_PAM" SG_ 754 CurrBattFailStatus_2 0;
BA_ "GenSigTimeoutTime_SGW" SG_ 754 CurrBattFailStatus_2 0;
BA_ "GenSigTimeoutTime_TRSKM" SG_ 754 CurrBattFailStatus_2 0;
BA_ "GenSigTimeoutTime_BCM" SG_ 754 IBS3_Error_Internal_2 0;
BA_ "GenSigTimeoutTime_BSM2" SG_ 754 IBS3_Error_Internal_2 0;
BA_ "GenSigTimeoutTime_CADM2" SG_ 754 IBS3_Error_Internal_2 0;
BA_ "GenSigTimeoutTime_CVADAS" SG_ 754 IBS3_Error_Internal_2 0;
BA_ "GenSigTimeoutTime_EPS" SG_ 754 IBS3_Error_Internal_2 0;
BA_ "GenSigTimeoutTime_ORC" SG_ 754 IBS3_Error_Internal_2 0;
BA_ "GenSigTimeoutTime_PAM" SG_ 754 IBS3_Error_Internal_2 0;
BA_ "GenSigTimeoutTime_SGW" SG_ 754 IBS3_Error_Internal_2 0;
BA_ "GenSigTimeoutTime_TRSKM" SG_ 754 IBS3_Error_Internal_2 0;
BA_ "GenSigStartValue" SG_ 754 IBS3_Ibatt_2 65535;
BA_ "GenSigTimeoutTime_BCM" SG_ 754 IBS3_Ibatt_2 0;
BA_ "GenSigTimeoutTime_BSM2" SG_ 754 IBS3_Ibatt_2 0;
BA_ "GenSigTimeoutTime_CADM2" SG_ 754 IBS3_Ibatt_2 0;
BA_ "GenSigTimeoutTime_CVADAS" SG_ 754 IBS3_Ibatt_2 0;
BA_ "GenSigTimeoutTime_EPS" SG_ 754 IBS3_Ibatt_2 0;
BA_ "GenSigTimeoutTime_ORC" SG_ 754 IBS3_Ibatt_2 0;
BA_ "GenSigTimeoutTime_PAM" SG_ 754 IBS3_Ibatt_2 0;
BA_ "GenSigTimeoutTime_SGW" SG_ 754 IBS3_Ibatt_2 0;
BA_ "GenSigTimeoutTime_TRSKM" SG_ 754 IBS3_Ibatt_2 0;
BA_ "GenSigStartValue" SG_ 754 IBS3_Vbatt_2 511;
BA_ "GenSigTimeoutTime_BCM" SG_ 754 IBS3_Vbatt_2 0;
BA_ "GenSigTimeoutTime_BSM2" SG_ 754 IBS3_Vbatt_2 0;
BA_ "GenSigTimeoutTime_CADM2" SG_ 754 IBS3_Vbatt_2 0;
BA_ "GenSigTimeoutTime_CVADAS" SG_ 754 IBS3_Vbatt_2 0;
BA_ "GenSigTimeoutTime_EPS" SG_ 754 IBS3_Vbatt_2 0;
BA_ "GenSigTimeoutTime_ORC" SG_ 754 IBS3_Vbatt_2 0;
BA_ "GenSigTimeoutTime_PAM" SG_ 754 IBS3_Vbatt_2 0;
BA_ "GenSigTimeoutTime_SGW" SG_ 754 IBS3_Vbatt_2 0;
BA_ "GenSigTimeoutTime_TRSKM" SG_ 754 IBS3_Vbatt_2 0;
BA_ "GenSigTimeoutTime_BCM" SG_ 754 RsErrIBS3_2 0;
BA_ "GenSigTimeoutTime_BSM2" SG_ 754 RsErrIBS3_2 0;
BA_ "GenSigTimeoutTime_CADM2" SG_ 754 RsErrIBS3_2 0;
BA_ "GenSigTimeoutTime_CVADAS" SG_ 754 RsErrIBS3_2 0;
BA_ "GenSigTimeoutTime_EPS" SG_ 754 RsErrIBS3_2 0;
BA_ "GenSigTimeoutTime_ORC" SG_ 754 RsErrIBS3_2 0;
BA_ "GenSigTimeoutTime_PAM" SG_ 754 RsErrIBS3_2 0;
BA_ "GenSigTimeoutTime_SGW" SG_ 754 RsErrIBS3_2 0;
BA_ "GenSigTimeoutTime_TRSKM" SG_ 754 RsErrIBS3_2 0;
BA_ "GenSigTimeoutTime_BCM" SG_ 754 VoltBattFailStatus_2 0;
BA_ "GenSigTimeoutTime_BSM2" SG_ 754 VoltBattFailStatus_2 0;
BA_ "GenSigTimeoutTime_CADM2" SG_ 754 VoltBattFailStatus_2 0;
BA_ "GenSigTimeoutTime_CVADAS" SG_ 754 VoltBattFailStatus_2 0;
BA_ "GenSigTimeoutTime_EPS" SG_ 754 VoltBattFailStatus_2 0;
BA_ "GenSigTimeoutTime_ORC" SG_ 754 VoltBattFailStatus_2 0;
BA_ "GenSigTimeoutTime_PAM" SG_ 754 VoltBattFailStatus_2 0;
BA_ "GenSigTimeoutTime_SGW" SG_ 754 VoltBattFailStatus_2 0;
BA_ "GenSigTimeoutTime_TRSKM" SG_ 754 VoltBattFailStatus_2 0;
BA_ "GenSigTimeoutTime_BCM" SG_ 1955 IBS3_CRC_IBS_1 0;
BA_ "GenSigTimeoutTime_BSM2" SG_ 1955 IBS3_CRC_IBS_1 0;
BA_ "GenSigTimeoutTime_CVADAS" SG_ 1955 IBS3_CRC_IBS_1 0;
BA_ "GenSigTimeoutTime_EPS" SG_ 1955 IBS3_CRC_IBS_1 0;
BA_ "GenSigTimeoutTime_ORC" SG_ 1955 IBS3_CRC_IBS_1 0;
BA_ "GenSigTimeoutTime_PAM" SG_ 1955 IBS3_CRC_IBS_1 0;
BA_ "GenSigTimeoutTime_SGW" SG_ 1955 IBS3_CRC_IBS_1 0;
BA_ "GenSigTimeoutTime_TRSKM" SG_ 1955 IBS3_CRC_IBS_1 0;
BA_ "GenSigTimeoutTime_BCM" SG_ 1955 IBS3_CRC_IBS_2 0;
BA_ "GenSigTimeoutTime_BSM2" SG_ 1955 IBS3_CRC_IBS_2 0;
BA_ "GenSigTimeoutTime_CVADAS" SG_ 1955 IBS3_CRC_IBS_2 0;
BA_ "GenSigTimeoutTime_EPS" SG_ 1955 IBS3_CRC_IBS_2 0;
BA_ "GenSigTimeoutTime_ORC" SG_ 1955 IBS3_CRC_IBS_2 0;
BA_ "GenSigTimeoutTime_PAM" SG_ 1955 IBS3_CRC_IBS_2 0;
BA_ "GenSigTimeoutTime_SGW" SG_ 1955 IBS3_CRC_IBS_2 0;
BA_ "GenSigTimeoutTime_TRSKM" SG_ 1955 IBS3_CRC_IBS_2 0;
BA_ "GenSigTimeoutTime_BCM" SG_ 1955 IBS3_FLAG_DISCONNECT_ADAS 0;
BA_ "GenSigTimeoutTime_BSM2" SG_ 1955 IBS3_FLAG_DISCONNECT_ADAS 0;
BA_ "GenSigTimeoutTime_CADM2" SG_ 1955 IBS3_FLAG_DISCONNECT_ADAS 0;
BA_ "GenSigTimeoutTime_CVADAS" SG_ 1955 IBS3_FLAG_DISCONNECT_ADAS 0;
BA_ "GenSigTimeoutTime_EPS" SG_ 1955 IBS3_FLAG_DISCONNECT_ADAS 0;
BA_ "GenSigTimeoutTime_ORC" SG_ 1955 IBS3_FLAG_DISCONNECT_ADAS 0;
BA_ "GenSigTimeoutTime_PAM" SG_ 1955 IBS3_FLAG_DISCONNECT_ADAS 0;
BA_ "GenSigTimeoutTime_SGW" SG_ 1955 IBS3_FLAG_DISCONNECT_ADAS 0;
BA_ "GenSigTimeoutTime_TRSKM" SG_ 1955 IBS3_FLAG_DISCONNECT_ADAS 0;
BA_ "GenSigTimeoutTime_BCM" SG_ 1955 IBS3_FLAG_DISCONNECT_ADAS_2 0;
BA_ "GenSigTimeoutTime_BSM2" SG_ 1955 IBS3_FLAG_DISCONNECT_ADAS_2 0;
BA_ "GenSigTimeoutTime_CADM2" SG_ 1955 IBS3_FLAG_DISCONNECT_ADAS_2 0;
BA_ "GenSigTimeoutTime_CVADAS" SG_ 1955 IBS3_FLAG_DISCONNECT_ADAS_2 0;
BA_ "GenSigTimeoutTime_EPS" SG_ 1955 IBS3_FLAG_DISCONNECT_ADAS_2 0;
BA_ "GenSigTimeoutTime_ORC" SG_ 1955 IBS3_FLAG_DISCONNECT_ADAS_2 0;
BA_ "GenSigTimeoutTime_PAM" SG_ 1955 IBS3_FLAG_DISCONNECT_ADAS_2 0;
BA_ "GenSigTimeoutTime_SGW" SG_ 1955 IBS3_FLAG_DISCONNECT_ADAS_2 0;
BA_ "GenSigTimeoutTime_TRSKM" SG_ 1955 IBS3_FLAG_DISCONNECT_ADAS_2 0;
BA_ "GenSigTimeoutTime_BCM" SG_ 1955 IBS3_IBS_ADAS_OK 0;
BA_ "GenSigTimeoutTime_BSM2" SG_ 1955 IBS3_IBS_ADAS_OK 0;
BA_ "GenSigTimeoutTime_CVADAS" SG_ 1955 IBS3_IBS_ADAS_OK 0;
BA_ "GenSigTimeoutTime_EPS" SG_ 1955 IBS3_IBS_ADAS_OK 0;
BA_ "GenSigTimeoutTime_ORC" SG_ 1955 IBS3_IBS_ADAS_OK 0;
BA_ "GenSigTimeoutTime_PAM" SG_ 1955 IBS3_IBS_ADAS_OK 0;
BA_ "GenSigTimeoutTime_SGW" SG_ 1955 IBS3_IBS_ADAS_OK 0;
BA_ "GenSigTimeoutTime_TRSKM" SG_ 1955 IBS3_IBS_ADAS_OK 0;
BA_ "GenSigTimeoutTime_BCM" SG_ 1955 IBS3_IBS_ADAS_OK_2 0;
BA_ "GenSigTimeoutTime_BSM2" SG_ 1955 IBS3_IBS_ADAS_OK_2 0;
BA_ "GenSigTimeoutTime_CVADAS" SG_ 1955 IBS3_IBS_ADAS_OK_2 0;
BA_ "GenSigTimeoutTime_EPS" SG_ 1955 IBS3_IBS_ADAS_OK_2 0;
BA_ "GenSigTimeoutTime_ORC" SG_ 1955 IBS3_IBS_ADAS_OK_2 0;
BA_ "GenSigTimeoutTime_PAM" SG_ 1955 IBS3_IBS_ADAS_OK_2 0;
BA_ "GenSigTimeoutTime_SGW" SG_ 1955 IBS3_IBS_ADAS_OK_2 0;
BA_ "GenSigTimeoutTime_TRSKM" SG_ 1955 IBS3_IBS_ADAS_OK_2 0;
BA_ "GenSigTimeoutTime_BCM" SG_ 1955 IBS3_MC_IBS_1 0;
BA_ "GenSigTimeoutTime_BSM2" SG_ 1955 IBS3_MC_IBS_1 0;
BA_ "GenSigTimeoutTime_CVADAS" SG_ 1955 IBS3_MC_IBS_1 0;
BA_ "GenSigTimeoutTime_EPS" SG_ 1955 IBS3_MC_IBS_1 0;
BA_ "GenSigTimeoutTime_ORC" SG_ 1955 IBS3_MC_IBS_1 0;
BA_ "GenSigTimeoutTime_PAM" SG_ 1955 IBS3_MC_IBS_1 0;
BA_ "GenSigTimeoutTime_SGW" SG_ 1955 IBS3_MC_IBS_1 0;
BA_ "GenSigTimeoutTime_TRSKM" SG_ 1955 IBS3_MC_IBS_1 0;
BA_ "GenSigTimeoutTime_BCM" SG_ 1955 IBS3_MC_IBS_2 0;
BA_ "GenSigTimeoutTime_BSM2" SG_ 1955 IBS3_MC_IBS_2 0;
BA_ "GenSigTimeoutTime_CVADAS" SG_ 1955 IBS3_MC_IBS_2 0;
BA_ "GenSigTimeoutTime_EPS" SG_ 1955 IBS3_MC_IBS_2 0;
BA_ "GenSigTimeoutTime_ORC" SG_ 1955 IBS3_MC_IBS_2 0;
BA_ "GenSigTimeoutTime_PAM" SG_ 1955 IBS3_MC_IBS_2 0;
BA_ "GenSigTimeoutTime_SGW" SG_ 1955 IBS3_MC_IBS_2 0;
BA_ "GenSigTimeoutTime_TRSKM" SG_ 1955 IBS3_MC_IBS_2 0;
BA_ "GenSigStartValue" SG_ 1955 IBS3_SOC 127;
BA_ "GenSigTimeoutTime_BCM" SG_ 1955 IBS3_SOC 0;
BA_ "GenSigTimeoutTime_BSM2" SG_ 1955 IBS3_SOC 0;
BA_ "GenSigTimeoutTime_CADM2" SG_ 1955 IBS3_SOC 0;
BA_ "GenSigTimeoutTime_CVADAS" SG_ 1955 IBS3_SOC 0;
BA_ "GenSigTimeoutTime_EPS" SG_ 1955 IBS3_SOC 0;
BA_ "GenSigTimeoutTime_PAM" SG_ 1955 IBS3_SOC 0;
BA_ "GenSigTimeoutTime_SGW" SG_ 1955 IBS3_SOC 0;
BA_ "GenSigTimeoutTime_TRSKM" SG_ 1955 IBS3_SOC 0;
BA_ "GenSigTimeoutTime_BCM" SG_ 1955 IBS3_SOC_Accuracy 0;
BA_ "GenSigTimeoutTime_BSM2" SG_ 1955 IBS3_SOC_Accuracy 0;
BA_ "GenSigTimeoutTime_CADM2" SG_ 1955 IBS3_SOC_Accuracy 0;
BA_ "GenSigTimeoutTime_CVADAS" SG_ 1955 IBS3_SOC_Accuracy 0;
BA_ "GenSigTimeoutTime_EPS" SG_ 1955 IBS3_SOC_Accuracy 0;
BA_ "GenSigTimeoutTime_ORC" SG_ 1955 IBS3_SOC_Accuracy 0;
BA_ "GenSigTimeoutTime_PAM" SG_ 1955 IBS3_SOC_Accuracy 0;
BA_ "GenSigTimeoutTime_SGW" SG_ 1955 IBS3_SOC_Accuracy 0;
BA_ "GenSigTimeoutTime_TRSKM" SG_ 1955 IBS3_SOC_Accuracy 0;
BA_ "GenSigTimeoutTime_BCM" SG_ 1957 IBS3_FLAG_DISCONNECT_2 0;
BA_ "GenSigTimeoutTime_BSM2" SG_ 1957 IBS3_FLAG_DISCONNECT_2 0;
BA_ "GenSigTimeoutTime_CADM2" SG_ 1957 IBS3_FLAG_DISCONNECT_2 0;
BA_ "GenSigTimeoutTime_CVADAS" SG_ 1957 IBS3_FLAG_DISCONNECT_2 0;
BA_ "GenSigTimeoutTime_EPS" SG_ 1957 IBS3_FLAG_DISCONNECT_2 0;
BA_ "GenSigTimeoutTime_ORC" SG_ 1957 IBS3_FLAG_DISCONNECT_2 0;
BA_ "GenSigTimeoutTime_PAM" SG_ 1957 IBS3_FLAG_DISCONNECT_2 0;
BA_ "GenSigTimeoutTime_SGW" SG_ 1957 IBS3_FLAG_DISCONNECT_2 0;
BA_ "GenSigTimeoutTime_TRSKM" SG_ 1957 IBS3_FLAG_DISCONNECT_2 0;
BA_ "GenSigStartValue" SG_ 1957 IBS3_Q_Received_2 65535;
BA_ "GenSigTimeoutTime_BCM" SG_ 1957 IBS3_Q_Received_2 0;
BA_ "GenSigTimeoutTime_BSM2" SG_ 1957 IBS3_Q_Received_2 0;
BA_ "GenSigTimeoutTime_CADM2" SG_ 1957 IBS3_Q_Received_2 0;
BA_ "GenSigTimeoutTime_CVADAS" SG_ 1957 IBS3_Q_Received_2 0;
BA_ "GenSigTimeoutTime_EPS" SG_ 1957 IBS3_Q_Received_2 0;
BA_ "GenSigTimeoutTime_ORC" SG_ 1957 IBS3_Q_Received_2 0;
BA_ "GenSigTimeoutTime_PAM" SG_ 1957 IBS3_Q_Received_2 0;
BA_ "GenSigTimeoutTime_SGW" SG_ 1957 IBS3_Q_Received_2 0;
BA_ "GenSigTimeoutTime_TRSKM" SG_ 1957 IBS3_Q_Received_2 0;
BA_ "GenSigStartValue" SG_ 1957 IBS3_Q_Released_2 65535;
BA_ "GenSigTimeoutTime_BCM" SG_ 1957 IBS3_Q_Released_2 0;
BA_ "GenSigTimeoutTime_BSM2" SG_ 1957 IBS3_Q_Released_2 0;
BA_ "GenSigTimeoutTime_CADM2" SG_ 1957 IBS3_Q_Released_2 0;
BA_ "GenSigTimeoutTime_CVADAS" SG_ 1957 IBS3_Q_Released_2 0;
BA_ "GenSigTimeoutTime_EPS" SG_ 1957 IBS3_Q_Released_2 0;
BA_ "GenSigTimeoutTime_ORC" SG_ 1957 IBS3_Q_Released_2 0;
BA_ "GenSigTimeoutTime_PAM" SG_ 1957 IBS3_Q_Released_2 0;
BA_ "GenSigTimeoutTime_SGW" SG_ 1957 IBS3_Q_Released_2 0;
BA_ "GenSigTimeoutTime_TRSKM" SG_ 1957 IBS3_Q_Released_2 0;
BA_ "GenSigStartValue" SG_ 1957 IBS3_R_Batt_2 255;
BA_ "GenSigTimeoutTime_BCM" SG_ 1957 IBS3_R_Batt_2 0;
BA_ "GenSigTimeoutTime_BSM2" SG_ 1957 IBS3_R_Batt_2 0;
BA_ "GenSigTimeoutTime_CADM2" SG_ 1957 IBS3_R_Batt_2 0;
BA_ "GenSigTimeoutTime_CVADAS" SG_ 1957 IBS3_R_Batt_2 0;
BA_ "GenSigTimeoutTime_EPS" SG_ 1957 IBS3_R_Batt_2 0;
BA_ "GenSigTimeoutTime_ORC" SG_ 1957 IBS3_R_Batt_2 0;
BA_ "GenSigTimeoutTime_PAM" SG_ 1957 IBS3_R_Batt_2 0;
BA_ "GenSigTimeoutTime_SGW" SG_ 1957 IBS3_R_Batt_2 0;
BA_ "GenSigTimeoutTime_TRSKM" SG_ 1957 IBS3_R_Batt_2 0;
BA_ "GenSigStartValue" SG_ 1957 IBS3_R_Batt_25_2 255;
BA_ "GenSigTimeoutTime_BCM" SG_ 1957 IBS3_R_Batt_25_2 0;
BA_ "GenSigTimeoutTime_BSM2" SG_ 1957 IBS3_R_Batt_25_2 0;
BA_ "GenSigTimeoutTime_CADM2" SG_ 1957 IBS3_R_Batt_25_2 0;
BA_ "GenSigTimeoutTime_CVADAS" SG_ 1957 IBS3_R_Batt_25_2 0;
BA_ "GenSigTimeoutTime_EPS" SG_ 1957 IBS3_R_Batt_25_2 0;
BA_ "GenSigTimeoutTime_ORC" SG_ 1957 IBS3_R_Batt_25_2 0;
BA_ "GenSigTimeoutTime_PAM" SG_ 1957 IBS3_R_Batt_25_2 0;
BA_ "GenSigTimeoutTime_SGW" SG_ 1957 IBS3_R_Batt_25_2 0;
BA_ "GenSigTimeoutTime_TRSKM" SG_ 1957 IBS3_R_Batt_25_2 0;
BA_ "GenSigStartValue" SG_ 1957 IBS3_SOC_2 127;
BA_ "GenSigTimeoutTime_BCM" SG_ 1957 IBS3_SOC_2 0;
BA_ "GenSigTimeoutTime_BSM2" SG_ 1957 IBS3_SOC_2 0;
BA_ "GenSigTimeoutTime_CADM2" SG_ 1957 IBS3_SOC_2 0;
BA_ "GenSigTimeoutTime_CVADAS" SG_ 1957 IBS3_SOC_2 0;
BA_ "GenSigTimeoutTime_EPS" SG_ 1957 IBS3_SOC_2 0;
BA_ "GenSigTimeoutTime_ORC" SG_ 1957 IBS3_SOC_2 0;
BA_ "GenSigTimeoutTime_PAM" SG_ 1957 IBS3_SOC_2 0;
BA_ "GenSigTimeoutTime_TRSKM" SG_ 1957 IBS3_SOC_2 0;
BA_ "GenSigTimeoutTime_BCM" SG_ 1957 IBS3_SOC_Accuracy_2 0;
BA_ "GenSigTimeoutTime_BSM2" SG_ 1957 IBS3_SOC_Accuracy_2 0;
BA_ "GenSigTimeoutTime_CADM2" SG_ 1957 IBS3_SOC_Accuracy_2 0;
BA_ "GenSigTimeoutTime_CVADAS" SG_ 1957 IBS3_SOC_Accuracy_2 0;
BA_ "GenSigTimeoutTime_EPS" SG_ 1957 IBS3_SOC_Accuracy_2 0;
BA_ "GenSigTimeoutTime_ORC" SG_ 1957 IBS3_SOC_Accuracy_2 0;
BA_ "GenSigTimeoutTime_PAM" SG_ 1957 IBS3_SOC_Accuracy_2 0;
BA_ "GenSigTimeoutTime_TRSKM" SG_ 1957 IBS3_SOC_Accuracy_2 0;
BA_ "GenSigStartValue" SG_ 1957 IBS3_SOF_Q_2 255;
BA_ "GenSigTimeoutTime_BCM" SG_ 1957 IBS3_SOF_Q_2 0;
BA_ "GenSigTimeoutTime_BSM2" SG_ 1957 IBS3_SOF_Q_2 0;
BA_ "GenSigTimeoutTime_CADM2" SG_ 1957 IBS3_SOF_Q_2 0;
BA_ "GenSigTimeoutTime_CVADAS" SG_ 1957 IBS3_SOF_Q_2 0;
BA_ "GenSigTimeoutTime_EPS" SG_ 1957 IBS3_SOF_Q_2 0;
BA_ "GenSigTimeoutTime_ORC" SG_ 1957 IBS3_SOF_Q_2 0;
BA_ "GenSigTimeoutTime_PAM" SG_ 1957 IBS3_SOF_Q_2 0;
BA_ "GenSigTimeoutTime_SGW" SG_ 1957 IBS3_SOF_Q_2 0;
BA_ "GenSigTimeoutTime_TRSKM" SG_ 1957 IBS3_SOF_Q_2 0;
BA_ "GenSigTimeoutTime_BCM" SG_ 1957 IBS3_SOF_Q_Accuracy_2 0;
BA_ "GenSigTimeoutTime_BSM2" SG_ 1957 IBS3_SOF_Q_Accuracy_2 0;
BA_ "GenSigTimeoutTime_CADM2" SG_ 1957 IBS3_SOF_Q_Accuracy_2 0;
BA_ "GenSigTimeoutTime_CVADAS" SG_ 1957 IBS3_SOF_Q_Accuracy_2 0;
BA_ "GenSigTimeoutTime_EPS" SG_ 1957 IBS3_SOF_Q_Accuracy_2 0;
BA_ "GenSigTimeoutTime_ORC" SG_ 1957 IBS3_SOF_Q_Accuracy_2 0;
BA_ "GenSigTimeoutTime_PAM" SG_ 1957 IBS3_SOF_Q_Accuracy_2 0;
BA_ "GenSigTimeoutTime_SGW" SG_ 1957 IBS3_SOF_Q_Accuracy_2 0;
BA_ "GenSigTimeoutTime_TRSKM" SG_ 1957 IBS3_SOF_Q_Accuracy_2 0;
BA_ "GenSigStartValue" SG_ 1957 IBS3_SOH_COR_2 127;
BA_ "GenSigTimeoutTime_BCM" SG_ 1957 IBS3_SOH_COR_2 0;
BA_ "GenSigTimeoutTime_BSM2" SG_ 1957 IBS3_SOH_COR_2 0;
BA_ "GenSigTimeoutTime_CADM2" SG_ 1957 IBS3_SOH_COR_2 0;
BA_ "GenSigTimeoutTime_CVADAS" SG_ 1957 IBS3_SOH_COR_2 0;
BA_ "GenSigTimeoutTime_EPS" SG_ 1957 IBS3_SOH_COR_2 0;
BA_ "GenSigTimeoutTime_ORC" SG_ 1957 IBS3_SOH_COR_2 0;
BA_ "GenSigTimeoutTime_PAM" SG_ 1957 IBS3_SOH_COR_2 0;
BA_ "GenSigTimeoutTime_SGW" SG_ 1957 IBS3_SOH_COR_2 0;
BA_ "GenSigTimeoutTime_TRSKM" SG_ 1957 IBS3_SOH_COR_2 0;
BA_ "GenSigTimeoutTime_BCM" SG_ 1957 IBS3_SOH_COR_Accuracy_2 0;
BA_ "GenSigTimeoutTime_BSM2" SG_ 1957 IBS3_SOH_COR_Accuracy_2 0;
BA_ "GenSigTimeoutTime_CADM2" SG_ 1957 IBS3_SOH_COR_Accuracy_2 0;
BA_ "GenSigTimeoutTime_CVADAS" SG_ 1957 IBS3_SOH_COR_Accuracy_2 0;
BA_ "GenSigTimeoutTime_EPS" SG_ 1957 IBS3_SOH_COR_Accuracy_2 0;
BA_ "GenSigTimeoutTime_ORC" SG_ 1957 IBS3_SOH_COR_Accuracy_2 0;
BA_ "GenSigTimeoutTime_PAM" SG_ 1957 IBS3_SOH_COR_Accuracy_2 0;
BA_ "GenSigTimeoutTime_SGW" SG_ 1957 IBS3_SOH_COR_Accuracy_2 0;
BA_ "GenSigTimeoutTime_TRSKM" SG_ 1957 IBS3_SOH_COR_Accuracy_2 0;
BA_ "GenSigStartValue" SG_ 1957 IBS3_SOH_Q_2 127;
BA_ "GenSigTimeoutTime_BCM" SG_ 1957 IBS3_SOH_Q_2 0;
BA_ "GenSigTimeoutTime_BSM2" SG_ 1957 IBS3_SOH_Q_2 0;
BA_ "GenSigTimeoutTime_CADM2" SG_ 1957 IBS3_SOH_Q_2 0;
BA_ "GenSigTimeoutTime_CVADAS" SG_ 1957 IBS3_SOH_Q_2 0;
BA_ "GenSigTimeoutTime_EPS" SG_ 1957 IBS3_SOH_Q_2 0;
BA_ "GenSigTimeoutTime_ORC" SG_ 1957 IBS3_SOH_Q_2 0;
BA_ "GenSigTimeoutTime_PAM" SG_ 1957 IBS3_SOH_Q_2 0;
BA_ "GenSigTimeoutTime_SGW" SG_ 1957 IBS3_SOH_Q_2 0;
BA_ "GenSigTimeoutTime_TRSKM" SG_ 1957 IBS3_SOH_Q_2 0;
BA_ "GenSigTimeoutTime_BCM" SG_ 1957 IBS3_SOH_Q_Accuracy_2 0;
BA_ "GenSigTimeoutTime_BSM2" SG_ 1957 IBS3_SOH_Q_Accuracy_2 0;
BA_ "GenSigTimeoutTime_CADM2" SG_ 1957 IBS3_SOH_Q_Accuracy_2 0;
BA_ "GenSigTimeoutTime_CVADAS" SG_ 1957 IBS3_SOH_Q_Accuracy_2 0;
BA_ "GenSigTimeoutTime_EPS" SG_ 1957 IBS3_SOH_Q_Accuracy_2 0;
BA_ "GenSigTimeoutTime_ORC" SG_ 1957 IBS3_SOH_Q_Accuracy_2 0;
BA_ "GenSigTimeoutTime_PAM" SG_ 1957 IBS3_SOH_Q_Accuracy_2 0;
BA_ "GenSigTimeoutTime_SGW" SG_ 1957 IBS3_SOH_Q_Accuracy_2 0;
BA_ "GenSigTimeoutTime_TRSKM" SG_ 1957 IBS3_SOH_Q_Accuracy_2 0;
BA_ "GenSigStartValue" SG_ 1957 IBS3_SOH_SUL_2 127;
BA_ "GenSigTimeoutTime_BCM" SG_ 1957 IBS3_SOH_SUL_2 0;
BA_ "GenSigTimeoutTime_BSM2" SG_ 1957 IBS3_SOH_SUL_2 0;
BA_ "GenSigTimeoutTime_CADM2" SG_ 1957 IBS3_SOH_SUL_2 0;
BA_ "GenSigTimeoutTime_CVADAS" SG_ 1957 IBS3_SOH_SUL_2 0;
BA_ "GenSigTimeoutTime_EPS" SG_ 1957 IBS3_SOH_SUL_2 0;
BA_ "GenSigTimeoutTime_ORC" SG_ 1957 IBS3_SOH_SUL_2 0;
BA_ "GenSigTimeoutTime_PAM" SG_ 1957 IBS3_SOH_SUL_2 0;
BA_ "GenSigTimeoutTime_SGW" SG_ 1957 IBS3_SOH_SUL_2 0;
BA_ "GenSigTimeoutTime_TRSKM" SG_ 1957 IBS3_SOH_SUL_2 0;
BA_ "GenSigTimeoutTime_BCM" SG_ 1957 IBS3_SOH_SUL_Accuracy_2 0;
BA_ "GenSigTimeoutTime_BSM2" SG_ 1957 IBS3_SOH_SUL_Accuracy_2 0;
BA_ "GenSigTimeoutTime_CADM2" SG_ 1957 IBS3_SOH_SUL_Accuracy_2 0;
BA_ "GenSigTimeoutTime_CVADAS" SG_ 1957 IBS3_SOH_SUL_Accuracy_2 0;
BA_ "GenSigTimeoutTime_EPS" SG_ 1957 IBS3_SOH_SUL_Accuracy_2 0;
BA_ "GenSigTimeoutTime_ORC" SG_ 1957 IBS3_SOH_SUL_Accuracy_2 0;
BA_ "GenSigTimeoutTime_PAM" SG_ 1957 IBS3_SOH_SUL_Accuracy_2 0;
BA_ "GenSigTimeoutTime_SGW" SG_ 1957 IBS3_SOH_SUL_Accuracy_2 0;
BA_ "GenSigTimeoutTime_TRSKM" SG_ 1957 IBS3_SOH_SUL_Accuracy_2 0;
BA_ "GenSigStartValue" SG_ 1957 IBS3_T_BATT_2 255;
BA_ "GenSigTimeoutTime_BCM" SG_ 1957 IBS3_T_BATT_2 0;
BA_ "GenSigTimeoutTime_BSM2" SG_ 1957 IBS3_T_BATT_2 0;
BA_ "GenSigTimeoutTime_CADM2" SG_ 1957 IBS3_T_BATT_2 0;
BA_ "GenSigTimeoutTime_CVADAS" SG_ 1957 IBS3_T_BATT_2 0;
BA_ "GenSigTimeoutTime_EPS" SG_ 1957 IBS3_T_BATT_2 0;
BA_ "GenSigTimeoutTime_ORC" SG_ 1957 IBS3_T_BATT_2 0;
BA_ "GenSigTimeoutTime_PAM" SG_ 1957 IBS3_T_BATT_2 0;
BA_ "GenSigTimeoutTime_TRSKM" SG_ 1957 IBS3_T_BATT_2 0;
BA_ "GenSigTimeoutTime_BCM" SG_ 1957 IBS3_TempFailStatus_2 0;
BA_ "GenSigTimeoutTime_BSM2" SG_ 1957 IBS3_TempFailStatus_2 0;
BA_ "GenSigTimeoutTime_CADM2" SG_ 1957 IBS3_TempFailStatus_2 0;
BA_ "GenSigTimeoutTime_CVADAS" SG_ 1957 IBS3_TempFailStatus_2 0;
BA_ "GenSigTimeoutTime_EPS" SG_ 1957 IBS3_TempFailStatus_2 0;
BA_ "GenSigTimeoutTime_ORC" SG_ 1957 IBS3_TempFailStatus_2 0;
BA_ "GenSigTimeoutTime_PAM" SG_ 1957 IBS3_TempFailStatus_2 0;
BA_ "GenSigTimeoutTime_TRSKM" SG_ 1957 IBS3_TempFailStatus_2 0;
BA_ "GenSigTimeoutTime_BCM" SG_ 1957 IBS3_TmLstResetDays_2 0;
BA_ "GenSigTimeoutTime_BSM2" SG_ 1957 IBS3_TmLstResetDays_2 0;
BA_ "GenSigTimeoutTime_CADM2" SG_ 1957 IBS3_TmLstResetDays_2 0;
BA_ "GenSigTimeoutTime_CVADAS" SG_ 1957 IBS3_TmLstResetDays_2 0;
BA_ "GenSigTimeoutTime_EPS" SG_ 1957 IBS3_TmLstResetDays_2 0;
BA_ "GenSigTimeoutTime_ORC" SG_ 1957 IBS3_TmLstResetDays_2 0;
BA_ "GenSigTimeoutTime_PAM" SG_ 1957 IBS3_TmLstResetDays_2 0;
BA_ "GenSigTimeoutTime_SGW" SG_ 1957 IBS3_TmLstResetDays_2 0;
BA_ "GenSigTimeoutTime_TRSKM" SG_ 1957 IBS3_TmLstResetDays_2 0;
BA_ "GenSigTimeoutTime_BCM" SG_ 1957 IBS3_TmLstResetSec_2 0;
BA_ "GenSigTimeoutTime_BSM2" SG_ 1957 IBS3_TmLstResetSec_2 0;
BA_ "GenSigTimeoutTime_CADM2" SG_ 1957 IBS3_TmLstResetSec_2 0;
BA_ "GenSigTimeoutTime_CVADAS" SG_ 1957 IBS3_TmLstResetSec_2 0;
BA_ "GenSigTimeoutTime_EPS" SG_ 1957 IBS3_TmLstResetSec_2 0;
BA_ "GenSigTimeoutTime_ORC" SG_ 1957 IBS3_TmLstResetSec_2 0;
BA_ "GenSigTimeoutTime_PAM" SG_ 1957 IBS3_TmLstResetSec_2 0;
BA_ "GenSigTimeoutTime_SGW" SG_ 1957 IBS3_TmLstResetSec_2 0;
BA_ "GenSigTimeoutTime_TRSKM" SG_ 1957 IBS3_TmLstResetSec_2 0;
BA_ "GenSigTimeoutTime_BSM2" SG_ 1626 CRC_IMPACTINFO 0;
BA_ "GenSigTimeoutTime_CADM2" SG_ 1626 CRC_IMPACTINFO 0;
BA_ "GenSigTimeoutTime_CVADAS" SG_ 1626 CRC_IMPACTINFO 0;
BA_ "GenSigTimeoutTime_EPS" SG_ 1626 CRC_IMPACTINFO 0;
BA_ "GenSigTimeoutTime_ORC" SG_ 1626 CRC_IMPACTINFO 0;
BA_ "GenSigTimeoutTime_PAM" SG_ 1626 CRC_IMPACTINFO 0;
BA_ "GenSigTimeoutTime_TRSKM" SG_ 1626 CRC_IMPACTINFO 0;
BA_ "GenSigTimeoutTime_BCM" SG_ 1626 IMPACT_B 0;
BA_ "GenSigTimeoutTime_BSM2" SG_ 1626 IMPACT_B 0;
BA_ "GenSigTimeoutTime_CVADAS" SG_ 1626 IMPACT_B 0;
BA_ "GenSigTimeoutTime_EPS" SG_ 1626 IMPACT_B 0;
BA_ "GenSigTimeoutTime_ORC" SG_ 1626 IMPACT_B 0;
BA_ "GenSigTimeoutTime_PAM" SG_ 1626 IMPACT_B 0;
BA_ "GenSigTimeoutTime_TRSKM" SG_ 1626 IMPACT_B 0;
BA_ "GenSigTimeoutTime_BCM" SG_ 1626 IMPACT_C 0;
BA_ "GenSigTimeoutTime_BSM2" SG_ 1626 IMPACT_C 0;
BA_ "GenSigTimeoutTime_CVADAS" SG_ 1626 IMPACT_C 0;
BA_ "GenSigTimeoutTime_EPS" SG_ 1626 IMPACT_C 0;
BA_ "GenSigTimeoutTime_ORC" SG_ 1626 IMPACT_C 0;
BA_ "GenSigTimeoutTime_PAM" SG_ 1626 IMPACT_C 0;
BA_ "GenSigTimeoutTime_TRSKM" SG_ 1626 IMPACT_C 0;
BA_ "GenSigTimeoutTime_BCM" SG_ 1626 IMPACT_F 0;
BA_ "GenSigTimeoutTime_BSM2" SG_ 1626 IMPACT_F 0;
BA_ "GenSigTimeoutTime_CVADAS" SG_ 1626 IMPACT_F 0;
BA_ "GenSigTimeoutTime_EPS" SG_ 1626 IMPACT_F 0;
BA_ "GenSigTimeoutTime_ORC" SG_ 1626 IMPACT_F 0;
BA_ "GenSigTimeoutTime_PAM" SG_ 1626 IMPACT_F 0;
BA_ "GenSigTimeoutTime_TRSKM" SG_ 1626 IMPACT_F 0;
BA_ "GenSigTimeoutTime_BCM" SG_ 1626 IMPACT_I 0;
BA_ "GenSigTimeoutTime_BSM2" SG_ 1626 IMPACT_I 0;
BA_ "GenSigTimeoutTime_CVADAS" SG_ 1626 IMPACT_I 0;
BA_ "GenSigTimeoutTime_EPS" SG_ 1626 IMPACT_I 0;
BA_ "GenSigTimeoutTime_ORC" SG_ 1626 IMPACT_I 0;
BA_ "GenSigTimeoutTime_PAM" SG_ 1626 IMPACT_I 0;
BA_ "GenSigTimeoutTime_TRSKM" SG_ 1626 IMPACT_I 0;
BA_ "GenSigTimeoutTime_BCM" SG_ 1626 IMPACT_K 0;
BA_ "GenSigTimeoutTime_BSM2" SG_ 1626 IMPACT_K 0;
BA_ "GenSigTimeoutTime_CVADAS" SG_ 1626 IMPACT_K 0;
BA_ "GenSigTimeoutTime_EPS" SG_ 1626 IMPACT_K 0;
BA_ "GenSigTimeoutTime_ORC" SG_ 1626 IMPACT_K 0;
BA_ "GenSigTimeoutTime_PAM" SG_ 1626 IMPACT_K 0;
BA_ "GenSigTimeoutTime_TRSKM" SG_ 1626 IMPACT_K 0;
BA_ "GenSigTimeoutTime_BCM" SG_ 1626 IMPACT_M 0;
BA_ "GenSigTimeoutTime_BSM2" SG_ 1626 IMPACT_M 0;
BA_ "GenSigTimeoutTime_CVADAS" SG_ 1626 IMPACT_M 0;
BA_ "GenSigTimeoutTime_EPS" SG_ 1626 IMPACT_M 0;
BA_ "GenSigTimeoutTime_ORC" SG_ 1626 IMPACT_M 0;
BA_ "GenSigTimeoutTime_PAM" SG_ 1626 IMPACT_M 0;
BA_ "GenSigTimeoutTime_TRSKM" SG_ 1626 IMPACT_M 0;
BA_ "GenSigSendType" SG_ 1626 IMPACTCommand 5;
BA_ "GenSigTimeoutTime_BSM2" SG_ 1626 IMPACTCommand 0;
BA_ "GenSigTimeoutTime_CVADAS" SG_ 1626 IMPACTCommand 0;
BA_ "GenSigTimeoutTime_EPS" SG_ 1626 IMPACTCommand 0;
BA_ "GenSigTimeoutTime_ORC" SG_ 1626 IMPACTCommand 0;
BA_ "GenSigTimeoutTime_PAM" SG_ 1626 IMPACTCommand 0;
BA_ "GenSigTimeoutTime_TRSKM" SG_ 1626 IMPACTCommand 0;
BA_ "GenSigStartValue" SG_ 1626 IMPACTConfirm 1;
BA_ "GenSigInactiveValue" SG_ 1626 IMPACTConfirm 1;
BA_ "GenSigSendType" SG_ 1626 IMPACTConfirm 5;
BA_ "GenSigTimeoutTime_BSM2" SG_ 1626 IMPACTConfirm 0;
BA_ "GenSigTimeoutTime_CVADAS" SG_ 1626 IMPACTConfirm 0;
BA_ "GenSigTimeoutTime_EPS" SG_ 1626 IMPACTConfirm 0;
BA_ "GenSigTimeoutTime_ORC" SG_ 1626 IMPACTConfirm 0;
BA_ "GenSigTimeoutTime_PAM" SG_ 1626 IMPACTConfirm 0;
BA_ "GenSigTimeoutTime_TRSKM" SG_ 1626 IMPACTConfirm 0;
BA_ "GenSigSendType" SG_ 1626 IMPACTFailSts 5;
BA_ "GenSigTimeoutTime_BCM" SG_ 1626 IMPACTFailSts 0;
BA_ "GenSigTimeoutTime_BSM2" SG_ 1626 IMPACTFailSts 0;
BA_ "GenSigTimeoutTime_CADM2" SG_ 1626 IMPACTFailSts 0;
BA_ "GenSigTimeoutTime_CVADAS" SG_ 1626 IMPACTFailSts 0;
BA_ "GenSigTimeoutTime_EPS" SG_ 1626 IMPACTFailSts 0;
BA_ "GenSigTimeoutTime_ORC" SG_ 1626 IMPACTFailSts 0;
BA_ "GenSigTimeoutTime_PAM" SG_ 1626 IMPACTFailSts 0;
BA_ "GenSigTimeoutTime_TRSKM" SG_ 1626 IMPACTFailSts 0;
BA_ "GenSigTimeoutTime_BSM2" SG_ 1626 IMPACTThreshold 0;
BA_ "GenSigTimeoutTime_CADM2" SG_ 1626 IMPACTThreshold 0;
BA_ "GenSigTimeoutTime_CVADAS" SG_ 1626 IMPACTThreshold 0;
BA_ "GenSigTimeoutTime_EPS" SG_ 1626 IMPACTThreshold 0;
BA_ "GenSigTimeoutTime_ORC" SG_ 1626 IMPACTThreshold 0;
BA_ "GenSigTimeoutTime_PAM" SG_ 1626 IMPACTThreshold 0;
BA_ "GenSigTimeoutTime_SGW" SG_ 1626 IMPACTThreshold 0;
BA_ "GenSigTimeoutTime_TRSKM" SG_ 1626 IMPACTThreshold 0;
BA_ "GenSigTimeoutTime_BSM2" SG_ 1626 MessageCounter_IMPACTINFO 0;
BA_ "GenSigTimeoutTime_CADM2" SG_ 1626 MessageCounter_IMPACTINFO 0;
BA_ "GenSigTimeoutTime_CVADAS" SG_ 1626 MessageCounter_IMPACTINFO 0;
BA_ "GenSigTimeoutTime_EPS" SG_ 1626 MessageCounter_IMPACTINFO 0;
BA_ "GenSigTimeoutTime_ORC" SG_ 1626 MessageCounter_IMPACTINFO 0;
BA_ "GenSigTimeoutTime_PAM" SG_ 1626 MessageCounter_IMPACTINFO 0;
BA_ "GenSigTimeoutTime_TRSKM" SG_ 1626 MessageCounter_IMPACTINFO 0;
BA_ "GenSigTimeoutTime_BCM" SG_ 1829 CRC_IPC1 0;
BA_ "GenSigTimeoutTime_CVADAS" SG_ 1829 CRC_IPC1 0;
BA_ "GenSigTimeoutTime_EPS" SG_ 1829 CRC_IPC1 0;
BA_ "GenSigTimeoutTime_ORC" SG_ 1829 CRC_IPC1 0;
BA_ "GenSigTimeoutTime_PAM" SG_ 1829 CRC_IPC1 0;
BA_ "GenSigTimeoutTime_SGW" SG_ 1829 CRC_IPC1 0;
BA_ "GenSigTimeoutTime_TRSKM" SG_ 1829 CRC_IPC1 0;
BA_ "GenSigTimeoutTime_BCM" SG_ 1829 MessageCounter_IPC1 0;
BA_ "GenSigTimeoutTime_CVADAS" SG_ 1829 MessageCounter_IPC1 0;
BA_ "GenSigTimeoutTime_EPS" SG_ 1829 MessageCounter_IPC1 0;
BA_ "GenSigTimeoutTime_ORC" SG_ 1829 MessageCounter_IPC1 0;
BA_ "GenSigTimeoutTime_PAM" SG_ 1829 MessageCounter_IPC1 0;
BA_ "GenSigTimeoutTime_SGW" SG_ 1829 MessageCounter_IPC1 0;
BA_ "GenSigTimeoutTime_TRSKM" SG_ 1829 MessageCounter_IPC1 0;
BA_ "GenSigTimeoutTime_BCM" SG_ 1829 TotalOdometer 0;
BA_ "GenSigTimeoutTime_SGW" SG_ 1829 TotalOdometer 0;
BA_ "GenSigTimeoutTime_BCM" SG_ 600 AirBagLamp_FailSts 0;
BA_ "GenSigTimeoutTime_BSM2" SG_ 600 AirBagLamp_FailSts 0;
BA_ "GenSigTimeoutTime_CADM2" SG_ 600 AirBagLamp_FailSts 0;
BA_ "GenSigTimeoutTime_CVADAS" SG_ 600 AirBagLamp_FailSts 0;
BA_ "GenSigTimeoutTime_EPS" SG_ 600 AirBagLamp_FailSts 0;
BA_ "GenSigTimeoutTime_PAM" SG_ 600 AirBagLamp_FailSts 0;
BA_ "GenSigTimeoutTime_SGW" SG_ 600 AirBagLamp_FailSts 0;
BA_ "GenSigTimeoutTime_TRSKM" SG_ 600 AirBagLamp_FailSts 0;
BA_ "GenSigTimeoutTime_BCM" SG_ 1432 CRC_IPC6 0;
BA_ "GenSigTimeoutTime_BSM2" SG_ 1432 CRC_IPC6 0;
BA_ "GenSigTimeoutTime_CVADAS" SG_ 1432 CRC_IPC6 0;
BA_ "GenSigTimeoutTime_EPS" SG_ 1432 CRC_IPC6 0;
BA_ "GenSigTimeoutTime_ORC" SG_ 1432 CRC_IPC6 0;
BA_ "GenSigTimeoutTime_PAM" SG_ 1432 CRC_IPC6 0;
BA_ "GenSigTimeoutTime_SGW" SG_ 1432 CRC_IPC6 0;
BA_ "GenSigTimeoutTime_TRSKM" SG_ 1432 CRC_IPC6 0;
BA_ "GenSigSendType" SG_ 1432 HAS_SoH_IPC 3;
BA_ "GenSigTimeoutTime_BCM" SG_ 1432 HAS_SoH_IPC 0;
BA_ "GenSigTimeoutTime_BSM2" SG_ 1432 HAS_SoH_IPC 0;
BA_ "GenSigTimeoutTime_CVADAS" SG_ 1432 HAS_SoH_IPC 0;
BA_ "GenSigTimeoutTime_EPS" SG_ 1432 HAS_SoH_IPC 0;
BA_ "GenSigTimeoutTime_ORC" SG_ 1432 HAS_SoH_IPC 0;
BA_ "GenSigTimeoutTime_PAM" SG_ 1432 HAS_SoH_IPC 0;
BA_ "GenSigTimeoutTime_SGW" SG_ 1432 HAS_SoH_IPC 0;
BA_ "GenSigTimeoutTime_TRSKM" SG_ 1432 HAS_SoH_IPC 0;
BA_ "GenSigTimeoutTime_BCM" SG_ 1432 MessageCounter_IPC6 0;
BA_ "GenSigTimeoutTime_BSM2" SG_ 1432 MessageCounter_IPC6 0;
BA_ "GenSigTimeoutTime_CVADAS" SG_ 1432 MessageCounter_IPC6 0;
BA_ "GenSigTimeoutTime_EPS" SG_ 1432 MessageCounter_IPC6 0;
BA_ "GenSigTimeoutTime_ORC" SG_ 1432 MessageCounter_IPC6 0;
BA_ "GenSigTimeoutTime_PAM" SG_ 1432 MessageCounter_IPC6 0;
BA_ "GenSigTimeoutTime_SGW" SG_ 1432 MessageCounter_IPC6 0;
BA_ "GenSigTimeoutTime_TRSKM" SG_ 1432 MessageCounter_IPC6 0;
BA_ "GenSigSendType" SG_ 1443 Act_Lane_Mgt 3;
BA_ "GenSigTimeoutTime_BCM" SG_ 1443 Act_Lane_Mgt 0;
BA_ "GenSigTimeoutTime_BSM2" SG_ 1443 Act_Lane_Mgt 0;
BA_ "GenSigTimeoutTime_CADM2" SG_ 1443 Act_Lane_Mgt 0;
BA_ "GenSigTimeoutTime_CVADAS" SG_ 1443 Act_Lane_Mgt 0;
BA_ "GenSigTimeoutTime_EPS" SG_ 1443 Act_Lane_Mgt 0;
BA_ "GenSigTimeoutTime_PAM" SG_ 1443 Act_Lane_Mgt 0;
BA_ "GenSigTimeoutTime_SGW" SG_ 1443 Act_Lane_Mgt 0;
BA_ "GenSigTimeoutTime_TRSKM" SG_ 1443 Act_Lane_Mgt 0;
BA_ "GenSigSendType" SG_ 1443 Act_Lane_Mgt_Strength 3;
BA_ "GenSigTimeoutTime_BCM" SG_ 1443 Act_Lane_Mgt_Strength 0;
BA_ "GenSigTimeoutTime_BSM2" SG_ 1443 Act_Lane_Mgt_Strength 0;
BA_ "GenSigTimeoutTime_CADM2" SG_ 1443 Act_Lane_Mgt_Strength 0;
BA_ "GenSigTimeoutTime_CVADAS" SG_ 1443 Act_Lane_Mgt_Strength 0;
BA_ "GenSigTimeoutTime_EPS" SG_ 1443 Act_Lane_Mgt_Strength 0;
BA_ "GenSigTimeoutTime_PAM" SG_ 1443 Act_Lane_Mgt_Strength 0;
BA_ "GenSigTimeoutTime_SGW" SG_ 1443 Act_Lane_Mgt_Strength 0;
BA_ "GenSigTimeoutTime_TRSKM" SG_ 1443 Act_Lane_Mgt_Strength 0;
BA_ "GenSigSendType" SG_ 1443 Active_Park_Mode 3;
BA_ "GenSigTimeoutTime_BCM" SG_ 1443 Active_Park_Mode 0;
BA_ "GenSigTimeoutTime_BSM2" SG_ 1443 Active_Park_Mode 0;
BA_ "GenSigTimeoutTime_CADM2" SG_ 1443 Active_Park_Mode 0;
BA_ "GenSigTimeoutTime_EPS" SG_ 1443 Active_Park_Mode 0;
BA_ "GenSigTimeoutTime_ORC" SG_ 1443 Active_Park_Mode 0;
BA_ "GenSigTimeoutTime_PAM" SG_ 1443 Active_Park_Mode 0;
BA_ "GenSigTimeoutTime_SGW" SG_ 1443 Active_Park_Mode 0;
BA_ "GenSigTimeoutTime_TRSKM" SG_ 1443 Active_Park_Mode 0;
BA_ "GenSigSendType" SG_ 1443 Backup_Cam_Delay 3;
BA_ "GenSigTimeoutTime_BCM" SG_ 1443 Backup_Cam_Delay 0;
BA_ "GenSigTimeoutTime_BSM2" SG_ 1443 Backup_Cam_Delay 0;
BA_ "GenSigTimeoutTime_CADM2" SG_ 1443 Backup_Cam_Delay 0;
BA_ "GenSigTimeoutTime_EPS" SG_ 1443 Backup_Cam_Delay 0;
BA_ "GenSigTimeoutTime_ORC" SG_ 1443 Backup_Cam_Delay 0;
BA_ "GenSigTimeoutTime_PAM" SG_ 1443 Backup_Cam_Delay 0;
BA_ "GenSigTimeoutTime_SGW" SG_ 1443 Backup_Cam_Delay 0;
BA_ "GenSigTimeoutTime_TRSKM" SG_ 1443 Backup_Cam_Delay 0;
BA_ "GenSigStartValue" SG_ 1443 DynamicGrid 1;
BA_ "GenSigSendType" SG_ 1443 DynamicGrid 1;
BA_ "GenSigTimeoutTime_BCM" SG_ 1443 DynamicGrid 0;
BA_ "GenSigTimeoutTime_BSM2" SG_ 1443 DynamicGrid 0;
BA_ "GenSigTimeoutTime_CADM2" SG_ 1443 DynamicGrid 0;
BA_ "GenSigTimeoutTime_EPS" SG_ 1443 DynamicGrid 0;
BA_ "GenSigTimeoutTime_ORC" SG_ 1443 DynamicGrid 0;
BA_ "GenSigTimeoutTime_PAM" SG_ 1443 DynamicGrid 0;
BA_ "GenSigTimeoutTime_SGW" SG_ 1443 DynamicGrid 0;
BA_ "GenSigTimeoutTime_TRSKM" SG_ 1443 DynamicGrid 0;
BA_ "GenSigSendType" SG_ 1443 Fwrd_Cam_Guidelines 3;
BA_ "GenSigTimeoutTime_BCM" SG_ 1443 Fwrd_Cam_Guidelines 0;
BA_ "GenSigTimeoutTime_BSM2" SG_ 1443 Fwrd_Cam_Guidelines 0;
BA_ "GenSigTimeoutTime_CADM2" SG_ 1443 Fwrd_Cam_Guidelines 0;
BA_ "GenSigTimeoutTime_EPS" SG_ 1443 Fwrd_Cam_Guidelines 0;
BA_ "GenSigTimeoutTime_ORC" SG_ 1443 Fwrd_Cam_Guidelines 0;
BA_ "GenSigTimeoutTime_PAM" SG_ 1443 Fwrd_Cam_Guidelines 0;
BA_ "GenSigTimeoutTime_SGW" SG_ 1443 Fwrd_Cam_Guidelines 0;
BA_ "GenSigTimeoutTime_TRSKM" SG_ 1443 Fwrd_Cam_Guidelines 0;
BA_ "GenSigSendType" SG_ 1443 LanguageSelection 3;
BA_ "GenSigTimeoutTime_BCM" SG_ 1443 LanguageSelection 0;
BA_ "GenSigTimeoutTime_BSM2" SG_ 1443 LanguageSelection 0;
BA_ "GenSigTimeoutTime_CADM2" SG_ 1443 LanguageSelection 0;
BA_ "GenSigTimeoutTime_EPS" SG_ 1443 LanguageSelection 0;
BA_ "GenSigTimeoutTime_ORC" SG_ 1443 LanguageSelection 0;
BA_ "GenSigTimeoutTime_PAM" SG_ 1443 LanguageSelection 0;
BA_ "GenSigTimeoutTime_SGW" SG_ 1443 LanguageSelection 0;
BA_ "GenSigTimeoutTime_TRSKM" SG_ 1443 LanguageSelection 0;
BA_ "GenSigStartValue" SG_ 1443 LDW_Intensity 2;
BA_ "GenSigSendType" SG_ 1443 LDW_Intensity 3;
BA_ "GenSigTimeoutTime_BCM" SG_ 1443 LDW_Intensity 0;
BA_ "GenSigTimeoutTime_BSM2" SG_ 1443 LDW_Intensity 0;
BA_ "GenSigTimeoutTime_CADM2" SG_ 1443 LDW_Intensity 0;
BA_ "GenSigTimeoutTime_CVADAS" SG_ 1443 LDW_Intensity 0;
BA_ "GenSigTimeoutTime_EPS" SG_ 1443 LDW_Intensity 0;
BA_ "GenSigTimeoutTime_PAM" SG_ 1443 LDW_Intensity 0;
BA_ "GenSigTimeoutTime_SGW" SG_ 1443 LDW_Intensity 0;
BA_ "GenSigTimeoutTime_TRSKM" SG_ 1443 LDW_Intensity 0;
BA_ "GenSigStartValue" SG_ 1443 LDW_Sensibility 2;
BA_ "GenSigSendType" SG_ 1443 LDW_Sensibility 3;
BA_ "GenSigTimeoutTime_BCM" SG_ 1443 LDW_Sensibility 0;
BA_ "GenSigTimeoutTime_BSM2" SG_ 1443 LDW_Sensibility 0;
BA_ "GenSigTimeoutTime_CADM2" SG_ 1443 LDW_Sensibility 0;
BA_ "GenSigTimeoutTime_CVADAS" SG_ 1443 LDW_Sensibility 0;
BA_ "GenSigTimeoutTime_EPS" SG_ 1443 LDW_Sensibility 0;
BA_ "GenSigTimeoutTime_PAM" SG_ 1443 LDW_Sensibility 0;
BA_ "GenSigTimeoutTime_SGW" SG_ 1443 LDW_Sensibility 0;
BA_ "GenSigTimeoutTime_TRSKM" SG_ 1443 LDW_Sensibility 0;
BA_ "GenSigStartValue" SG_ 1443 PamChimeVolumeFront 1;
BA_ "GenSigSendType" SG_ 1443 PamChimeVolumeFront 3;
BA_ "GenSigTimeoutTime_BCM" SG_ 1443 PamChimeVolumeFront 0;
BA_ "GenSigTimeoutTime_BSM2" SG_ 1443 PamChimeVolumeFront 0;
BA_ "GenSigTimeoutTime_CADM2" SG_ 1443 PamChimeVolumeFront 0;
BA_ "GenSigTimeoutTime_EPS" SG_ 1443 PamChimeVolumeFront 0;
BA_ "GenSigTimeoutTime_ORC" SG_ 1443 PamChimeVolumeFront 0;
BA_ "GenSigTimeoutTime_SGW" SG_ 1443 PamChimeVolumeFront 0;
BA_ "GenSigTimeoutTime_TRSKM" SG_ 1443 PamChimeVolumeFront 0;
BA_ "GenSigStartValue" SG_ 1443 PamChimeVolumeRear 1;
BA_ "GenSigSendType" SG_ 1443 PamChimeVolumeRear 3;
BA_ "GenSigTimeoutTime_BCM" SG_ 1443 PamChimeVolumeRear 0;
BA_ "GenSigTimeoutTime_BSM2" SG_ 1443 PamChimeVolumeRear 0;
BA_ "GenSigTimeoutTime_CADM2" SG_ 1443 PamChimeVolumeRear 0;
BA_ "GenSigTimeoutTime_EPS" SG_ 1443 PamChimeVolumeRear 0;
BA_ "GenSigTimeoutTime_ORC" SG_ 1443 PamChimeVolumeRear 0;
BA_ "GenSigTimeoutTime_SGW" SG_ 1443 PamChimeVolumeRear 0;
BA_ "GenSigTimeoutTime_TRSKM" SG_ 1443 PamChimeVolumeRear 0;
BA_ "GenSigSendType" SG_ 1443 Rear_Brk_Asst 3;
BA_ "GenSigTimeoutTime_BCM" SG_ 1443 Rear_Brk_Asst 0;
BA_ "GenSigTimeoutTime_BSM2" SG_ 1443 Rear_Brk_Asst 0;
BA_ "GenSigTimeoutTime_CADM2" SG_ 1443 Rear_Brk_Asst 0;
BA_ "GenSigTimeoutTime_EPS" SG_ 1443 Rear_Brk_Asst 0;
BA_ "GenSigTimeoutTime_ORC" SG_ 1443 Rear_Brk_Asst 0;
BA_ "GenSigTimeoutTime_SGW" SG_ 1443 Rear_Brk_Asst 0;
BA_ "GenSigTimeoutTime_TRSKM" SG_ 1443 Rear_Brk_Asst 0;
BA_ "GenSigSendType" SG_ 1443 SVC_Guidelines 3;
BA_ "GenSigTimeoutTime_BCM" SG_ 1443 SVC_Guidelines 0;
BA_ "GenSigTimeoutTime_BSM2" SG_ 1443 SVC_Guidelines 0;
BA_ "GenSigTimeoutTime_CADM2" SG_ 1443 SVC_Guidelines 0;
BA_ "GenSigTimeoutTime_EPS" SG_ 1443 SVC_Guidelines 0;
BA_ "GenSigTimeoutTime_ORC" SG_ 1443 SVC_Guidelines 0;
BA_ "GenSigTimeoutTime_PAM" SG_ 1443 SVC_Guidelines 0;
BA_ "GenSigTimeoutTime_SGW" SG_ 1443 SVC_Guidelines 0;
BA_ "GenSigTimeoutTime_TRSKM" SG_ 1443 SVC_Guidelines 0;
BA_ "GenSigTimeoutTime_BCM" SG_ 2654486528 CBV_bit0_RepeatMessageRequestBit 0;
BA_ "GenSigTimeoutTime_BSM2" SG_ 2654486528 CBV_bit0_RepeatMessageRequestBit 0;
BA_ "GenSigTimeoutTime_CADM2" SG_ 2654486528 CBV_bit0_RepeatMessageRequestBit 0;
BA_ "GenSigTimeoutTime_CVADAS" SG_ 2654486528 CBV_bit0_RepeatMessageRequestBit 0;
BA_ "GenSigTimeoutTime_EPS" SG_ 2654486528 CBV_bit0_RepeatMessageRequestBit 0;
BA_ "GenSigTimeoutTime_ORC" SG_ 2654486528 CBV_bit0_RepeatMessageRequestBit 0;
BA_ "GenSigTimeoutTime_PAM" SG_ 2654486528 CBV_bit0_RepeatMessageRequestBit 0;
BA_ "GenSigTimeoutTime_SGW" SG_ 2654486528 CBV_bit0_RepeatMessageRequestBit 0;
BA_ "GenSigTimeoutTime_TRSKM" SG_ 2654486528 CBV_bit0_RepeatMessageRequestBit 0;
BA_ "GenSigTimeoutTime_BCM" SG_ 2654486528 CBV_bit1 0;
BA_ "GenSigTimeoutTime_BSM2" SG_ 2654486528 CBV_bit1 0;
BA_ "GenSigTimeoutTime_CADM2" SG_ 2654486528 CBV_bit1 0;
BA_ "GenSigTimeoutTime_CVADAS" SG_ 2654486528 CBV_bit1 0;
BA_ "GenSigTimeoutTime_EPS" SG_ 2654486528 CBV_bit1 0;
BA_ "GenSigTimeoutTime_ORC" SG_ 2654486528 CBV_bit1 0;
BA_ "GenSigTimeoutTime_PAM" SG_ 2654486528 CBV_bit1 0;
BA_ "GenSigTimeoutTime_SGW" SG_ 2654486528 CBV_bit1 0;
BA_ "GenSigTimeoutTime_TRSKM" SG_ 2654486528 CBV_bit1 0;
BA_ "GenSigTimeoutTime_BCM" SG_ 2654486528 CBV_bit2 0;
BA_ "GenSigTimeoutTime_BSM2" SG_ 2654486528 CBV_bit2 0;
BA_ "GenSigTimeoutTime_CADM2" SG_ 2654486528 CBV_bit2 0;
BA_ "GenSigTimeoutTime_CVADAS" SG_ 2654486528 CBV_bit2 0;
BA_ "GenSigTimeoutTime_EPS" SG_ 2654486528 CBV_bit2 0;
BA_ "GenSigTimeoutTime_ORC" SG_ 2654486528 CBV_bit2 0;
BA_ "GenSigTimeoutTime_PAM" SG_ 2654486528 CBV_bit2 0;
BA_ "GenSigTimeoutTime_SGW" SG_ 2654486528 CBV_bit2 0;
BA_ "GenSigTimeoutTime_TRSKM" SG_ 2654486528 CBV_bit2 0;
BA_ "GenSigTimeoutTime_BCM" SG_ 2654486528 CBV_bit3_NMCoordinatorBit 0;
BA_ "GenSigTimeoutTime_BSM2" SG_ 2654486528 CBV_bit3_NMCoordinatorBit 0;
BA_ "GenSigTimeoutTime_CADM2" SG_ 2654486528 CBV_bit3_NMCoordinatorBit 0;
BA_ "GenSigTimeoutTime_CVADAS" SG_ 2654486528 CBV_bit3_NMCoordinatorBit 0;
BA_ "GenSigTimeoutTime_EPS" SG_ 2654486528 CBV_bit3_NMCoordinatorBit 0;
BA_ "GenSigTimeoutTime_ORC" SG_ 2654486528 CBV_bit3_NMCoordinatorBit 0;
BA_ "GenSigTimeoutTime_PAM" SG_ 2654486528 CBV_bit3_NMCoordinatorBit 0;
BA_ "GenSigTimeoutTime_SGW" SG_ 2654486528 CBV_bit3_NMCoordinatorBit 0;
BA_ "GenSigTimeoutTime_TRSKM" SG_ 2654486528 CBV_bit3_NMCoordinatorBit 0;
BA_ "GenSigTimeoutTime_BCM" SG_ 2654486528 CBV_bit4_ActiveWakeupBit 0;
BA_ "GenSigTimeoutTime_BSM2" SG_ 2654486528 CBV_bit4_ActiveWakeupBit 0;
BA_ "GenSigTimeoutTime_CADM2" SG_ 2654486528 CBV_bit4_ActiveWakeupBit 0;
BA_ "GenSigTimeoutTime_CVADAS" SG_ 2654486528 CBV_bit4_ActiveWakeupBit 0;
BA_ "GenSigTimeoutTime_EPS" SG_ 2654486528 CBV_bit4_ActiveWakeupBit 0;
BA_ "GenSigTimeoutTime_ORC" SG_ 2654486528 CBV_bit4_ActiveWakeupBit 0;
BA_ "GenSigTimeoutTime_PAM" SG_ 2654486528 CBV_bit4_ActiveWakeupBit 0;
BA_ "GenSigTimeoutTime_SGW" SG_ 2654486528 CBV_bit4_ActiveWakeupBit 0;
BA_ "GenSigTimeoutTime_TRSKM" SG_ 2654486528 CBV_bit4_ActiveWakeupBit 0;
BA_ "GenSigTimeoutTime_BCM" SG_ 2654486528 CBV_bit5 0;
BA_ "GenSigTimeoutTime_BSM2" SG_ 2654486528 CBV_bit5 0;
BA_ "GenSigTimeoutTime_CADM2" SG_ 2654486528 CBV_bit5 0;
BA_ "GenSigTimeoutTime_CVADAS" SG_ 2654486528 CBV_bit5 0;
BA_ "GenSigTimeoutTime_EPS" SG_ 2654486528 CBV_bit5 0;
BA_ "GenSigTimeoutTime_ORC" SG_ 2654486528 CBV_bit5 0;
BA_ "GenSigTimeoutTime_PAM" SG_ 2654486528 CBV_bit5 0;
BA_ "GenSigTimeoutTime_SGW" SG_ 2654486528 CBV_bit5 0;
BA_ "GenSigTimeoutTime_TRSKM" SG_ 2654486528 CBV_bit5 0;
BA_ "GenSigTimeoutTime_BCM" SG_ 2654486528 CBV_bit6_PartialNtwInfBit 0;
BA_ "GenSigTimeoutTime_BSM2" SG_ 2654486528 CBV_bit6_PartialNtwInfBit 0;
BA_ "GenSigTimeoutTime_CADM2" SG_ 2654486528 CBV_bit6_PartialNtwInfBit 0;
BA_ "GenSigTimeoutTime_CVADAS" SG_ 2654486528 CBV_bit6_PartialNtwInfBit 0;
BA_ "GenSigTimeoutTime_EPS" SG_ 2654486528 CBV_bit6_PartialNtwInfBit 0;
BA_ "GenSigTimeoutTime_ORC" SG_ 2654486528 CBV_bit6_PartialNtwInfBit 0;
BA_ "GenSigTimeoutTime_PAM" SG_ 2654486528 CBV_bit6_PartialNtwInfBit 0;
BA_ "GenSigTimeoutTime_SGW" SG_ 2654486528 CBV_bit6_PartialNtwInfBit 0;
BA_ "GenSigTimeoutTime_TRSKM" SG_ 2654486528 CBV_bit6_PartialNtwInfBit 0;
BA_ "GenSigTimeoutTime_BCM" SG_ 2654486528 CBV_bit7 0;
BA_ "GenSigTimeoutTime_BSM2" SG_ 2654486528 CBV_bit7 0;
BA_ "GenSigTimeoutTime_CADM2" SG_ 2654486528 CBV_bit7 0;
BA_ "GenSigTimeoutTime_CVADAS" SG_ 2654486528 CBV_bit7 0;
BA_ "GenSigTimeoutTime_EPS" SG_ 2654486528 CBV_bit7 0;
BA_ "GenSigTimeoutTime_ORC" SG_ 2654486528 CBV_bit7 0;
BA_ "GenSigTimeoutTime_PAM" SG_ 2654486528 CBV_bit7 0;
BA_ "GenSigTimeoutTime_SGW" SG_ 2654486528 CBV_bit7 0;
BA_ "GenSigTimeoutTime_TRSKM" SG_ 2654486528 CBV_bit7 0;
BA_ "GenSigTimeoutTime_BCM" SG_ 2654486528 SourceNodeIdentifier 0;
BA_ "GenSigTimeoutTime_BSM2" SG_ 2654486528 SourceNodeIdentifier 0;
BA_ "GenSigTimeoutTime_CADM2" SG_ 2654486528 SourceNodeIdentifier 0;
BA_ "GenSigTimeoutTime_CVADAS" SG_ 2654486528 SourceNodeIdentifier 0;
BA_ "GenSigTimeoutTime_EPS" SG_ 2654486528 SourceNodeIdentifier 0;
BA_ "GenSigTimeoutTime_ORC" SG_ 2654486528 SourceNodeIdentifier 0;
BA_ "GenSigTimeoutTime_PAM" SG_ 2654486528 SourceNodeIdentifier 0;
BA_ "GenSigTimeoutTime_SGW" SG_ 2654486528 SourceNodeIdentifier 0;
BA_ "GenSigTimeoutTime_TRSKM" SG_ 2654486528 SourceNodeIdentifier 0;
BA_ "GenSigTimeoutTime_BCM" SG_ 2654486676 CBV_bit0_RepeatMessageRequestBit 0;
BA_ "GenSigTimeoutTime_BSM2" SG_ 2654486676 CBV_bit0_RepeatMessageRequestBit 0;
BA_ "GenSigTimeoutTime_CADM2" SG_ 2654486676 CBV_bit0_RepeatMessageRequestBit 0;
BA_ "GenSigTimeoutTime_CVADAS" SG_ 2654486676 CBV_bit0_RepeatMessageRequestBit 0;
BA_ "GenSigTimeoutTime_EPS" SG_ 2654486676 CBV_bit0_RepeatMessageRequestBit 0;
BA_ "GenSigTimeoutTime_ORC" SG_ 2654486676 CBV_bit0_RepeatMessageRequestBit 0;
BA_ "GenSigTimeoutTime_PAM" SG_ 2654486676 CBV_bit0_RepeatMessageRequestBit 0;
BA_ "GenSigTimeoutTime_SGW" SG_ 2654486676 CBV_bit0_RepeatMessageRequestBit 0;
BA_ "GenSigTimeoutTime_TRSKM" SG_ 2654486676 CBV_bit0_RepeatMessageRequestBit 0;
BA_ "GenSigTimeoutTime_BCM" SG_ 2654486676 CBV_bit1 0;
BA_ "GenSigTimeoutTime_BSM2" SG_ 2654486676 CBV_bit1 0;
BA_ "GenSigTimeoutTime_CADM2" SG_ 2654486676 CBV_bit1 0;
BA_ "GenSigTimeoutTime_CVADAS" SG_ 2654486676 CBV_bit1 0;
BA_ "GenSigTimeoutTime_EPS" SG_ 2654486676 CBV_bit1 0;
BA_ "GenSigTimeoutTime_ORC" SG_ 2654486676 CBV_bit1 0;
BA_ "GenSigTimeoutTime_PAM" SG_ 2654486676 CBV_bit1 0;
BA_ "GenSigTimeoutTime_SGW" SG_ 2654486676 CBV_bit1 0;
BA_ "GenSigTimeoutTime_TRSKM" SG_ 2654486676 CBV_bit1 0;
BA_ "GenSigTimeoutTime_BCM" SG_ 2654486676 CBV_bit2 0;
BA_ "GenSigTimeoutTime_BSM2" SG_ 2654486676 CBV_bit2 0;
BA_ "GenSigTimeoutTime_CADM2" SG_ 2654486676 CBV_bit2 0;
BA_ "GenSigTimeoutTime_CVADAS" SG_ 2654486676 CBV_bit2 0;
BA_ "GenSigTimeoutTime_EPS" SG_ 2654486676 CBV_bit2 0;
BA_ "GenSigTimeoutTime_ORC" SG_ 2654486676 CBV_bit2 0;
BA_ "GenSigTimeoutTime_PAM" SG_ 2654486676 CBV_bit2 0;
BA_ "GenSigTimeoutTime_SGW" SG_ 2654486676 CBV_bit2 0;
BA_ "GenSigTimeoutTime_TRSKM" SG_ 2654486676 CBV_bit2 0;
BA_ "GenSigTimeoutTime_BCM" SG_ 2654486676 CBV_bit3_NMCoordinatorBit 0;
BA_ "GenSigTimeoutTime_BSM2" SG_ 2654486676 CBV_bit3_NMCoordinatorBit 0;
BA_ "GenSigTimeoutTime_CADM2" SG_ 2654486676 CBV_bit3_NMCoordinatorBit 0;
BA_ "GenSigTimeoutTime_CVADAS" SG_ 2654486676 CBV_bit3_NMCoordinatorBit 0;
BA_ "GenSigTimeoutTime_EPS" SG_ 2654486676 CBV_bit3_NMCoordinatorBit 0;
BA_ "GenSigTimeoutTime_ORC" SG_ 2654486676 CBV_bit3_NMCoordinatorBit 0;
BA_ "GenSigTimeoutTime_PAM" SG_ 2654486676 CBV_bit3_NMCoordinatorBit 0;
BA_ "GenSigTimeoutTime_SGW" SG_ 2654486676 CBV_bit3_NMCoordinatorBit 0;
BA_ "GenSigTimeoutTime_TRSKM" SG_ 2654486676 CBV_bit3_NMCoordinatorBit 0;
BA_ "GenSigTimeoutTime_BCM" SG_ 2654486676 CBV_bit4_ActiveWakeupBit 0;
BA_ "GenSigTimeoutTime_BSM2" SG_ 2654486676 CBV_bit4_ActiveWakeupBit 0;
BA_ "GenSigTimeoutTime_CADM2" SG_ 2654486676 CBV_bit4_ActiveWakeupBit 0;
BA_ "GenSigTimeoutTime_CVADAS" SG_ 2654486676 CBV_bit4_ActiveWakeupBit 0;
BA_ "GenSigTimeoutTime_EPS" SG_ 2654486676 CBV_bit4_ActiveWakeupBit 0;
BA_ "GenSigTimeoutTime_ORC" SG_ 2654486676 CBV_bit4_ActiveWakeupBit 0;
BA_ "GenSigTimeoutTime_PAM" SG_ 2654486676 CBV_bit4_ActiveWakeupBit 0;
BA_ "GenSigTimeoutTime_SGW" SG_ 2654486676 CBV_bit4_ActiveWakeupBit 0;
BA_ "GenSigTimeoutTime_TRSKM" SG_ 2654486676 CBV_bit4_ActiveWakeupBit 0;
BA_ "GenSigTimeoutTime_BCM" SG_ 2654486676 CBV_bit5 0;
BA_ "GenSigTimeoutTime_BSM2" SG_ 2654486676 CBV_bit5 0;
BA_ "GenSigTimeoutTime_CADM2" SG_ 2654486676 CBV_bit5 0;
BA_ "GenSigTimeoutTime_CVADAS" SG_ 2654486676 CBV_bit5 0;
BA_ "GenSigTimeoutTime_EPS" SG_ 2654486676 CBV_bit5 0;
BA_ "GenSigTimeoutTime_ORC" SG_ 2654486676 CBV_bit5 0;
BA_ "GenSigTimeoutTime_PAM" SG_ 2654486676 CBV_bit5 0;
BA_ "GenSigTimeoutTime_SGW" SG_ 2654486676 CBV_bit5 0;
BA_ "GenSigTimeoutTime_TRSKM" SG_ 2654486676 CBV_bit5 0;
BA_ "GenSigTimeoutTime_BCM" SG_ 2654486676 CBV_bit6_PartialNtwInfBit 0;
BA_ "GenSigTimeoutTime_BSM2" SG_ 2654486676 CBV_bit6_PartialNtwInfBit 0;
BA_ "GenSigTimeoutTime_CADM2" SG_ 2654486676 CBV_bit6_PartialNtwInfBit 0;
BA_ "GenSigTimeoutTime_CVADAS" SG_ 2654486676 CBV_bit6_PartialNtwInfBit 0;
BA_ "GenSigTimeoutTime_EPS" SG_ 2654486676 CBV_bit6_PartialNtwInfBit 0;
BA_ "GenSigTimeoutTime_ORC" SG_ 2654486676 CBV_bit6_PartialNtwInfBit 0;
BA_ "GenSigTimeoutTime_PAM" SG_ 2654486676 CBV_bit6_PartialNtwInfBit 0;
BA_ "GenSigTimeoutTime_SGW" SG_ 2654486676 CBV_bit6_PartialNtwInfBit 0;
BA_ "GenSigTimeoutTime_TRSKM" SG_ 2654486676 CBV_bit6_PartialNtwInfBit 0;
BA_ "GenSigTimeoutTime_BCM" SG_ 2654486676 CBV_bit7 0;
BA_ "GenSigTimeoutTime_BSM2" SG_ 2654486676 CBV_bit7 0;
BA_ "GenSigTimeoutTime_CADM2" SG_ 2654486676 CBV_bit7 0;
BA_ "GenSigTimeoutTime_CVADAS" SG_ 2654486676 CBV_bit7 0;
BA_ "GenSigTimeoutTime_EPS" SG_ 2654486676 CBV_bit7 0;
BA_ "GenSigTimeoutTime_ORC" SG_ 2654486676 CBV_bit7 0;
BA_ "GenSigTimeoutTime_PAM" SG_ 2654486676 CBV_bit7 0;
BA_ "GenSigTimeoutTime_SGW" SG_ 2654486676 CBV_bit7 0;
BA_ "GenSigTimeoutTime_TRSKM" SG_ 2654486676 CBV_bit7 0;
BA_ "GenSigTimeoutTime_BCM" SG_ 2654486676 SourceNodeIdentifier 0;
BA_ "GenSigTimeoutTime_BSM2" SG_ 2654486676 SourceNodeIdentifier 0;
BA_ "GenSigTimeoutTime_CADM2" SG_ 2654486676 SourceNodeIdentifier 0;
BA_ "GenSigTimeoutTime_CVADAS" SG_ 2654486676 SourceNodeIdentifier 0;
BA_ "GenSigTimeoutTime_EPS" SG_ 2654486676 SourceNodeIdentifier 0;
BA_ "GenSigTimeoutTime_ORC" SG_ 2654486676 SourceNodeIdentifier 0;
BA_ "GenSigTimeoutTime_PAM" SG_ 2654486676 SourceNodeIdentifier 0;
BA_ "GenSigTimeoutTime_SGW" SG_ 2654486676 SourceNodeIdentifier 0;
BA_ "GenSigTimeoutTime_TRSKM" SG_ 2654486676 SourceNodeIdentifier 0;
BA_ "GenSigTimeoutTime_BCM" SG_ 2654486670 CBV_bit0_RepeatMessageRequestBit 0;
BA_ "GenSigTimeoutTime_BSM2" SG_ 2654486670 CBV_bit0_RepeatMessageRequestBit 0;
BA_ "GenSigTimeoutTime_CADM2" SG_ 2654486670 CBV_bit0_RepeatMessageRequestBit 0;
BA_ "GenSigTimeoutTime_CVADAS" SG_ 2654486670 CBV_bit0_RepeatMessageRequestBit 0;
BA_ "GenSigTimeoutTime_EPS" SG_ 2654486670 CBV_bit0_RepeatMessageRequestBit 0;
BA_ "GenSigTimeoutTime_ORC" SG_ 2654486670 CBV_bit0_RepeatMessageRequestBit 0;
BA_ "GenSigTimeoutTime_PAM" SG_ 2654486670 CBV_bit0_RepeatMessageRequestBit 0;
BA_ "GenSigTimeoutTime_SGW" SG_ 2654486670 CBV_bit0_RepeatMessageRequestBit 0;
BA_ "GenSigTimeoutTime_TRSKM" SG_ 2654486670 CBV_bit0_RepeatMessageRequestBit 0;
BA_ "GenSigTimeoutTime_BCM" SG_ 2654486670 CBV_bit1 0;
BA_ "GenSigTimeoutTime_BSM2" SG_ 2654486670 CBV_bit1 0;
BA_ "GenSigTimeoutTime_CADM2" SG_ 2654486670 CBV_bit1 0;
BA_ "GenSigTimeoutTime_CVADAS" SG_ 2654486670 CBV_bit1 0;
BA_ "GenSigTimeoutTime_EPS" SG_ 2654486670 CBV_bit1 0;
BA_ "GenSigTimeoutTime_ORC" SG_ 2654486670 CBV_bit1 0;
BA_ "GenSigTimeoutTime_PAM" SG_ 2654486670 CBV_bit1 0;
BA_ "GenSigTimeoutTime_SGW" SG_ 2654486670 CBV_bit1 0;
BA_ "GenSigTimeoutTime_TRSKM" SG_ 2654486670 CBV_bit1 0;
BA_ "GenSigTimeoutTime_BCM" SG_ 2654486670 CBV_bit2 0;
BA_ "GenSigTimeoutTime_BSM2" SG_ 2654486670 CBV_bit2 0;
BA_ "GenSigTimeoutTime_CADM2" SG_ 2654486670 CBV_bit2 0;
BA_ "GenSigTimeoutTime_CVADAS" SG_ 2654486670 CBV_bit2 0;
BA_ "GenSigTimeoutTime_EPS" SG_ 2654486670 CBV_bit2 0;
BA_ "GenSigTimeoutTime_ORC" SG_ 2654486670 CBV_bit2 0;
BA_ "GenSigTimeoutTime_PAM" SG_ 2654486670 CBV_bit2 0;
BA_ "GenSigTimeoutTime_SGW" SG_ 2654486670 CBV_bit2 0;
BA_ "GenSigTimeoutTime_TRSKM" SG_ 2654486670 CBV_bit2 0;
BA_ "GenSigTimeoutTime_BCM" SG_ 2654486670 CBV_bit3_NMCoordinatorBit 0;
BA_ "GenSigTimeoutTime_BSM2" SG_ 2654486670 CBV_bit3_NMCoordinatorBit 0;
BA_ "GenSigTimeoutTime_CADM2" SG_ 2654486670 CBV_bit3_NMCoordinatorBit 0;
BA_ "GenSigTimeoutTime_CVADAS" SG_ 2654486670 CBV_bit3_NMCoordinatorBit 0;
BA_ "GenSigTimeoutTime_EPS" SG_ 2654486670 CBV_bit3_NMCoordinatorBit 0;
BA_ "GenSigTimeoutTime_ORC" SG_ 2654486670 CBV_bit3_NMCoordinatorBit 0;
BA_ "GenSigTimeoutTime_PAM" SG_ 2654486670 CBV_bit3_NMCoordinatorBit 0;
BA_ "GenSigTimeoutTime_SGW" SG_ 2654486670 CBV_bit3_NMCoordinatorBit 0;
BA_ "GenSigTimeoutTime_TRSKM" SG_ 2654486670 CBV_bit3_NMCoordinatorBit 0;
BA_ "GenSigTimeoutTime_BCM" SG_ 2654486670 CBV_bit4_ActiveWakeupBit 0;
BA_ "GenSigTimeoutTime_BSM2" SG_ 2654486670 CBV_bit4_ActiveWakeupBit 0;
BA_ "GenSigTimeoutTime_CADM2" SG_ 2654486670 CBV_bit4_ActiveWakeupBit 0;
BA_ "GenSigTimeoutTime_CVADAS" SG_ 2654486670 CBV_bit4_ActiveWakeupBit 0;
BA_ "GenSigTimeoutTime_EPS" SG_ 2654486670 CBV_bit4_ActiveWakeupBit 0;
BA_ "GenSigTimeoutTime_ORC" SG_ 2654486670 CBV_bit4_ActiveWakeupBit 0;
BA_ "GenSigTimeoutTime_PAM" SG_ 2654486670 CBV_bit4_ActiveWakeupBit 0;
BA_ "GenSigTimeoutTime_SGW" SG_ 2654486670 CBV_bit4_ActiveWakeupBit 0;
BA_ "GenSigTimeoutTime_TRSKM" SG_ 2654486670 CBV_bit4_ActiveWakeupBit 0;
BA_ "GenSigTimeoutTime_BCM" SG_ 2654486670 CBV_bit5 0;
BA_ "GenSigTimeoutTime_BSM2" SG_ 2654486670 CBV_bit5 0;
BA_ "GenSigTimeoutTime_CADM2" SG_ 2654486670 CBV_bit5 0;
BA_ "GenSigTimeoutTime_CVADAS" SG_ 2654486670 CBV_bit5 0;
BA_ "GenSigTimeoutTime_EPS" SG_ 2654486670 CBV_bit5 0;
BA_ "GenSigTimeoutTime_ORC" SG_ 2654486670 CBV_bit5 0;
BA_ "GenSigTimeoutTime_PAM" SG_ 2654486670 CBV_bit5 0;
BA_ "GenSigTimeoutTime_SGW" SG_ 2654486670 CBV_bit5 0;
BA_ "GenSigTimeoutTime_TRSKM" SG_ 2654486670 CBV_bit5 0;
BA_ "GenSigTimeoutTime_BCM" SG_ 2654486670 CBV_bit6_PartialNtwInfBit 0;
BA_ "GenSigTimeoutTime_BSM2" SG_ 2654486670 CBV_bit6_PartialNtwInfBit 0;
BA_ "GenSigTimeoutTime_CADM2" SG_ 2654486670 CBV_bit6_PartialNtwInfBit 0;
BA_ "GenSigTimeoutTime_CVADAS" SG_ 2654486670 CBV_bit6_PartialNtwInfBit 0;
BA_ "GenSigTimeoutTime_EPS" SG_ 2654486670 CBV_bit6_PartialNtwInfBit 0;
BA_ "GenSigTimeoutTime_ORC" SG_ 2654486670 CBV_bit6_PartialNtwInfBit 0;
BA_ "GenSigTimeoutTime_PAM" SG_ 2654486670 CBV_bit6_PartialNtwInfBit 0;
BA_ "GenSigTimeoutTime_SGW" SG_ 2654486670 CBV_bit6_PartialNtwInfBit 0;
BA_ "GenSigTimeoutTime_TRSKM" SG_ 2654486670 CBV_bit6_PartialNtwInfBit 0;
BA_ "GenSigTimeoutTime_BCM" SG_ 2654486670 CBV_bit7 0;
BA_ "GenSigTimeoutTime_BSM2" SG_ 2654486670 CBV_bit7 0;
BA_ "GenSigTimeoutTime_CADM2" SG_ 2654486670 CBV_bit7 0;
BA_ "GenSigTimeoutTime_CVADAS" SG_ 2654486670 CBV_bit7 0;
BA_ "GenSigTimeoutTime_EPS" SG_ 2654486670 CBV_bit7 0;
BA_ "GenSigTimeoutTime_ORC" SG_ 2654486670 CBV_bit7 0;
BA_ "GenSigTimeoutTime_PAM" SG_ 2654486670 CBV_bit7 0;
BA_ "GenSigTimeoutTime_SGW" SG_ 2654486670 CBV_bit7 0;
BA_ "GenSigTimeoutTime_TRSKM" SG_ 2654486670 CBV_bit7 0;
BA_ "GenSigTimeoutTime_BCM" SG_ 2654486670 SourceNodeIdentifier 0;
BA_ "GenSigTimeoutTime_BSM2" SG_ 2654486670 SourceNodeIdentifier 0;
BA_ "GenSigTimeoutTime_CADM2" SG_ 2654486670 SourceNodeIdentifier 0;
BA_ "GenSigTimeoutTime_CVADAS" SG_ 2654486670 SourceNodeIdentifier 0;
BA_ "GenSigTimeoutTime_EPS" SG_ 2654486670 SourceNodeIdentifier 0;
BA_ "GenSigTimeoutTime_ORC" SG_ 2654486670 SourceNodeIdentifier 0;
BA_ "GenSigTimeoutTime_PAM" SG_ 2654486670 SourceNodeIdentifier 0;
BA_ "GenSigTimeoutTime_SGW" SG_ 2654486670 SourceNodeIdentifier 0;
BA_ "GenSigTimeoutTime_TRSKM" SG_ 2654486670 SourceNodeIdentifier 0;
BA_ "GenSigTimeoutTime_BCM" SG_ 2654486530 CBV_bit0_RepeatMessageRequestBit 0;
BA_ "GenSigTimeoutTime_BSM2" SG_ 2654486530 CBV_bit0_RepeatMessageRequestBit 0;
BA_ "GenSigTimeoutTime_CADM2" SG_ 2654486530 CBV_bit0_RepeatMessageRequestBit 0;
BA_ "GenSigTimeoutTime_CVADAS" SG_ 2654486530 CBV_bit0_RepeatMessageRequestBit 0;
BA_ "GenSigTimeoutTime_EPS" SG_ 2654486530 CBV_bit0_RepeatMessageRequestBit 0;
BA_ "GenSigTimeoutTime_ORC" SG_ 2654486530 CBV_bit0_RepeatMessageRequestBit 0;
BA_ "GenSigTimeoutTime_PAM" SG_ 2654486530 CBV_bit0_RepeatMessageRequestBit 0;
BA_ "GenSigTimeoutTime_SGW" SG_ 2654486530 CBV_bit0_RepeatMessageRequestBit 0;
BA_ "GenSigTimeoutTime_TRSKM" SG_ 2654486530 CBV_bit0_RepeatMessageRequestBit 0;
BA_ "GenSigTimeoutTime_BCM" SG_ 2654486530 CBV_bit1 0;
BA_ "GenSigTimeoutTime_BSM2" SG_ 2654486530 CBV_bit1 0;
BA_ "GenSigTimeoutTime_CADM2" SG_ 2654486530 CBV_bit1 0;
BA_ "GenSigTimeoutTime_CVADAS" SG_ 2654486530 CBV_bit1 0;
BA_ "GenSigTimeoutTime_EPS" SG_ 2654486530 CBV_bit1 0;
BA_ "GenSigTimeoutTime_ORC" SG_ 2654486530 CBV_bit1 0;
BA_ "GenSigTimeoutTime_PAM" SG_ 2654486530 CBV_bit1 0;
BA_ "GenSigTimeoutTime_SGW" SG_ 2654486530 CBV_bit1 0;
BA_ "GenSigTimeoutTime_TRSKM" SG_ 2654486530 CBV_bit1 0;
BA_ "GenSigTimeoutTime_BCM" SG_ 2654486530 CBV_bit2 0;
BA_ "GenSigTimeoutTime_BSM2" SG_ 2654486530 CBV_bit2 0;
BA_ "GenSigTimeoutTime_CADM2" SG_ 2654486530 CBV_bit2 0;
BA_ "GenSigTimeoutTime_CVADAS" SG_ 2654486530 CBV_bit2 0;
BA_ "GenSigTimeoutTime_EPS" SG_ 2654486530 CBV_bit2 0;
BA_ "GenSigTimeoutTime_ORC" SG_ 2654486530 CBV_bit2 0;
BA_ "GenSigTimeoutTime_PAM" SG_ 2654486530 CBV_bit2 0;
BA_ "GenSigTimeoutTime_SGW" SG_ 2654486530 CBV_bit2 0;
BA_ "GenSigTimeoutTime_TRSKM" SG_ 2654486530 CBV_bit2 0;
BA_ "GenSigTimeoutTime_BCM" SG_ 2654486530 CBV_bit3_NMCoordinatorBit 0;
BA_ "GenSigTimeoutTime_BSM2" SG_ 2654486530 CBV_bit3_NMCoordinatorBit 0;
BA_ "GenSigTimeoutTime_CADM2" SG_ 2654486530 CBV_bit3_NMCoordinatorBit 0;
BA_ "GenSigTimeoutTime_CVADAS" SG_ 2654486530 CBV_bit3_NMCoordinatorBit 0;
BA_ "GenSigTimeoutTime_EPS" SG_ 2654486530 CBV_bit3_NMCoordinatorBit 0;
BA_ "GenSigTimeoutTime_ORC" SG_ 2654486530 CBV_bit3_NMCoordinatorBit 0;
BA_ "GenSigTimeoutTime_PAM" SG_ 2654486530 CBV_bit3_NMCoordinatorBit 0;
BA_ "GenSigTimeoutTime_SGW" SG_ 2654486530 CBV_bit3_NMCoordinatorBit 0;
BA_ "GenSigTimeoutTime_TRSKM" SG_ 2654486530 CBV_bit3_NMCoordinatorBit 0;
BA_ "GenSigTimeoutTime_BCM" SG_ 2654486530 CBV_bit4_ActiveWakeupBit 0;
BA_ "GenSigTimeoutTime_BSM2" SG_ 2654486530 CBV_bit4_ActiveWakeupBit 0;
BA_ "GenSigTimeoutTime_CADM2" SG_ 2654486530 CBV_bit4_ActiveWakeupBit 0;
BA_ "GenSigTimeoutTime_CVADAS" SG_ 2654486530 CBV_bit4_ActiveWakeupBit 0;
BA_ "GenSigTimeoutTime_EPS" SG_ 2654486530 CBV_bit4_ActiveWakeupBit 0;
BA_ "GenSigTimeoutTime_ORC" SG_ 2654486530 CBV_bit4_ActiveWakeupBit 0;
BA_ "GenSigTimeoutTime_PAM" SG_ 2654486530 CBV_bit4_ActiveWakeupBit 0;
BA_ "GenSigTimeoutTime_SGW" SG_ 2654486530 CBV_bit4_ActiveWakeupBit 0;
BA_ "GenSigTimeoutTime_TRSKM" SG_ 2654486530 CBV_bit4_ActiveWakeupBit 0;
BA_ "GenSigTimeoutTime_BCM" SG_ 2654486530 CBV_bit5 0;
BA_ "GenSigTimeoutTime_BSM2" SG_ 2654486530 CBV_bit5 0;
BA_ "GenSigTimeoutTime_CADM2" SG_ 2654486530 CBV_bit5 0;
BA_ "GenSigTimeoutTime_CVADAS" SG_ 2654486530 CBV_bit5 0;
BA_ "GenSigTimeoutTime_EPS" SG_ 2654486530 CBV_bit5 0;
BA_ "GenSigTimeoutTime_ORC" SG_ 2654486530 CBV_bit5 0;
BA_ "GenSigTimeoutTime_PAM" SG_ 2654486530 CBV_bit5 0;
BA_ "GenSigTimeoutTime_SGW" SG_ 2654486530 CBV_bit5 0;
BA_ "GenSigTimeoutTime_TRSKM" SG_ 2654486530 CBV_bit5 0;
BA_ "GenSigTimeoutTime_BCM" SG_ 2654486530 CBV_bit6_PartialNtwInfBit 0;
BA_ "GenSigTimeoutTime_BSM2" SG_ 2654486530 CBV_bit6_PartialNtwInfBit 0;
BA_ "GenSigTimeoutTime_CADM2" SG_ 2654486530 CBV_bit6_PartialNtwInfBit 0;
BA_ "GenSigTimeoutTime_CVADAS" SG_ 2654486530 CBV_bit6_PartialNtwInfBit 0;
BA_ "GenSigTimeoutTime_EPS" SG_ 2654486530 CBV_bit6_PartialNtwInfBit 0;
BA_ "GenSigTimeoutTime_ORC" SG_ 2654486530 CBV_bit6_PartialNtwInfBit 0;
BA_ "GenSigTimeoutTime_PAM" SG_ 2654486530 CBV_bit6_PartialNtwInfBit 0;
BA_ "GenSigTimeoutTime_SGW" SG_ 2654486530 CBV_bit6_PartialNtwInfBit 0;
BA_ "GenSigTimeoutTime_TRSKM" SG_ 2654486530 CBV_bit6_PartialNtwInfBit 0;
BA_ "GenSigTimeoutTime_BCM" SG_ 2654486530 CBV_bit7 0;
BA_ "GenSigTimeoutTime_BSM2" SG_ 2654486530 CBV_bit7 0;
BA_ "GenSigTimeoutTime_CADM2" SG_ 2654486530 CBV_bit7 0;
BA_ "GenSigTimeoutTime_CVADAS" SG_ 2654486530 CBV_bit7 0;
BA_ "GenSigTimeoutTime_EPS" SG_ 2654486530 CBV_bit7 0;
BA_ "GenSigTimeoutTime_ORC" SG_ 2654486530 CBV_bit7 0;
BA_ "GenSigTimeoutTime_PAM" SG_ 2654486530 CBV_bit7 0;
BA_ "GenSigTimeoutTime_SGW" SG_ 2654486530 CBV_bit7 0;
BA_ "GenSigTimeoutTime_TRSKM" SG_ 2654486530 CBV_bit7 0;
BA_ "GenSigTimeoutTime_BCM" SG_ 2654486530 SourceNodeIdentifier 0;
BA_ "GenSigTimeoutTime_BSM2" SG_ 2654486530 SourceNodeIdentifier 0;
BA_ "GenSigTimeoutTime_CADM2" SG_ 2654486530 SourceNodeIdentifier 0;
BA_ "GenSigTimeoutTime_CVADAS" SG_ 2654486530 SourceNodeIdentifier 0;
BA_ "GenSigTimeoutTime_EPS" SG_ 2654486530 SourceNodeIdentifier 0;
BA_ "GenSigTimeoutTime_ORC" SG_ 2654486530 SourceNodeIdentifier 0;
BA_ "GenSigTimeoutTime_PAM" SG_ 2654486530 SourceNodeIdentifier 0;
BA_ "GenSigTimeoutTime_SGW" SG_ 2654486530 SourceNodeIdentifier 0;
BA_ "GenSigTimeoutTime_TRSKM" SG_ 2654486530 SourceNodeIdentifier 0;
BA_ "GenSigTimeoutTime_BCM" SG_ 2654486554 CBV_bit0_RepeatMessageRequestBit 0;
BA_ "GenSigTimeoutTime_BSM2" SG_ 2654486554 CBV_bit0_RepeatMessageRequestBit 0;
BA_ "GenSigTimeoutTime_CADM2" SG_ 2654486554 CBV_bit0_RepeatMessageRequestBit 0;
BA_ "GenSigTimeoutTime_CVADAS" SG_ 2654486554 CBV_bit0_RepeatMessageRequestBit 0;
BA_ "GenSigTimeoutTime_EPS" SG_ 2654486554 CBV_bit0_RepeatMessageRequestBit 0;
BA_ "GenSigTimeoutTime_ORC" SG_ 2654486554 CBV_bit0_RepeatMessageRequestBit 0;
BA_ "GenSigTimeoutTime_PAM" SG_ 2654486554 CBV_bit0_RepeatMessageRequestBit 0;
BA_ "GenSigTimeoutTime_SGW" SG_ 2654486554 CBV_bit0_RepeatMessageRequestBit 0;
BA_ "GenSigTimeoutTime_TRSKM" SG_ 2654486554 CBV_bit0_RepeatMessageRequestBit 0;
BA_ "GenSigTimeoutTime_BCM" SG_ 2654486554 CBV_bit1 0;
BA_ "GenSigTimeoutTime_BSM2" SG_ 2654486554 CBV_bit1 0;
BA_ "GenSigTimeoutTime_CADM2" SG_ 2654486554 CBV_bit1 0;
BA_ "GenSigTimeoutTime_CVADAS" SG_ 2654486554 CBV_bit1 0;
BA_ "GenSigTimeoutTime_EPS" SG_ 2654486554 CBV_bit1 0;
BA_ "GenSigTimeoutTime_ORC" SG_ 2654486554 CBV_bit1 0;
BA_ "GenSigTimeoutTime_PAM" SG_ 2654486554 CBV_bit1 0;
BA_ "GenSigTimeoutTime_SGW" SG_ 2654486554 CBV_bit1 0;
BA_ "GenSigTimeoutTime_TRSKM" SG_ 2654486554 CBV_bit1 0;
BA_ "GenSigTimeoutTime_BCM" SG_ 2654486554 CBV_bit2 0;
BA_ "GenSigTimeoutTime_BSM2" SG_ 2654486554 CBV_bit2 0;
BA_ "GenSigTimeoutTime_CADM2" SG_ 2654486554 CBV_bit2 0;
BA_ "GenSigTimeoutTime_CVADAS" SG_ 2654486554 CBV_bit2 0;
BA_ "GenSigTimeoutTime_EPS" SG_ 2654486554 CBV_bit2 0;
BA_ "GenSigTimeoutTime_ORC" SG_ 2654486554 CBV_bit2 0;
BA_ "GenSigTimeoutTime_PAM" SG_ 2654486554 CBV_bit2 0;
BA_ "GenSigTimeoutTime_SGW" SG_ 2654486554 CBV_bit2 0;
BA_ "GenSigTimeoutTime_TRSKM" SG_ 2654486554 CBV_bit2 0;
BA_ "GenSigTimeoutTime_BCM" SG_ 2654486554 CBV_bit3_NMCoordinatorBit 0;
BA_ "GenSigTimeoutTime_BSM2" SG_ 2654486554 CBV_bit3_NMCoordinatorBit 0;
BA_ "GenSigTimeoutTime_CADM2" SG_ 2654486554 CBV_bit3_NMCoordinatorBit 0;
BA_ "GenSigTimeoutTime_CVADAS" SG_ 2654486554 CBV_bit3_NMCoordinatorBit 0;
BA_ "GenSigTimeoutTime_EPS" SG_ 2654486554 CBV_bit3_NMCoordinatorBit 0;
BA_ "GenSigTimeoutTime_ORC" SG_ 2654486554 CBV_bit3_NMCoordinatorBit 0;
BA_ "GenSigTimeoutTime_PAM" SG_ 2654486554 CBV_bit3_NMCoordinatorBit 0;
BA_ "GenSigTimeoutTime_SGW" SG_ 2654486554 CBV_bit3_NMCoordinatorBit 0;
BA_ "GenSigTimeoutTime_TRSKM" SG_ 2654486554 CBV_bit3_NMCoordinatorBit 0;
BA_ "GenSigTimeoutTime_BCM" SG_ 2654486554 CBV_bit4_ActiveWakeupBit 0;
BA_ "GenSigTimeoutTime_BSM2" SG_ 2654486554 CBV_bit4_ActiveWakeupBit 0;
BA_ "GenSigTimeoutTime_CADM2" SG_ 2654486554 CBV_bit4_ActiveWakeupBit 0;
BA_ "GenSigTimeoutTime_CVADAS" SG_ 2654486554 CBV_bit4_ActiveWakeupBit 0;
BA_ "GenSigTimeoutTime_EPS" SG_ 2654486554 CBV_bit4_ActiveWakeupBit 0;
BA_ "GenSigTimeoutTime_ORC" SG_ 2654486554 CBV_bit4_ActiveWakeupBit 0;
BA_ "GenSigTimeoutTime_PAM" SG_ 2654486554 CBV_bit4_ActiveWakeupBit 0;
BA_ "GenSigTimeoutTime_SGW" SG_ 2654486554 CBV_bit4_ActiveWakeupBit 0;
BA_ "GenSigTimeoutTime_TRSKM" SG_ 2654486554 CBV_bit4_ActiveWakeupBit 0;
BA_ "GenSigTimeoutTime_BCM" SG_ 2654486554 CBV_bit5 0;
BA_ "GenSigTimeoutTime_BSM2" SG_ 2654486554 CBV_bit5 0;
BA_ "GenSigTimeoutTime_CADM2" SG_ 2654486554 CBV_bit5 0;
BA_ "GenSigTimeoutTime_CVADAS" SG_ 2654486554 CBV_bit5 0;
BA_ "GenSigTimeoutTime_EPS" SG_ 2654486554 CBV_bit5 0;
BA_ "GenSigTimeoutTime_ORC" SG_ 2654486554 CBV_bit5 0;
BA_ "GenSigTimeoutTime_PAM" SG_ 2654486554 CBV_bit5 0;
BA_ "GenSigTimeoutTime_SGW" SG_ 2654486554 CBV_bit5 0;
BA_ "GenSigTimeoutTime_TRSKM" SG_ 2654486554 CBV_bit5 0;
BA_ "GenSigTimeoutTime_BCM" SG_ 2654486554 CBV_bit6_PartialNtwInfBit 0;
BA_ "GenSigTimeoutTime_BSM2" SG_ 2654486554 CBV_bit6_PartialNtwInfBit 0;
BA_ "GenSigTimeoutTime_CADM2" SG_ 2654486554 CBV_bit6_PartialNtwInfBit 0;
BA_ "GenSigTimeoutTime_CVADAS" SG_ 2654486554 CBV_bit6_PartialNtwInfBit 0;
BA_ "GenSigTimeoutTime_EPS" SG_ 2654486554 CBV_bit6_PartialNtwInfBit 0;
BA_ "GenSigTimeoutTime_ORC" SG_ 2654486554 CBV_bit6_PartialNtwInfBit 0;
BA_ "GenSigTimeoutTime_PAM" SG_ 2654486554 CBV_bit6_PartialNtwInfBit 0;
BA_ "GenSigTimeoutTime_SGW" SG_ 2654486554 CBV_bit6_PartialNtwInfBit 0;
BA_ "GenSigTimeoutTime_TRSKM" SG_ 2654486554 CBV_bit6_PartialNtwInfBit 0;
BA_ "GenSigTimeoutTime_BCM" SG_ 2654486554 CBV_bit7 0;
BA_ "GenSigTimeoutTime_BSM2" SG_ 2654486554 CBV_bit7 0;
BA_ "GenSigTimeoutTime_CADM2" SG_ 2654486554 CBV_bit7 0;
BA_ "GenSigTimeoutTime_CVADAS" SG_ 2654486554 CBV_bit7 0;
BA_ "GenSigTimeoutTime_EPS" SG_ 2654486554 CBV_bit7 0;
BA_ "GenSigTimeoutTime_ORC" SG_ 2654486554 CBV_bit7 0;
BA_ "GenSigTimeoutTime_PAM" SG_ 2654486554 CBV_bit7 0;
BA_ "GenSigTimeoutTime_SGW" SG_ 2654486554 CBV_bit7 0;
BA_ "GenSigTimeoutTime_TRSKM" SG_ 2654486554 CBV_bit7 0;
BA_ "GenSigTimeoutTime_BCM" SG_ 2654486554 SourceNodeIdentifier 0;
BA_ "GenSigTimeoutTime_BSM2" SG_ 2654486554 SourceNodeIdentifier 0;
BA_ "GenSigTimeoutTime_CADM2" SG_ 2654486554 SourceNodeIdentifier 0;
BA_ "GenSigTimeoutTime_CVADAS" SG_ 2654486554 SourceNodeIdentifier 0;
BA_ "GenSigTimeoutTime_EPS" SG_ 2654486554 SourceNodeIdentifier 0;
BA_ "GenSigTimeoutTime_ORC" SG_ 2654486554 SourceNodeIdentifier 0;
BA_ "GenSigTimeoutTime_PAM" SG_ 2654486554 SourceNodeIdentifier 0;
BA_ "GenSigTimeoutTime_SGW" SG_ 2654486554 SourceNodeIdentifier 0;
BA_ "GenSigTimeoutTime_TRSKM" SG_ 2654486554 SourceNodeIdentifier 0;
BA_ "GenSigTimeoutTime_BCM" SG_ 2654486552 CBV_bit0_RepeatMessageRequestBit 0;
BA_ "GenSigTimeoutTime_BSM2" SG_ 2654486552 CBV_bit0_RepeatMessageRequestBit 0;
BA_ "GenSigTimeoutTime_CADM2" SG_ 2654486552 CBV_bit0_RepeatMessageRequestBit 0;
BA_ "GenSigTimeoutTime_CVADAS" SG_ 2654486552 CBV_bit0_RepeatMessageRequestBit 0;
BA_ "GenSigTimeoutTime_EPS" SG_ 2654486552 CBV_bit0_RepeatMessageRequestBit 0;
BA_ "GenSigTimeoutTime_ORC" SG_ 2654486552 CBV_bit0_RepeatMessageRequestBit 0;
BA_ "GenSigTimeoutTime_PAM" SG_ 2654486552 CBV_bit0_RepeatMessageRequestBit 0;
BA_ "GenSigTimeoutTime_SGW" SG_ 2654486552 CBV_bit0_RepeatMessageRequestBit 0;
BA_ "GenSigTimeoutTime_TRSKM" SG_ 2654486552 CBV_bit0_RepeatMessageRequestBit 0;
BA_ "GenSigTimeoutTime_BCM" SG_ 2654486552 CBV_bit1 0;
BA_ "GenSigTimeoutTime_BSM2" SG_ 2654486552 CBV_bit1 0;
BA_ "GenSigTimeoutTime_CADM2" SG_ 2654486552 CBV_bit1 0;
BA_ "GenSigTimeoutTime_CVADAS" SG_ 2654486552 CBV_bit1 0;
BA_ "GenSigTimeoutTime_EPS" SG_ 2654486552 CBV_bit1 0;
BA_ "GenSigTimeoutTime_ORC" SG_ 2654486552 CBV_bit1 0;
BA_ "GenSigTimeoutTime_PAM" SG_ 2654486552 CBV_bit1 0;
BA_ "GenSigTimeoutTime_SGW" SG_ 2654486552 CBV_bit1 0;
BA_ "GenSigTimeoutTime_TRSKM" SG_ 2654486552 CBV_bit1 0;
BA_ "GenSigTimeoutTime_BCM" SG_ 2654486552 CBV_bit2 0;
BA_ "GenSigTimeoutTime_BSM2" SG_ 2654486552 CBV_bit2 0;
BA_ "GenSigTimeoutTime_CADM2" SG_ 2654486552 CBV_bit2 0;
BA_ "GenSigTimeoutTime_CVADAS" SG_ 2654486552 CBV_bit2 0;
BA_ "GenSigTimeoutTime_EPS" SG_ 2654486552 CBV_bit2 0;
BA_ "GenSigTimeoutTime_ORC" SG_ 2654486552 CBV_bit2 0;
BA_ "GenSigTimeoutTime_PAM" SG_ 2654486552 CBV_bit2 0;
BA_ "GenSigTimeoutTime_SGW" SG_ 2654486552 CBV_bit2 0;
BA_ "GenSigTimeoutTime_TRSKM" SG_ 2654486552 CBV_bit2 0;
BA_ "GenSigTimeoutTime_BCM" SG_ 2654486552 CBV_bit3_NMCoordinatorBit 0;
BA_ "GenSigTimeoutTime_BSM2" SG_ 2654486552 CBV_bit3_NMCoordinatorBit 0;
BA_ "GenSigTimeoutTime_CADM2" SG_ 2654486552 CBV_bit3_NMCoordinatorBit 0;
BA_ "GenSigTimeoutTime_CVADAS" SG_ 2654486552 CBV_bit3_NMCoordinatorBit 0;
BA_ "GenSigTimeoutTime_EPS" SG_ 2654486552 CBV_bit3_NMCoordinatorBit 0;
BA_ "GenSigTimeoutTime_ORC" SG_ 2654486552 CBV_bit3_NMCoordinatorBit 0;
BA_ "GenSigTimeoutTime_PAM" SG_ 2654486552 CBV_bit3_NMCoordinatorBit 0;
BA_ "GenSigTimeoutTime_SGW" SG_ 2654486552 CBV_bit3_NMCoordinatorBit 0;
BA_ "GenSigTimeoutTime_TRSKM" SG_ 2654486552 CBV_bit3_NMCoordinatorBit 0;
BA_ "GenSigTimeoutTime_BCM" SG_ 2654486552 CBV_bit4_ActiveWakeupBit 0;
BA_ "GenSigTimeoutTime_BSM2" SG_ 2654486552 CBV_bit4_ActiveWakeupBit 0;
BA_ "GenSigTimeoutTime_CADM2" SG_ 2654486552 CBV_bit4_ActiveWakeupBit 0;
BA_ "GenSigTimeoutTime_CVADAS" SG_ 2654486552 CBV_bit4_ActiveWakeupBit 0;
BA_ "GenSigTimeoutTime_EPS" SG_ 2654486552 CBV_bit4_ActiveWakeupBit 0;
BA_ "GenSigTimeoutTime_ORC" SG_ 2654486552 CBV_bit4_ActiveWakeupBit 0;
BA_ "GenSigTimeoutTime_PAM" SG_ 2654486552 CBV_bit4_ActiveWakeupBit 0;
BA_ "GenSigTimeoutTime_SGW" SG_ 2654486552 CBV_bit4_ActiveWakeupBit 0;
BA_ "GenSigTimeoutTime_TRSKM" SG_ 2654486552 CBV_bit4_ActiveWakeupBit 0;
BA_ "GenSigTimeoutTime_BCM" SG_ 2654486552 CBV_bit5 0;
BA_ "GenSigTimeoutTime_BSM2" SG_ 2654486552 CBV_bit5 0;
BA_ "GenSigTimeoutTime_CADM2" SG_ 2654486552 CBV_bit5 0;
BA_ "GenSigTimeoutTime_CVADAS" SG_ 2654486552 CBV_bit5 0;
BA_ "GenSigTimeoutTime_EPS" SG_ 2654486552 CBV_bit5 0;
BA_ "GenSigTimeoutTime_ORC" SG_ 2654486552 CBV_bit5 0;
BA_ "GenSigTimeoutTime_PAM" SG_ 2654486552 CBV_bit5 0;
BA_ "GenSigTimeoutTime_SGW" SG_ 2654486552 CBV_bit5 0;
BA_ "GenSigTimeoutTime_TRSKM" SG_ 2654486552 CBV_bit5 0;
BA_ "GenSigTimeoutTime_BCM" SG_ 2654486552 CBV_bit6_PartialNtwInfBit 0;
BA_ "GenSigTimeoutTime_BSM2" SG_ 2654486552 CBV_bit6_PartialNtwInfBit 0;
BA_ "GenSigTimeoutTime_CADM2" SG_ 2654486552 CBV_bit6_PartialNtwInfBit 0;
BA_ "GenSigTimeoutTime_CVADAS" SG_ 2654486552 CBV_bit6_PartialNtwInfBit 0;
BA_ "GenSigTimeoutTime_EPS" SG_ 2654486552 CBV_bit6_PartialNtwInfBit 0;
BA_ "GenSigTimeoutTime_ORC" SG_ 2654486552 CBV_bit6_PartialNtwInfBit 0;
BA_ "GenSigTimeoutTime_PAM" SG_ 2654486552 CBV_bit6_PartialNtwInfBit 0;
BA_ "GenSigTimeoutTime_SGW" SG_ 2654486552 CBV_bit6_PartialNtwInfBit 0;
BA_ "GenSigTimeoutTime_TRSKM" SG_ 2654486552 CBV_bit6_PartialNtwInfBit 0;
BA_ "GenSigTimeoutTime_BCM" SG_ 2654486552 CBV_bit7 0;
BA_ "GenSigTimeoutTime_BSM2" SG_ 2654486552 CBV_bit7 0;
BA_ "GenSigTimeoutTime_CADM2" SG_ 2654486552 CBV_bit7 0;
BA_ "GenSigTimeoutTime_CVADAS" SG_ 2654486552 CBV_bit7 0;
BA_ "GenSigTimeoutTime_EPS" SG_ 2654486552 CBV_bit7 0;
BA_ "GenSigTimeoutTime_ORC" SG_ 2654486552 CBV_bit7 0;
BA_ "GenSigTimeoutTime_PAM" SG_ 2654486552 CBV_bit7 0;
BA_ "GenSigTimeoutTime_SGW" SG_ 2654486552 CBV_bit7 0;
BA_ "GenSigTimeoutTime_TRSKM" SG_ 2654486552 CBV_bit7 0;
BA_ "GenSigTimeoutTime_BCM" SG_ 2654486552 SourceNodeIdentifier 0;
BA_ "GenSigTimeoutTime_BSM2" SG_ 2654486552 SourceNodeIdentifier 0;
BA_ "GenSigTimeoutTime_CADM2" SG_ 2654486552 SourceNodeIdentifier 0;
BA_ "GenSigTimeoutTime_CVADAS" SG_ 2654486552 SourceNodeIdentifier 0;
BA_ "GenSigTimeoutTime_EPS" SG_ 2654486552 SourceNodeIdentifier 0;
BA_ "GenSigTimeoutTime_ORC" SG_ 2654486552 SourceNodeIdentifier 0;
BA_ "GenSigTimeoutTime_PAM" SG_ 2654486552 SourceNodeIdentifier 0;
BA_ "GenSigTimeoutTime_SGW" SG_ 2654486552 SourceNodeIdentifier 0;
BA_ "GenSigTimeoutTime_TRSKM" SG_ 2654486552 SourceNodeIdentifier 0;
BA_ "GenSigTimeoutTime_BCM" SG_ 2654486640 CBV_bit0_RepeatMessageRequestBit 0;
BA_ "GenSigTimeoutTime_BSM2" SG_ 2654486640 CBV_bit0_RepeatMessageRequestBit 0;
BA_ "GenSigTimeoutTime_CADM2" SG_ 2654486640 CBV_bit0_RepeatMessageRequestBit 0;
BA_ "GenSigTimeoutTime_CVADAS" SG_ 2654486640 CBV_bit0_RepeatMessageRequestBit 0;
BA_ "GenSigTimeoutTime_EPS" SG_ 2654486640 CBV_bit0_RepeatMessageRequestBit 0;
BA_ "GenSigTimeoutTime_ORC" SG_ 2654486640 CBV_bit0_RepeatMessageRequestBit 0;
BA_ "GenSigTimeoutTime_PAM" SG_ 2654486640 CBV_bit0_RepeatMessageRequestBit 0;
BA_ "GenSigTimeoutTime_SGW" SG_ 2654486640 CBV_bit0_RepeatMessageRequestBit 0;
BA_ "GenSigTimeoutTime_TRSKM" SG_ 2654486640 CBV_bit0_RepeatMessageRequestBit 0;
BA_ "GenSigTimeoutTime_BCM" SG_ 2654486640 CBV_bit1 0;
BA_ "GenSigTimeoutTime_BSM2" SG_ 2654486640 CBV_bit1 0;
BA_ "GenSigTimeoutTime_CADM2" SG_ 2654486640 CBV_bit1 0;
BA_ "GenSigTimeoutTime_CVADAS" SG_ 2654486640 CBV_bit1 0;
BA_ "GenSigTimeoutTime_EPS" SG_ 2654486640 CBV_bit1 0;
BA_ "GenSigTimeoutTime_ORC" SG_ 2654486640 CBV_bit1 0;
BA_ "GenSigTimeoutTime_PAM" SG_ 2654486640 CBV_bit1 0;
BA_ "GenSigTimeoutTime_SGW" SG_ 2654486640 CBV_bit1 0;
BA_ "GenSigTimeoutTime_TRSKM" SG_ 2654486640 CBV_bit1 0;
BA_ "GenSigTimeoutTime_BCM" SG_ 2654486640 CBV_bit2 0;
BA_ "GenSigTimeoutTime_BSM2" SG_ 2654486640 CBV_bit2 0;
BA_ "GenSigTimeoutTime_CADM2" SG_ 2654486640 CBV_bit2 0;
BA_ "GenSigTimeoutTime_CVADAS" SG_ 2654486640 CBV_bit2 0;
BA_ "GenSigTimeoutTime_EPS" SG_ 2654486640 CBV_bit2 0;
BA_ "GenSigTimeoutTime_ORC" SG_ 2654486640 CBV_bit2 0;
BA_ "GenSigTimeoutTime_PAM" SG_ 2654486640 CBV_bit2 0;
BA_ "GenSigTimeoutTime_SGW" SG_ 2654486640 CBV_bit2 0;
BA_ "GenSigTimeoutTime_TRSKM" SG_ 2654486640 CBV_bit2 0;
BA_ "GenSigTimeoutTime_BCM" SG_ 2654486640 CBV_bit3_NMCoordinatorBit 0;
BA_ "GenSigTimeoutTime_BSM2" SG_ 2654486640 CBV_bit3_NMCoordinatorBit 0;
BA_ "GenSigTimeoutTime_CADM2" SG_ 2654486640 CBV_bit3_NMCoordinatorBit 0;
BA_ "GenSigTimeoutTime_CVADAS" SG_ 2654486640 CBV_bit3_NMCoordinatorBit 0;
BA_ "GenSigTimeoutTime_EPS" SG_ 2654486640 CBV_bit3_NMCoordinatorBit 0;
BA_ "GenSigTimeoutTime_ORC" SG_ 2654486640 CBV_bit3_NMCoordinatorBit 0;
BA_ "GenSigTimeoutTime_PAM" SG_ 2654486640 CBV_bit3_NMCoordinatorBit 0;
BA_ "GenSigTimeoutTime_SGW" SG_ 2654486640 CBV_bit3_NMCoordinatorBit 0;
BA_ "GenSigTimeoutTime_TRSKM" SG_ 2654486640 CBV_bit3_NMCoordinatorBit 0;
BA_ "GenSigTimeoutTime_BCM" SG_ 2654486640 CBV_bit4_ActiveWakeupBit 0;
BA_ "GenSigTimeoutTime_BSM2" SG_ 2654486640 CBV_bit4_ActiveWakeupBit 0;
BA_ "GenSigTimeoutTime_CADM2" SG_ 2654486640 CBV_bit4_ActiveWakeupBit 0;
BA_ "GenSigTimeoutTime_CVADAS" SG_ 2654486640 CBV_bit4_ActiveWakeupBit 0;
BA_ "GenSigTimeoutTime_EPS" SG_ 2654486640 CBV_bit4_ActiveWakeupBit 0;
BA_ "GenSigTimeoutTime_ORC" SG_ 2654486640 CBV_bit4_ActiveWakeupBit 0;
BA_ "GenSigTimeoutTime_PAM" SG_ 2654486640 CBV_bit4_ActiveWakeupBit 0;
BA_ "GenSigTimeoutTime_SGW" SG_ 2654486640 CBV_bit4_ActiveWakeupBit 0;
BA_ "GenSigTimeoutTime_TRSKM" SG_ 2654486640 CBV_bit4_ActiveWakeupBit 0;
BA_ "GenSigTimeoutTime_BCM" SG_ 2654486640 CBV_bit5 0;
BA_ "GenSigTimeoutTime_BSM2" SG_ 2654486640 CBV_bit5 0;
BA_ "GenSigTimeoutTime_CADM2" SG_ 2654486640 CBV_bit5 0;
BA_ "GenSigTimeoutTime_CVADAS" SG_ 2654486640 CBV_bit5 0;
BA_ "GenSigTimeoutTime_EPS" SG_ 2654486640 CBV_bit5 0;
BA_ "GenSigTimeoutTime_ORC" SG_ 2654486640 CBV_bit5 0;
BA_ "GenSigTimeoutTime_PAM" SG_ 2654486640 CBV_bit5 0;
BA_ "GenSigTimeoutTime_SGW" SG_ 2654486640 CBV_bit5 0;
BA_ "GenSigTimeoutTime_TRSKM" SG_ 2654486640 CBV_bit5 0;
BA_ "GenSigTimeoutTime_BCM" SG_ 2654486640 CBV_bit6_PartialNtwInfBit 0;
BA_ "GenSigTimeoutTime_BSM2" SG_ 2654486640 CBV_bit6_PartialNtwInfBit 0;
BA_ "GenSigTimeoutTime_CADM2" SG_ 2654486640 CBV_bit6_PartialNtwInfBit 0;
BA_ "GenSigTimeoutTime_CVADAS" SG_ 2654486640 CBV_bit6_PartialNtwInfBit 0;
BA_ "GenSigTimeoutTime_EPS" SG_ 2654486640 CBV_bit6_PartialNtwInfBit 0;
BA_ "GenSigTimeoutTime_ORC" SG_ 2654486640 CBV_bit6_PartialNtwInfBit 0;
BA_ "GenSigTimeoutTime_PAM" SG_ 2654486640 CBV_bit6_PartialNtwInfBit 0;
BA_ "GenSigTimeoutTime_SGW" SG_ 2654486640 CBV_bit6_PartialNtwInfBit 0;
BA_ "GenSigTimeoutTime_TRSKM" SG_ 2654486640 CBV_bit6_PartialNtwInfBit 0;
BA_ "GenSigTimeoutTime_BCM" SG_ 2654486640 CBV_bit7 0;
BA_ "GenSigTimeoutTime_BSM2" SG_ 2654486640 CBV_bit7 0;
BA_ "GenSigTimeoutTime_CADM2" SG_ 2654486640 CBV_bit7 0;
BA_ "GenSigTimeoutTime_CVADAS" SG_ 2654486640 CBV_bit7 0;
BA_ "GenSigTimeoutTime_EPS" SG_ 2654486640 CBV_bit7 0;
BA_ "GenSigTimeoutTime_ORC" SG_ 2654486640 CBV_bit7 0;
BA_ "GenSigTimeoutTime_PAM" SG_ 2654486640 CBV_bit7 0;
BA_ "GenSigTimeoutTime_SGW" SG_ 2654486640 CBV_bit7 0;
BA_ "GenSigTimeoutTime_TRSKM" SG_ 2654486640 CBV_bit7 0;
BA_ "GenSigTimeoutTime_BCM" SG_ 2654486640 SourceNodeIdentifier 0;
BA_ "GenSigTimeoutTime_BSM2" SG_ 2654486640 SourceNodeIdentifier 0;
BA_ "GenSigTimeoutTime_CADM2" SG_ 2654486640 SourceNodeIdentifier 0;
BA_ "GenSigTimeoutTime_CVADAS" SG_ 2654486640 SourceNodeIdentifier 0;
BA_ "GenSigTimeoutTime_EPS" SG_ 2654486640 SourceNodeIdentifier 0;
BA_ "GenSigTimeoutTime_ORC" SG_ 2654486640 SourceNodeIdentifier 0;
BA_ "GenSigTimeoutTime_PAM" SG_ 2654486640 SourceNodeIdentifier 0;
BA_ "GenSigTimeoutTime_SGW" SG_ 2654486640 SourceNodeIdentifier 0;
BA_ "GenSigTimeoutTime_TRSKM" SG_ 2654486640 SourceNodeIdentifier 0;
BA_ "GenSigTimeoutTime_BCM" SG_ 2654486705 CBV_bit0_RepeatMessageRequestBit 0;
BA_ "GenSigTimeoutTime_BSM2" SG_ 2654486705 CBV_bit0_RepeatMessageRequestBit 0;
BA_ "GenSigTimeoutTime_CADM2" SG_ 2654486705 CBV_bit0_RepeatMessageRequestBit 0;
BA_ "GenSigTimeoutTime_CVADAS" SG_ 2654486705 CBV_bit0_RepeatMessageRequestBit 0;
BA_ "GenSigTimeoutTime_EPS" SG_ 2654486705 CBV_bit0_RepeatMessageRequestBit 0;
BA_ "GenSigTimeoutTime_ORC" SG_ 2654486705 CBV_bit0_RepeatMessageRequestBit 0;
BA_ "GenSigTimeoutTime_PAM" SG_ 2654486705 CBV_bit0_RepeatMessageRequestBit 0;
BA_ "GenSigTimeoutTime_SGW" SG_ 2654486705 CBV_bit0_RepeatMessageRequestBit 0;
BA_ "GenSigTimeoutTime_TRSKM" SG_ 2654486705 CBV_bit0_RepeatMessageRequestBit 0;
BA_ "GenSigTimeoutTime_BCM" SG_ 2654486705 CBV_bit1 0;
BA_ "GenSigTimeoutTime_BSM2" SG_ 2654486705 CBV_bit1 0;
BA_ "GenSigTimeoutTime_CADM2" SG_ 2654486705 CBV_bit1 0;
BA_ "GenSigTimeoutTime_CVADAS" SG_ 2654486705 CBV_bit1 0;
BA_ "GenSigTimeoutTime_EPS" SG_ 2654486705 CBV_bit1 0;
BA_ "GenSigTimeoutTime_ORC" SG_ 2654486705 CBV_bit1 0;
BA_ "GenSigTimeoutTime_PAM" SG_ 2654486705 CBV_bit1 0;
BA_ "GenSigTimeoutTime_SGW" SG_ 2654486705 CBV_bit1 0;
BA_ "GenSigTimeoutTime_TRSKM" SG_ 2654486705 CBV_bit1 0;
BA_ "GenSigTimeoutTime_BCM" SG_ 2654486705 CBV_bit2 0;
BA_ "GenSigTimeoutTime_BSM2" SG_ 2654486705 CBV_bit2 0;
BA_ "GenSigTimeoutTime_CADM2" SG_ 2654486705 CBV_bit2 0;
BA_ "GenSigTimeoutTime_CVADAS" SG_ 2654486705 CBV_bit2 0;
BA_ "GenSigTimeoutTime_EPS" SG_ 2654486705 CBV_bit2 0;
BA_ "GenSigTimeoutTime_ORC" SG_ 2654486705 CBV_bit2 0;
BA_ "GenSigTimeoutTime_PAM" SG_ 2654486705 CBV_bit2 0;
BA_ "GenSigTimeoutTime_SGW" SG_ 2654486705 CBV_bit2 0;
BA_ "GenSigTimeoutTime_TRSKM" SG_ 2654486705 CBV_bit2 0;
BA_ "GenSigTimeoutTime_BCM" SG_ 2654486705 CBV_bit3_NMCoordinatorBit 0;
BA_ "GenSigTimeoutTime_BSM2" SG_ 2654486705 CBV_bit3_NMCoordinatorBit 0;
BA_ "GenSigTimeoutTime_CADM2" SG_ 2654486705 CBV_bit3_NMCoordinatorBit 0;
BA_ "GenSigTimeoutTime_CVADAS" SG_ 2654486705 CBV_bit3_NMCoordinatorBit 0;
BA_ "GenSigTimeoutTime_EPS" SG_ 2654486705 CBV_bit3_NMCoordinatorBit 0;
BA_ "GenSigTimeoutTime_ORC" SG_ 2654486705 CBV_bit3_NMCoordinatorBit 0;
BA_ "GenSigTimeoutTime_PAM" SG_ 2654486705 CBV_bit3_NMCoordinatorBit 0;
BA_ "GenSigTimeoutTime_SGW" SG_ 2654486705 CBV_bit3_NMCoordinatorBit 0;
BA_ "GenSigTimeoutTime_TRSKM" SG_ 2654486705 CBV_bit3_NMCoordinatorBit 0;
BA_ "GenSigTimeoutTime_BCM" SG_ 2654486705 CBV_bit4_ActiveWakeupBit 0;
BA_ "GenSigTimeoutTime_BSM2" SG_ 2654486705 CBV_bit4_ActiveWakeupBit 0;
BA_ "GenSigTimeoutTime_CADM2" SG_ 2654486705 CBV_bit4_ActiveWakeupBit 0;
BA_ "GenSigTimeoutTime_CVADAS" SG_ 2654486705 CBV_bit4_ActiveWakeupBit 0;
BA_ "GenSigTimeoutTime_EPS" SG_ 2654486705 CBV_bit4_ActiveWakeupBit 0;
BA_ "GenSigTimeoutTime_ORC" SG_ 2654486705 CBV_bit4_ActiveWakeupBit 0;
BA_ "GenSigTimeoutTime_PAM" SG_ 2654486705 CBV_bit4_ActiveWakeupBit 0;
BA_ "GenSigTimeoutTime_SGW" SG_ 2654486705 CBV_bit4_ActiveWakeupBit 0;
BA_ "GenSigTimeoutTime_TRSKM" SG_ 2654486705 CBV_bit4_ActiveWakeupBit 0;
BA_ "GenSigTimeoutTime_BCM" SG_ 2654486705 CBV_bit5 0;
BA_ "GenSigTimeoutTime_BSM2" SG_ 2654486705 CBV_bit5 0;
BA_ "GenSigTimeoutTime_CADM2" SG_ 2654486705 CBV_bit5 0;
BA_ "GenSigTimeoutTime_CVADAS" SG_ 2654486705 CBV_bit5 0;
BA_ "GenSigTimeoutTime_EPS" SG_ 2654486705 CBV_bit5 0;
BA_ "GenSigTimeoutTime_ORC" SG_ 2654486705 CBV_bit5 0;
BA_ "GenSigTimeoutTime_PAM" SG_ 2654486705 CBV_bit5 0;
BA_ "GenSigTimeoutTime_SGW" SG_ 2654486705 CBV_bit5 0;
BA_ "GenSigTimeoutTime_TRSKM" SG_ 2654486705 CBV_bit5 0;
BA_ "GenSigTimeoutTime_BCM" SG_ 2654486705 CBV_bit6_PartialNtwInfBit 0;
BA_ "GenSigTimeoutTime_BSM2" SG_ 2654486705 CBV_bit6_PartialNtwInfBit 0;
BA_ "GenSigTimeoutTime_CADM2" SG_ 2654486705 CBV_bit6_PartialNtwInfBit 0;
BA_ "GenSigTimeoutTime_CVADAS" SG_ 2654486705 CBV_bit6_PartialNtwInfBit 0;
BA_ "GenSigTimeoutTime_EPS" SG_ 2654486705 CBV_bit6_PartialNtwInfBit 0;
BA_ "GenSigTimeoutTime_ORC" SG_ 2654486705 CBV_bit6_PartialNtwInfBit 0;
BA_ "GenSigTimeoutTime_PAM" SG_ 2654486705 CBV_bit6_PartialNtwInfBit 0;
BA_ "GenSigTimeoutTime_SGW" SG_ 2654486705 CBV_bit6_PartialNtwInfBit 0;
BA_ "GenSigTimeoutTime_TRSKM" SG_ 2654486705 CBV_bit6_PartialNtwInfBit 0;
BA_ "GenSigTimeoutTime_BCM" SG_ 2654486705 CBV_bit7 0;
BA_ "GenSigTimeoutTime_BSM2" SG_ 2654486705 CBV_bit7 0;
BA_ "GenSigTimeoutTime_CADM2" SG_ 2654486705 CBV_bit7 0;
BA_ "GenSigTimeoutTime_CVADAS" SG_ 2654486705 CBV_bit7 0;
BA_ "GenSigTimeoutTime_EPS" SG_ 2654486705 CBV_bit7 0;
BA_ "GenSigTimeoutTime_ORC" SG_ 2654486705 CBV_bit7 0;
BA_ "GenSigTimeoutTime_PAM" SG_ 2654486705 CBV_bit7 0;
BA_ "GenSigTimeoutTime_SGW" SG_ 2654486705 CBV_bit7 0;
BA_ "GenSigTimeoutTime_TRSKM" SG_ 2654486705 CBV_bit7 0;
BA_ "GenSigTimeoutTime_BCM" SG_ 2654486705 SourceNodeIdentifier 0;
BA_ "GenSigTimeoutTime_BSM2" SG_ 2654486705 SourceNodeIdentifier 0;
BA_ "GenSigTimeoutTime_CADM2" SG_ 2654486705 SourceNodeIdentifier 0;
BA_ "GenSigTimeoutTime_CVADAS" SG_ 2654486705 SourceNodeIdentifier 0;
BA_ "GenSigTimeoutTime_EPS" SG_ 2654486705 SourceNodeIdentifier 0;
BA_ "GenSigTimeoutTime_ORC" SG_ 2654486705 SourceNodeIdentifier 0;
BA_ "GenSigTimeoutTime_PAM" SG_ 2654486705 SourceNodeIdentifier 0;
BA_ "GenSigTimeoutTime_SGW" SG_ 2654486705 SourceNodeIdentifier 0;
BA_ "GenSigTimeoutTime_TRSKM" SG_ 2654486705 SourceNodeIdentifier 0;
BA_ "GenSigStartValue" SG_ 611 AirBagFailSts 2;
BA_ "GenSigTimeoutTime_BSM2" SG_ 611 AirBagFailSts 0;
BA_ "GenSigTimeoutTime_CADM2" SG_ 611 AirBagFailSts 0;
BA_ "GenSigTimeoutTime_CVADAS" SG_ 611 AirBagFailSts 0;
BA_ "GenSigTimeoutTime_EPS" SG_ 611 AirBagFailSts 0;
BA_ "GenSigTimeoutTime_ORC" SG_ 611 AirBagFailSts 0;
BA_ "GenSigTimeoutTime_PAM" SG_ 611 AirBagFailSts 0;
BA_ "GenSigTimeoutTime_TRSKM" SG_ 611 AirBagFailSts 0;
BA_ "GenSigTimeoutTime_BSM2" SG_ 611 CRC_ORC1 0;
BA_ "GenSigTimeoutTime_CADM2" SG_ 611 CRC_ORC1 0;
BA_ "GenSigTimeoutTime_CVADAS" SG_ 611 CRC_ORC1 0;
BA_ "GenSigTimeoutTime_EPS" SG_ 611 CRC_ORC1 0;
BA_ "GenSigTimeoutTime_ORC" SG_ 611 CRC_ORC1 0;
BA_ "GenSigTimeoutTime_PAM" SG_ 611 CRC_ORC1 0;
BA_ "GenSigTimeoutTime_SGW" SG_ 611 CRC_ORC1 0;
BA_ "GenSigTimeoutTime_TRSKM" SG_ 611 CRC_ORC1 0;
BA_ "GenSigTimeoutTime_BSM2" SG_ 611 MessageCounter_ORC1 0;
BA_ "GenSigTimeoutTime_CADM2" SG_ 611 MessageCounter_ORC1 0;
BA_ "GenSigTimeoutTime_CVADAS" SG_ 611 MessageCounter_ORC1 0;
BA_ "GenSigTimeoutTime_EPS" SG_ 611 MessageCounter_ORC1 0;
BA_ "GenSigTimeoutTime_ORC" SG_ 611 MessageCounter_ORC1 0;
BA_ "GenSigTimeoutTime_PAM" SG_ 611 MessageCounter_ORC1 0;
BA_ "GenSigTimeoutTime_SGW" SG_ 611 MessageCounter_ORC1 0;
BA_ "GenSigTimeoutTime_TRSKM" SG_ 611 MessageCounter_ORC1 0;
BA_ "GenSigTimeoutTime_BSM2" SG_ 611 SBR1RowDriverSeatConfigSts 0;
BA_ "GenSigTimeoutTime_CADM2" SG_ 611 SBR1RowDriverSeatConfigSts 0;
BA_ "GenSigTimeoutTime_CVADAS" SG_ 611 SBR1RowDriverSeatConfigSts 0;
BA_ "GenSigTimeoutTime_EPS" SG_ 611 SBR1RowDriverSeatConfigSts 0;
BA_ "GenSigTimeoutTime_ORC" SG_ 611 SBR1RowDriverSeatConfigSts 0;
BA_ "GenSigTimeoutTime_PAM" SG_ 611 SBR1RowDriverSeatConfigSts 0;
BA_ "GenSigTimeoutTime_SGW" SG_ 611 SBR1RowDriverSeatConfigSts 0;
BA_ "GenSigTimeoutTime_TRSKM" SG_ 611 SBR1RowDriverSeatConfigSts 0;
BA_ "GenSigStartValue" SG_ 611 SBR1RowDriverSeatSts 3;
BA_ "GenSigSendType" SG_ 611 SBR1RowDriverSeatSts 3;
BA_ "GenSigTimeoutTime_BSM2" SG_ 611 SBR1RowDriverSeatSts 0;
BA_ "GenSigTimeoutTime_CADM2" SG_ 611 SBR1RowDriverSeatSts 0;
BA_ "GenSigTimeoutTime_EPS" SG_ 611 SBR1RowDriverSeatSts 0;
BA_ "GenSigTimeoutTime_ORC" SG_ 611 SBR1RowDriverSeatSts 0;
BA_ "GenSigTimeoutTime_PAM" SG_ 611 SBR1RowDriverSeatSts 0;
BA_ "GenSigTimeoutTime_TRSKM" SG_ 611 SBR1RowDriverSeatSts 0;
BA_ "GenSigTimeoutTime_BSM2" SG_ 611 SBR1RowPsngrSeatConfigSts 0;
BA_ "GenSigTimeoutTime_CADM2" SG_ 611 SBR1RowPsngrSeatConfigSts 0;
BA_ "GenSigTimeoutTime_CVADAS" SG_ 611 SBR1RowPsngrSeatConfigSts 0;
BA_ "GenSigTimeoutTime_EPS" SG_ 611 SBR1RowPsngrSeatConfigSts 0;
BA_ "GenSigTimeoutTime_ORC" SG_ 611 SBR1RowPsngrSeatConfigSts 0;
BA_ "GenSigTimeoutTime_PAM" SG_ 611 SBR1RowPsngrSeatConfigSts 0;
BA_ "GenSigTimeoutTime_TRSKM" SG_ 611 SBR1RowPsngrSeatConfigSts 0;
BA_ "GenSigStartValue" SG_ 611 SBR1RowPsngrSeatSts 7;
BA_ "GenSigSendType" SG_ 611 SBR1RowPsngrSeatSts 3;
BA_ "GenSigTimeoutTime_BSM2" SG_ 611 SBR1RowPsngrSeatSts 0;
BA_ "GenSigTimeoutTime_CADM2" SG_ 611 SBR1RowPsngrSeatSts 0;
BA_ "GenSigTimeoutTime_CVADAS" SG_ 611 SBR1RowPsngrSeatSts 0;
BA_ "GenSigTimeoutTime_EPS" SG_ 611 SBR1RowPsngrSeatSts 0;
BA_ "GenSigTimeoutTime_ORC" SG_ 611 SBR1RowPsngrSeatSts 0;
BA_ "GenSigTimeoutTime_PAM" SG_ 611 SBR1RowPsngrSeatSts 0;
BA_ "GenSigTimeoutTime_TRSKM" SG_ 611 SBR1RowPsngrSeatSts 0;
VAL_ 517 AWDSysStat 0 "SH_IPG" 1 "4LO" 2 "4HI" 3 "2WD" 4 "NEUTRAL" 5 "SYNC_IPG" 6 "4WDLock" 7 "SNA" ;
VAL_ 517 CCMFailSts 0 "FailNotPresent" 1 "FailPresent" ;
VAL_ 517 Ft_RrCouplingTrq_Actual 255 "SNA" ;
VAL_ 1068 TCASERANGESTATUS 0 "HIGH" 1 "NTRL" 2 "LOW" 3 "SNA" ;
VAL_ 576 DriverDoor3AjarRawValSts 0 "Not_Active" 1 "Active" ;
VAL_ 576 DriverDoor4AjarRawValSts 0 "Not_Active" 1 "Active" ;
VAL_ 262 EngineSpeed_W 16383 "SNA" ;
VAL_ 262 EngineSpeedFailSts_W 0 "Fail_not_present" 1 "Fail_present" ;
VAL_ 262 EngineSts_W 0 "Engine_Off" 1 "Engine_Cranking" 2 "Engine_On" 3 "SNA" ;
VAL_ 262 EngTrq_Enbl_Rq_TCM_W 0 "Not_Active" 1 "Active" ;
VAL_ 262 ESS_ENG_ST_W 1 "ENS Stopped / ENS_STOPPED" 2 "ENS Request Start / ENS_RQ_ST" 3 "ENS Running / ENS_RUN" 4 "ENS Stop Pending / ENS_STOP_PEND" 5 "ENS Start protection / ENS_ST_PRTCT" 6 "ENS Start inhibit / ENS_ST_INH" 7 "ENS disabled / ENS_DSBL" 8 "ENS_IHB_LATCH" 9 "ENS Starting / ENS_Starting" 15 "SNA" ;
VAL_ 262 GasPedalPositionFailSts_W 0 "Fail_not_present" 1 "Fail_present" ;
VAL_ 262 PowertrainPrplsnActv 0 "Off" 1 "Active" ;
VAL_ 518 PdlPosActual 255 "SNA" ;
VAL_ 751 TerrainModeStat_ECM 0 "Auto" 1 "Auto_Fault" 2 "Rock" 3 "Track" 4 "Snow" 5 "Offroad" 6 "Eco" 7 "Corsa" 8 "Sport" 9 "Mud_Sand" 10 "Mud" 11 "Sand" 12 "Valet" 13 "Custom" 14 "Tow" 15 "DRAG" 16 "BAJA" 31 "SNA" ;
VAL_ 1448 ECM_THA_Resp 0 "Off" 1 "Active" 3 "SNA" ;
VAL_ 1448 ECM_TRSC_Resp 0 "OFF" 1 "Active" 3 "SNA" ;
VAL_ 1448 EMSFailSts 0 "Fail_Not_Present" 1 "Fail_Flash_Light_Indication" 2 "Fail_Fix_Light_Indication" 3 "Flash_For_Service" ;
VAL_ 1448 ETCFailSts 0 "Fail_Not_Present" 1 "Fail_Flash_Light_Indication" 2 "Fail_Fix_Light_Indication" 3 "Flash_For_Service" ;
VAL_ 1448 SpStDispstat 0 "NONE" 3 "ACTIVE" 1 "PCR_OPENS" 4 "D_OR_SB" 5 "NR_DRV_NOT_DET" 6 "DR_INHIB" 7 "TX_INHIB" 8 "KEY" 9 "BATT" 10 "SYSFLT" 11 "NR" 12 "READY" 13 "OFF" 14 "HOOD" 15 "PEDAL" 16 "BATT_CHG" 17 "TM" 18 "T4WD_L" 20 "INCLINE" 21 "AMB_TEMP" 23 "SB" 24 "DR_AJAR" 25 "CABIN" 26 "MAX_HVAC" 27 "FT_DEFROST" 29 "ST_WHEEL" 30 "Eng_Temp_Hi" 31 "Eng_Temp_Lo" 32 "Prk_Brk_Inhib" 33 "Park_Inhib" 34 "Hood_Inhib" 35 "DPF_Regen" 38 "BATT_HIGH" 63 "SNA" ;
VAL_ 1448 SpStSwStat 0 "OFF" 1 "CONT" 2 "BLINK" 3 "SNA" ;
VAL_ 1055 GF_Charge 65535 "SNA" ;
VAL_ 1055 MAP_4_BAR 511 "SNA" ;
VAL_ 264 ElectricSteeringFailSts 0 "Fail_Not_Present" 1 "Fail_Present" ;
VAL_ 264 EngineFanRequestActivation 0 "False" 1 "True" ;
VAL_ 264 EPS_AsstStat 0 "AST_ACT" 1 "AST_OFF" 2 "AST_RT" 7 "SNA" ;
VAL_ 264 EPS_Curr 255 "SNA" ;
VAL_ 264 EPS_Hands_On_Sts 0 "Not_Detected" 1 "Detected" ;
VAL_ 264 EPS_IMC_Fault 0 "No_Fault" 1 "Fault" ;
VAL_ 264 EPSMotorTorque 2047 "SNA" ;
VAL_ 264 HAS_LAT_CTRL_ResponseSts_2 0 "IDLE" 1 "Permanent_Not_Avail" 2 "Temporarily_Not_Avail" 3 "HAS_Open" 4 "HAS_Open_Backup" 5 "INIT" 6 "Damped_Exit" 7 "Faulted" ;
VAL_ 264 LwsAngle 65535 "SNA" ;
VAL_ 264 LwsAngleType 0 "Absolute" 1 "Relative" 3 "SNA" ;
VAL_ 264 LwsCalibration 0 "Not_calibrated" 1 "Calibrated" ;
VAL_ 264 LwsSpeed 4095 "SNA" ;
VAL_ 264 Steering_Column_Torque 2047 "SNA" ;
VAL_ 264 Steering_OpStat_Sec 0 "Inactive" 1 "FullService" 2 "FailOperational" 3 "FailDegraded" 4 "Emergency" 5 "No_Function" ;
VAL_ 1056 EPS_MODE_STAT 0 "MODE_1" 1 "MODE_2" 2 "MODE_3" 3 "LAST" 7 "SNA" ;
VAL_ 1056 EPS_SteeringTouchStat 0 "False" 1 "True" ;
VAL_ 1056 EPS_SteeringTouq_Resp 0 "OFF" 1 "Active" 3 "SNA" ;
VAL_ 1056 EPS_THA_DriverTorqueOverride 0 "False" 1 "True" 3 "SNA" ;
VAL_ 1056 EPS_THA_SteeringTorqueResp 0 "Temp_NA" 1 "Perm_NA" 2 "TOI_Available" 3 "TOI_Unavailable" 7 "SNA" ;
VAL_ 1056 EPS_Warn_Disp_Rq 0 "EPS function active OK" 1 "Warning - Service power steering ERR" 2 "Warning - Power steering-over temp ERR2" 3 "Service Required - High Priority SERV_HI" 7 "SNA" ;
VAL_ 1056 THA_SteeringTouchStat 0 "Hands Off" 1 "Hands On" 3 "SNA" ;
VAL_ 1460 CADM2_Big_ECU_Package 0 "No Package" 1 "Package Available" ;
VAL_ 1460 FOTA_Purge 0 "Do_Not_Purge" 1 "Purge" ;
VAL_ 1460 FOTA_Status 0 "No FOTA Event" 1 "Downloading Package from Backend" 2 "Passing Images to Big Target ECUs" 3 "Waiting for HMI Acceptance" 4 "Installing FOTA Updated" 5 "Successful FOTA Update" 6 "FOTA Failure Rollback Successful" 7 "FOTA Failure Complete" 8 "Build Vehicle Library" 9 "Check Campaign Availability" 10 "Check Download Conditions" 11 "Validate Vehicle Package" 12 "Double Check Manifest" 13 "Initiate Authenticated Diagnostic session" 14 "Ready_State" 15 "Rollback" ;
VAL_ 1460 Safe_State 0 "Not Safe State" 1 "Safe State" ;
VAL_ 1847 Big_ECU_Ready_CADM2 0 "Not Ready" 1 "Ready for Transfer" 2 "ECU ID not Downloaded" 3 "Ready for Install" ;
VAL_ 1847 Download_Status_CADM2 0 "Not Downloading" 1 "Download in Progress" 2 "Download Completed" 3 "Fault Download Failed" ;
VAL_ 1847 Update_Status_CADM2 0 "Not Updating" 1 "Update in Progress" 2 "Update Completed" 3 "Fault Update Failed" ;
VAL_ 525 GNMM_Health 0 "Not_Avail" 1 "Avail_full_capacity" 2 "Primary_IMU_NA" 3 "GPS_GNSS_NA" 4 "Correction_Data_NA" 7 "SNA" ;
VAL_ 526 Altitude_RMSE_C2 254 "OutOfRange" 255 "SNA" ;
VAL_ 526 DeltaTimestamp_IMUdata 254 "OutOfRange" 255 "SNA" ;
VAL_ 526 Heading_Angle_C2 65535 "SNA" ;
VAL_ 526 LatAcceleration_C2 4095 "SNA" ;
VAL_ 526 Latitude_RMSE_C2 254 "OutOfRange" 255 "SNA" ;
VAL_ 526 LongAcceleration_C2 4095 "SNA" ;
VAL_ 526 Longitude_RMSE_C2 254 "OutOfRange" 255 "SNA" ;
VAL_ 526 Pitch_RMSE_C2 254 "OutOfRange" 255 "SNA" ;
VAL_ 526 PitchRate_C2 4095 "SNA" ;
VAL_ 526 Roll_RMSE_C2 254 "OutOfRange" 255 "SNA" ;
VAL_ 526 RollRate_C2 4095 "SNA" ;
VAL_ 526 VerticalAcceleration_C2 4095 "SNA" ;
VAL_ 526 YawRate_C2 4095 "SNA" ;
VAL_ 526 YawRate_RMSE_C2 254 "OutOfRange" 255 "SNA" ;
VAL_ 266 HVBatContactorSts 0 "Open" 1 "Precharging" 2 "Closed" 3 "Precharge_Failed" 4 "Precharge_Inhibited" 7 "SNA" ;
VAL_ 276 PropulsionSystemActive 0 "Not_Active" 1 "Active" ;
VAL_ 269 BSGActualTorque 1023 "SNA" ;
VAL_ 752 CurrBattFailStatus 0 "Fail_not_present" 1 "Fail_present" ;
VAL_ 752 IBS3_Error_Internal 0 "NO_ERROR" 1 "ERROR" ;
VAL_ 752 IBS3_Vbatt 511 "SNA" ;
VAL_ 752 RsErrIBS3 0 "NO_ERROR" 1 "ERROR" ;
VAL_ 752 VoltBattFailStatus 0 "Fail_not_present" 1 "Fail_present" ;
VAL_ 754 CurrBattFailStatus_2 0 "Fail_not_present" 1 "Fail_present" ;
VAL_ 754 IBS3_Error_Internal_2 0 "NO_ERROR" 1 "ERROR" ;
VAL_ 754 IBS3_Ibatt_2 65535 "SNA" ;
VAL_ 754 IBS3_Vbatt_2 511 "SNA" ;
VAL_ 754 RsErrIBS3_2 0 "NO_ERROR" 1 "ERROR" ;
VAL_ 754 VoltBattFailStatus_2 0 "Fail_not_present" 1 "Fail_present" ;
VAL_ 1955 IBS3_FLAG_DISCONNECT_ADAS 0 "NOT_DISCONNECTED" 1 "DISCONNECTED_DETECTED" 2 "not_used" 3 "SNA" ;
VAL_ 1955 IBS3_FLAG_DISCONNECT_ADAS_2 0 "NOT_DISCONNECTED" 1 "DISCONNECTED_DETECTED" 2 "not_used" 3 "SNA" ;
VAL_ 1955 IBS3_IBS_ADAS_OK 0 "unknown" 1 "OK" 2 "NOT_OK" 3 "SNA" ;
VAL_ 1955 IBS3_IBS_ADAS_OK_2 0 "unknown" 1 "OK" 2 "NOT_OK" 3 "SNA" ;
VAL_ 1955 IBS3_SOC 127 "SNA" ;
VAL_ 1955 IBS3_SOC_Accuracy 0 "Inaccurate" 1 "Accurate" ;
VAL_ 1957 IBS3_FLAG_DISCONNECT_2 0 "No_Disconnect" 1 "Disconnect" ;
VAL_ 1957 IBS3_Q_Received_2 65535 "SNA" ;
VAL_ 1957 IBS3_Q_Released_2 65535 "SNA" ;
VAL_ 1957 IBS3_R_Batt_2 255 "SNA" ;
VAL_ 1957 IBS3_R_Batt_25_2 255 "SNA" ;
VAL_ 1957 IBS3_SOC_2 127 "SNA" ;
VAL_ 1957 IBS3_SOC_Accuracy_2 0 "Inaccurate" 1 "Accurate" ;
VAL_ 1957 IBS3_SOF_Q_2 255 "SNA" ;
VAL_ 1957 IBS3_SOF_Q_Accuracy_2 0 "Inaccurate" 1 "Accurate" ;
VAL_ 1957 IBS3_SOH_COR_2 127 "SNA" ;
VAL_ 1957 IBS3_SOH_COR_Accuracy_2 0 "Inaccurate" 1 "Accurate" ;
VAL_ 1957 IBS3_SOH_Q_2 127 "SNA" ;
VAL_ 1957 IBS3_SOH_Q_Accuracy_2 0 "Inaccurate" 1 "Accurate" ;
VAL_ 1957 IBS3_SOH_SUL_2 127 "SNA" ;
VAL_ 1957 IBS3_SOH_SUL_Accuracy_2 0 "Inaccurate" 1 "Accurate" ;
VAL_ 1957 IBS3_T_BATT_2 255 "SNA" ;
VAL_ 1957 IBS3_TempFailStatus_2 0 "Fail_not_present" 1 "Fail_present" ;
VAL_ 1957 IBS3_TmLstResetDays_2 4095 "SNA" ;
VAL_ 1957 IBS3_TmLstResetSec_2 65535 "SNA" ;
VAL_ 1626 IMPACT_B 0 "Do_Not_Actuate" 1 "Actuate" ;
VAL_ 1626 IMPACT_C 0 "Do_Not_Actuate" 1 "Actuate" ;
VAL_ 1626 IMPACT_F 0 "Do_Not_Actuate" 1 "Actuate" ;
VAL_ 1626 IMPACT_I 0 "Do_Not_Actuate" 1 "Actuate" ;
VAL_ 1626 IMPACT_K 0 "Do_Not_Actuate" 1 "Actuate" ;
VAL_ 1626 IMPACT_M 0 "Do_Not_Actuate" 1 "Actuate" ;
VAL_ 1626 IMPACTCommand 0 "Do_Not_Actuate" 1 "Actuate" ;
VAL_ 1626 IMPACTConfirm 0 "Actuate" 1 "Do_Not_Actuate" ;
VAL_ 1626 IMPACTFailSts 0 "Fail_Not_Present" 1 "Fail_Present" ;
VAL_ 1626 IMPACTThreshold 0 "Threshold_Not_Met" 1 "Threshold_Met" ;
VAL_ 600 AirBagLamp_FailSts 0 "OFF_Fail_not_present" 1 "OFF_Fail_present" 2 "ON_Fail_not_present" 3 "BLINKING_Fail_not_present" ;
VAL_ 1432 HAS_SoH_IPC 0 "No Fault" 1 "Fault" ;
VAL_ 1443 Act_Lane_Mgt 0 "Vib_Only" 1 "Steer_Asst_Only" 2 "Vib_Steer_Asst" ;
VAL_ 1443 Act_Lane_Mgt_Strength 0 "Low" 1 "Medium" 2 "High" ;
VAL_ 1443 Active_Park_Mode 0 "Full_Auto" 1 "Steering_Only" ;
VAL_ 1443 Backup_Cam_Delay 0 "Off" 1 "On" ;
VAL_ 1443 DynamicGrid 0 "Dynamic Gridlines OFF" 1 "Dynamic Gridlines ON" ;
VAL_ 1443 Fwrd_Cam_Guidelines 0 "Off" 1 "On" ;
VAL_ 1443 LanguageSelection 0 "Italian" 1 "Deutsch" 2 "English" 3 "Espanol" 4 "Francais" 5 "Portugues" 6 "Polish" 7 "Dutch" 8 "Brazilian" 9 "Turkish" 10 "Mexican" 11 "English_US" 12 "Canadian" 13 "Russian" 14 "Chinese" 15 "Japanese" 16 "Korean" 17 "Arabic" 18 "Czech" 19 "Slovakian" 20 "Hungarian" 21 "Hindi" ;
VAL_ 1443 LDW_Intensity 0 "Low" 1 "Med" 2 "High" ;
VAL_ 1443 LDW_Sensibility 0 "Early" 1 "Med" 2 "Late" ;
VAL_ 1443 PamChimeVolumeFront 0 "Low" 1 "Medium" 2 "High" ;
VAL_ 1443 PamChimeVolumeRear 0 "Low" 1 "Medium" 2 "High" ;
VAL_ 1443 Rear_Brk_Asst 0 "Warn" 1 "Warn_Braking" ;
VAL_ 1443 SVC_Guidelines 0 "Off" 1 "On" ;
VAL_ 2654486528 CBV_bit0_RepeatMessageRequestBit 0 "Repeat_Message_State_not_requested" 1 "Repeat_Message_State_requested" ;
VAL_ 2654486528 CBV_bit3_NMCoordinatorBit 0 "Start_of_synchronized_shutdown_is_not_requested_by_main_coordinator" 1 "Start_of_synchronized_shutdown_is_requested_by_main_coordinator" ;
VAL_ 2654486528 CBV_bit4_ActiveWakeupBit 0 "PassiveWakeup" 1 "ActiveWakeup" ;
VAL_ 2654486528 CBV_bit6_PartialNtwInfBit 0 "NM_PDU_contains_no_Partial_Network_request_information" 1 "NM_PDU_contains_Partial_Network_request_information" ;
VAL_ 2654486676 CBV_bit0_RepeatMessageRequestBit 0 "Repeat_Message_State_not_requested" 1 "Repeat_Message_State_requested" ;
VAL_ 2654486676 CBV_bit3_NMCoordinatorBit 0 "Start_of_synchronized_shutdown_is_not_requested_by_main_coordinator" 1 "Start_of_synchronized_shutdown_is_requested_by_main_coordinator" ;
VAL_ 2654486676 CBV_bit4_ActiveWakeupBit 0 "PassiveWakeup" 1 "ActiveWakeup" ;
VAL_ 2654486676 CBV_bit6_PartialNtwInfBit 0 "NM_PDU_contains_no_Partial_Network_request_information" 1 "NM_PDU_contains_Partial_Network_request_information" ;
VAL_ 2654486670 CBV_bit0_RepeatMessageRequestBit 0 "Repeat_Message_State_not_requested" 1 "Repeat_Message_State_requested" ;
VAL_ 2654486670 CBV_bit3_NMCoordinatorBit 0 "Start_of_synchronized_shutdown_is_not_requested_by_main_coordinator" 1 "Start_of_synchronized_shutdown_is_requested_by_main_coordinator" ;
VAL_ 2654486670 CBV_bit4_ActiveWakeupBit 0 "PassiveWakeup" 1 "ActiveWakeup" ;
VAL_ 2654486670 CBV_bit6_PartialNtwInfBit 0 "NM_PDU_contains_no_Partial_Network_request_information" 1 "NM_PDU_contains_Partial_Network_request_information" ;
VAL_ 2654486530 CBV_bit0_RepeatMessageRequestBit 0 "Repeat_Message_State_not_requested" 1 "Repeat_Message_State_requested" ;
VAL_ 2654486530 CBV_bit3_NMCoordinatorBit 0 "Start_of_synchronized_shutdown_is_not_requested_by_main_coordinator" 1 "Start_of_synchronized_shutdown_is_requested_by_main_coordinator" ;
VAL_ 2654486530 CBV_bit4_ActiveWakeupBit 0 "PassiveWakeup" 1 "ActiveWakeup" ;
VAL_ 2654486530 CBV_bit6_PartialNtwInfBit 0 "NM_PDU_contains_no_Partial_Network_request_information" 1 "NM_PDU_contains_Partial_Network_request_information" ;
VAL_ 2654486554 CBV_bit0_RepeatMessageRequestBit 0 "Repeat Message State not requested" 1 "Repeat Message State requested" ;
VAL_ 2654486554 CBV_bit3_NMCoordinatorBit 0 "Start of synchronized shutdown is not requested by main coordinator" 1 "Start of synchronized shutdown is requested by main coordinator" ;
VAL_ 2654486554 CBV_bit4_ActiveWakeupBit 0 "PassiveWakeup" 1 "ActiveWakeup" ;
VAL_ 2654486554 CBV_bit6_PartialNtwInfBit 0 "NM PDU contains no Partial Network request information" 1 "NM PDU contains Partial Network request information" ;
VAL_ 2654486552 CBV_bit0_RepeatMessageRequestBit 0 "Repeat_Message_State_not_requested" 1 "Repeat_Message_State_requested" ;
VAL_ 2654486552 CBV_bit3_NMCoordinatorBit 0 "Start_of_synchronized_shutdown_is_not_requested_by_main_coordinator" 1 "Start_of_synchronized_shutdown_is_requested_by_main_coordinator" ;
VAL_ 2654486552 CBV_bit4_ActiveWakeupBit 0 "PassiveWakeup" 1 "ActiveWakeup" ;
VAL_ 2654486552 CBV_bit6_PartialNtwInfBit 0 "NM_PDU_contains_no_Partial_Network_request_information" 1 "NM_PDU_contains_Partial_Network_request_information" ;
VAL_ 2654486640 CBV_bit0_RepeatMessageRequestBit 0 "Repeat_Message_State_not_requested" 1 "Repeat_Message_State_requested" ;
VAL_ 2654486640 CBV_bit3_NMCoordinatorBit 0 "Start_of_synchronized_shutdown_is_not_requested_by_main_coordinator" 1 "Start_of_synchronized_shutdown_is_requested_by_main_coordinator" ;
VAL_ 2654486640 CBV_bit4_ActiveWakeupBit 0 "PassiveWakeup" 1 "ActiveWakeup" ;
VAL_ 2654486640 CBV_bit6_PartialNtwInfBit 0 "NM_PDU_contains_no_Partial_Network_request_information" 1 "NM_PDU_contains_Partial_Network_request_information" ;
VAL_ 2654486705 CBV_bit0_RepeatMessageRequestBit 0 "Repeat_Message_State_not_requested" 1 "Repeat_Message_State_requested" ;
VAL_ 2654486705 CBV_bit3_NMCoordinatorBit 0 "Start_of_synchronized_shutdown_is_not_requested_by_main_coordinator" 1 "Start_of_synchronized_shutdown_is_requested_by_main_coordinator" ;
VAL_ 2654486705 CBV_bit4_ActiveWakeupBit 0 "PassiveWakeup" 1 "ActiveWakeup" ;
VAL_ 2654486705 CBV_bit6_PartialNtwInfBit 0 "NM_PDU_contains_no_Partial_Network_request_information" 1 "NM_PDU_contains_Partial_Network_request_information" ;
VAL_ 611 AirBagFailSts 0 "Fail_Not_Present_Lamp_Off" 1 "Fail_Not_Present_Lamp_Flashing" 2 "Fail_Present_Lamp_On" 3 "Not_Used" ;
VAL_ 611 SBR1RowDriverSeatConfigSts 0 "Seat_Not_Checked" 1 "Seat_Checked" ;
VAL_ 611 SBR1RowDriverSeatSts 0 "Seat_Belt_Fasten" 1 "Seat_Belt_Not_Fasten" 3 "SNA" ;
VAL_ 611 SBR1RowPsngrSeatConfigSts 0 "Seat_Not_Checked" 1 "Seat_Checked" ;
VAL_ 611 SBR1RowPsngrSeatSts 0 "Seat_Belt_Fasten" 1 "Seat_Belt_Not_Fasten" 2 "Seat_Safe" 3 "Seat_Not_Safe" 7 "SNA" ;
